VERSION ""

NS_ :

BS_:

BU_: ACU WPTC MCU OBC DCDC BMS VCU GW

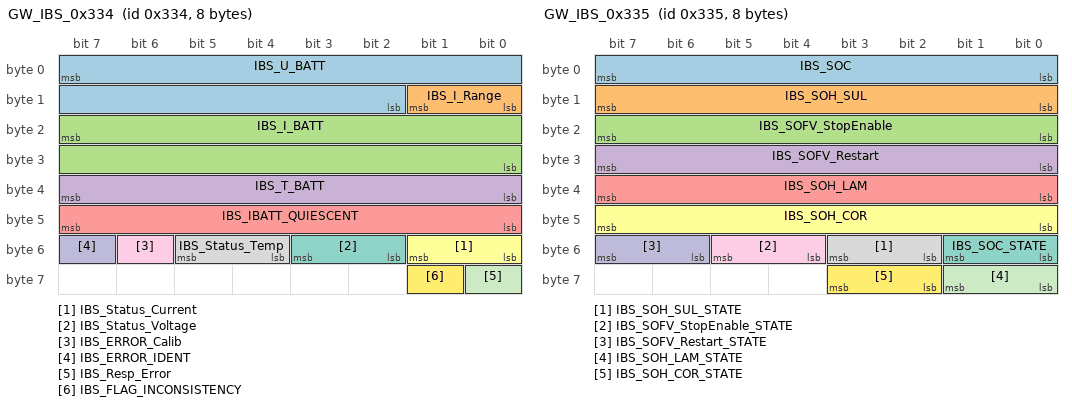
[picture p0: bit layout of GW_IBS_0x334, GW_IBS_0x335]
BO_ 820 GW_IBS_0x334: 8 GW
 SG_ IBS_U_BATT : 7|14@0+ (0.0009765625,3) [3|18] "V" VCU
 SG_ IBS_I_Range : 9|2@0+ (1,0) [0|3] "" Vector__XXX
 SG_ IBS_I_BATT : 23|16@0+ (1,-32768) [-32768|32766] "A" Vector__XXX
 SG_ IBS_T_BATT : 39|8@0+ (1,-40) [-40|105] "°C" Vector__XXX
 SG_ IBS_IBATT_QUIESCENT : 47|8@0+ (0.00390625,0) [0|0.984375] "A" Vector__XXX
 SG_ IBS_Status_Current : 49|2@0+ (1,0) [0|3] "" Vector__XXX
 SG_ IBS_Status_Voltage : 51|2@0+ (1,0) [0|3] "" VCU
 SG_ IBS_Status_Temp : 53|2@0+ (1,0) [0|3] "" Vector__XXX
 SG_ IBS_ERROR_Calib : 54|1@0+ (1,0) [0|1] "" Vector__XXX
 SG_ IBS_ERROR_IDENT : 55|1@0+ (1,0) [0|1] "" Vector__XXX
 SG_ IBS_Resp_Error : 56|1@0+ (1,0) [0|1] "" Vector__XXX
 SG_ IBS_FLAG_INCONSISTENCY : 57|1@0+ (1,0) [0|1] "" Vector__XXX

BO_ 821 GW_IBS_0x335: 8 GW
 SG_ IBS_SOC : 7|8@0+ (1,0) [0|100] "%" VCU
 SG_ IBS_SOH_SUL : 15|8@0+ (1,0) [0|100] "%" VCU
 SG_ IBS_SOFV_StopEnable : 23|8@0+ (0.0625,0) [0|15.875] "V" Vector__XXX
 SG_ IBS_SOFV_Restart : 31|8@0+ (0.0625,0) [0|15.875] "V" Vector__XXX
 SG_ IBS_SOH_LAM : 39|8@0+ (0.5,0) [0|127] "Ah" VCU
 SG_ IBS_SOH_COR : 47|8@0+ (0.0625,0) [0|15.875] "V" VCU
 SG_ IBS_SOC_STATE : 49|2@0+ (1,0) [0|3] "" VCU
 SG_ IBS_SOH_SUL_STATE : 51|2@0+ (1,0) [0|3] "" VCU
 SG_ IBS_SOFV_StopEnable_STATE : 53|2@0+ (1,0) [0|3] "" Vector__XXX
 SG_ IBS_SOFV_Restart_STATE : 55|2@0+ (1,0) [0|3] "" Vector__XXX
 SG_ IBS_SOH_LAM_STATE : 57|2@0+ (1,0) [0|3] "" VCU
 SG_ IBS_SOH_COR_STATE : 59|2@0+ (1,0) [0|3] "" VCU

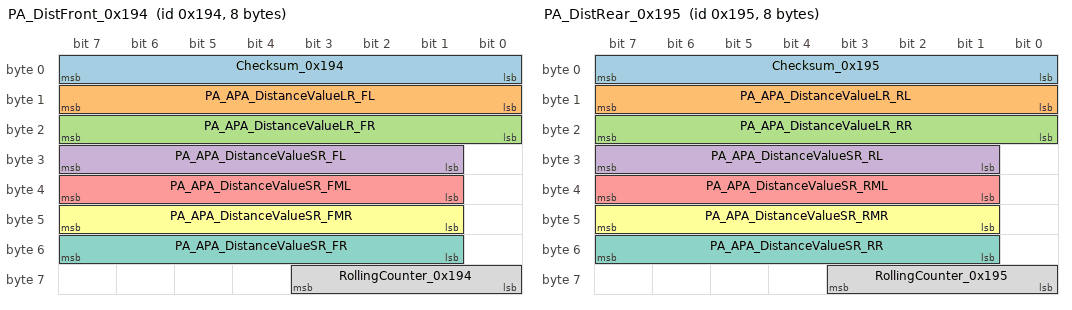
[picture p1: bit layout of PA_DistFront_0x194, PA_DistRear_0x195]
BO_ 404 PA_DistFront_0x194: 8 GW
 SG_ Checksum_0x194 : 7|8@0+ (1,0) [0|255] "" VCU
 SG_ PA_APA_DistanceValueLR_FL : 15|8@0+ (2,0) [0|500] "cm" VCU
 SG_ PA_APA_DistanceValueLR_FR : 23|8@0+ (2,0) [0|500] "cm" VCU
 SG_ PA_APA_DistanceValueSR_FL : 31|7@0+ (2,0) [0|250] "cm" VCU
 SG_ PA_APA_DistanceValueSR_FML : 39|7@0+ (2,0) [0|250] "cm" VCU
 SG_ PA_APA_DistanceValueSR_FMR : 47|7@0+ (2,0) [0|250] "cm" VCU
 SG_ PA_APA_DistanceValueSR_FR : 55|7@0+ (2,0) [0|250] "cm" VCU
 SG_ RollingCounter_0x194 : 59|4@0+ (1,0) [0|15] "" VCU

BO_ 405 PA_DistRear_0x195: 8 GW
 SG_ Checksum_0x195 : 7|8@0+ (1,0) [0|255] "" VCU
 SG_ PA_APA_DistanceValueLR_RL : 15|8@0+ (2,0) [0|500] "cm" VCU
 SG_ PA_APA_DistanceValueLR_RR : 23|8@0+ (2,0) [0|500] "cm" VCU
 SG_ PA_APA_DistanceValueSR_RL : 31|7@0+ (2,0) [0|250] "cm" VCU
 SG_ PA_APA_DistanceValueSR_RML : 39|7@0+ (2,0) [0|250] "cm" VCU
 SG_ PA_APA_DistanceValueSR_RMR : 47|7@0+ (2,0) [0|250] "cm" VCU
 SG_ PA_APA_DistanceValueSR_RR : 55|7@0+ (2,0) [0|250] "cm" VCU
 SG_ RollingCounter_0x195 : 59|4@0+ (1,0) [0|15] "" VCU

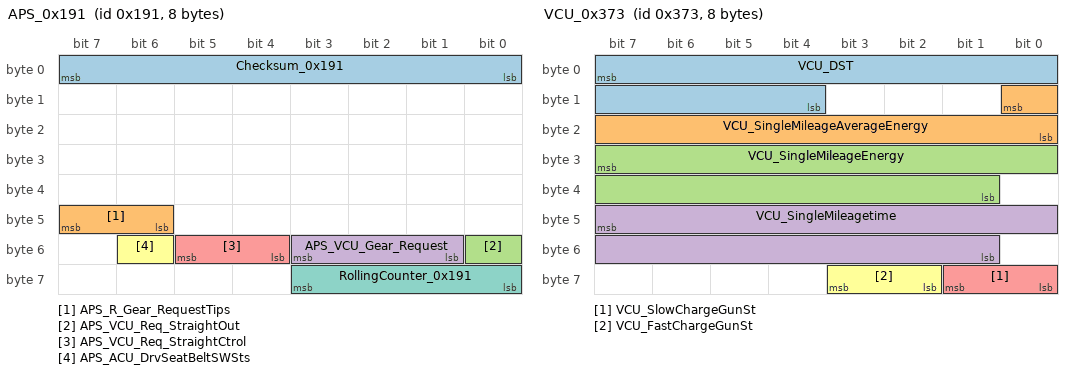
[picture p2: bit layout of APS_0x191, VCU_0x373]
BO_ 401 APS_0x191: 8 GW
 SG_ Checksum_0x191 : 7|8@0+ (1,0) [0|255] "" Vector__XXX
 SG_ APS_R_Gear_RequestTips : 47|2@0+ (1,0) [0|3] "" VCU
 SG_ APS_VCU_Req_StraightOut : 48|1@0+ (1,0) [0|1] "" VCU
 SG_ APS_VCU_Gear_Request : 51|3@0+ (1,0) [0|7] "" Vector__XXX
 SG_ APS_VCU_Req_StraightCtrol : 53|2@0+ (1,0) [0|3] "" VCU
 SG_ APS_ACU_DrvSeatBeltSWSts : 54|1@0+ (1,0) [0|1] "" Vector__XXX
 SG_ RollingCounter_0x191 : 59|4@0+ (1,0) [0|15] "" Vector__XXX

BO_ 599 AC_0x257: 8 GW
 SG_ AC_RemoteAC : 2|3@0+ (1,0) [0|7] "" VCU

BO_ 1323 VCU_0x52B: 8 VCU
 SG_ VCU_State0 : 7|8@0+ (1,0) [0|255] "" GW
 SG_ VCU_State1 : 15|8@0+ (1,0) [0|255] "" GW
 SG_ VCU_State2 : 23|8@0+ (1,0) [0|255] "" GW
 SG_ VCU_State3 : 31|8@0+ (1,0) [0|255] "" GW
 SG_ VCU_State4 : 39|8@0+ (1,0) [0|255] "" GW
 SG_ VCU_State5 : 47|8@0+ (1,0) [0|255] "" GW
 SG_ VCU_State6 : 55|8@0+ (1,0) [0|255] "" GW
 SG_ VCU_State7 : 63|8@0+ (1,0) [0|255] "" GW

BO_ 1325 VCU_0x52D: 8 VCU
 SG_ VCU_ErrorCode0 : 7|8@0+ (1,0) [0|255] "" GW
 SG_ VCU_ErrorCode1 : 15|8@0+ (1,0) [0|255] "" GW
 SG_ VCU_ErrorCode2 : 23|8@0+ (1,0) [0|255] "" GW
 SG_ VCU_ErrorCode3 : 31|8@0+ (1,0) [0|255] "" GW
 SG_ VCU_ErrorCode4 : 39|8@0+ (1,0) [0|255] "" GW
 SG_ VCU_ErrorCode5 : 47|8@0+ (1,0) [0|255] "" GW
 SG_ VCU_ErrorCode6 : 55|8@0+ (1,0) [0|255] "" GW
 SG_ VCU_ErrorCode7 : 63|8@0+ (1,0) [0|255] "" GW

BO_ 1326 VCU_0x52E: 8 VCU
 SG_ VCU_ErrorCode8 : 7|8@0+ (1,0) [0|255] "" GW
 SG_ VCU_ErrorCode9 : 15|8@0+ (1,0) [0|255] "" GW
 SG_ VCU_ErrorCode10 : 23|8@0+ (1,0) [0|255] "" GW
 SG_ VCU_ErrorCode11 : 31|8@0+ (1,0) [0|255] "" GW
 SG_ VCU_ErrorCode12 : 39|8@0+ (1,0) [0|255] "" GW
 SG_ VCU_ErrorCode13 : 47|8@0+ (1,0) [0|255] "" GW
 SG_ VCU_ErrorCode14 : 55|8@0+ (1,0) [0|255] "" GW
 SG_ VCU_ErrorCode15 : 63|8@0+ (1,0) [0|255] "" GW

BO_ 1327 VCU_0x52F: 8 VCU
 SG_ VCU_ErrorCode16 : 7|8@0+ (1,0) [0|255] "" GW
 SG_ VCU_ErrorCode17 : 15|8@0+ (1,0) [0|255] "" GW
 SG_ VCU_ErrorCode18 : 23|8@0+ (1,0) [0|255] "" GW
 SG_ VCU_ErrorCode19 : 31|8@0+ (1,0) [0|255] "" GW
 SG_ VCU_ErrorCode20 : 39|8@0+ (1,0) [0|255] "" GW
 SG_ VCU_ErrorCode21 : 47|8@0+ (1,0) [0|255] "" GW
 SG_ VCU_ErrorCode22 : 55|8@0+ (1,0) [0|255] "" GW
 SG_ VCU_ErrorCode23 : 63|8@0+ (1,0) [0|255] "" GW

BO_ 1379 VCU_0x563: 8 VCU
 SG_ VCU_CCOut : 23|1@0+ (1,0) [0|1] "" GW
 SG_ VCU_MotorPumpFB_PWM : 30|7@0+ (1,0) [0|100] "%" GW
 SG_ VCU_FastCharge_A : 31|1@0+ (1,0) [0|1] "" GW
 SG_ VCU_CC2 : 39|8@0+ (0.1,0) [0|25.4] "V" GW
 SG_ VCU_BatPumpFB_PWM : 47|7@0+ (1,0) [0|100] "%" GW

BO_ 596 AC_0x254: 8 GW
 SG_ AC_WindModeSts : 26|3@0+ (1,0) [0|7] "" VCU
 SG_ AC_OutTemperature : 47|8@0+ (0.5,-40) [-40|80] "℃" VCU

BO_ 597 AC_0x255: 8 GW
 SG_ AC_VCU_FanPWMReq : 46|7@0+ (1,0) [0|100] "%" VCU
 SG_ AC_VCU_APTCPwrReq : 54|7@0+ (0.1,0) [0|12.7] "" VCU
 SG_ AC_VCU_EACPwrReq : 62|7@0+ (0.1,0) [0|12.7] "" VCU

BO_ 800 EAC_0x320: 8 GW
 SG_ EAC_power : 6|7@0+ (0.1,0) [0|12.7] "KW" BMS,VCU
 SG_ EAC_Status : 15|2@0+ (1,0) [0|3] "" BMS,VCU

BO_ 806 APTC_0x326: 8 GW
 SG_ APTC_WorkSts : 1|2@0+ (1,0) [0|3] "" VCU
 SG_ APTC_WorkPower : 14|7@0+ (0.1,0) [0|12.7] "KW" VCU
 SG_ APTC_ErrorLevel : 49|2@0+ (1,0) [0|3] "" VCU

BO_ 582 MPC_0x246: 8 GW
 SG_ MPC_LKS_LeftVisualization : 35|3@0+ (1,0) [0|7] "" VCU
 SG_ MPC_LKS_RightVisualization : 38|3@0+ (1,0) [0|7] "" VCU

BO_ 144 BCM_0x90: 8 GW
 SG_ BCM_ReAuthRequest : 0|1@0+ (1,0) [0|1] "" MCU

BO_ 851 TBOX_0x353: 8 GW
 SG_ Checksum_0x353 : 7|8@0+ (1,0) [0|255] "" VCU
 SG_ TBOX_VCU_12vChargeReq : 16|1@0+ (1,0) [0|1] "" VCU
 SG_ TBOX_VCU_TimeCharge : 18|2@0+ (1,0) [0|3] "" VCU
 SG_ TBOX_ChargeDepthSet : 21|2@0+ (1,0) [0|3] "" VCU
 SG_ TBOX_VCU_RemoteChrgLock : 46|1@0+ (1,0) [0|1] "" VCU
 SG_ RollingCounter_0x353 : 59|4@0+ (1,0) [0|15] "" VCU

BO_ 881 VCU_0x371: 8 VCU
 SG_ VCU_instantaneous_Energy : 7|12@0+ (0.1,-204.7) [-204.7|204.6] "" GW
 SG_ VCU_instantaneous_EnergyUnit : 8|1@0+ (1,0) [0|1] "" GW
 SG_ VCU_TrailerMode : 9|1@0+ (1,0) [0|1] "" GW
 SG_ VCU_trip : 31|12@0+ (1,0) [0|4095] "km" GW
 SG_ VCU_ChargeIncreaseMileage : 50|11@0+ (1,0) [0|2046] "km" GW

BO_ 882 VCU_0x372: 8 VCU
 SG_ VCU_SubtotalAverageEnergy : 7|9@0+ (0.1,0) [0|51] "kwh/100km" GW
 SG_ VCU_SubtotalEnergy : 23|15@0+ (0.1,0) [0|3276.6] "kwh" GW
 SG_ VCU_Subtotaltime : 39|15@0+ (1,0) [0|32766] "min" GW
 SG_ VCU_ChargeIncreaseMileageSpeed : 51|12@0+ (1,0) [0|2046] "km/h" GW

BO_ 883 VCU_0x373: 8 VCU
 SG_ VCU_DST : 7|12@0+ (1,0) [0|4095] "km" GW
 SG_ VCU_SingleMileageAverageEnergy : 8|9@0+ (0.1,0) [0|51] "kwh/100km" GW
 SG_ VCU_SingleMileageEnergy : 31|15@0+ (0.1,0) [0|3276.5] "kwh" GW
 SG_ VCU_SingleMileagetime : 47|15@0+ (1,0) [0|32765] "min" GW
 SG_ VCU_SlowChargeGunSt : 57|2@0+ (1,0) [0|3] "" GW
 SG_ VCU_FastChargeGunSt : 59|2@0+ (1,0) [0|3] "" GW

BO_ 32 MCU_AuthReq_0x20: 8 MCU
 SG_ MCU_AuthReq_BCM_Code : 7|64@0+ (1,0) [0|255] "" GW

BO_ 33 BCM_AuthResp_0x21: 8 GW
 SG_ BCM_AuthResp_MCU_Code : 7|64@0+ (1,0) [0|255] "" MCU

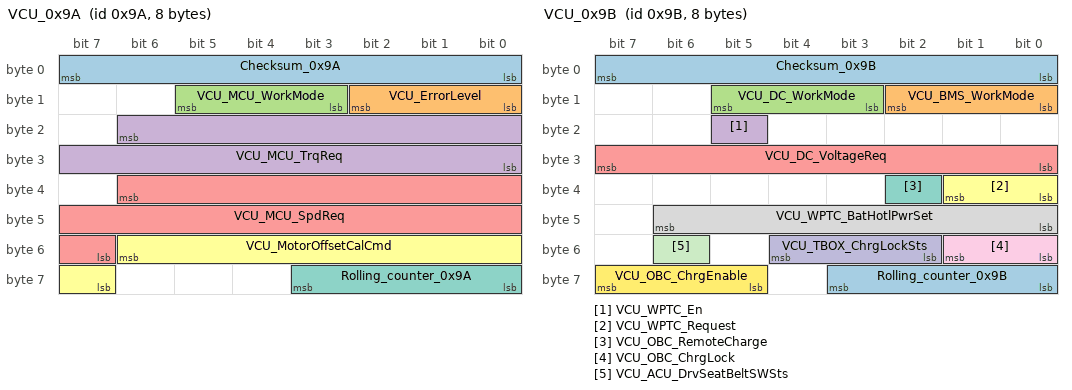
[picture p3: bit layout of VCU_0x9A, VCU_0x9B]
BO_ 154 VCU_0x9A: 8 VCU
 SG_ Checksum_0x9A : 7|8@0+ (1,0) [0|255] "" MCU,GW
 SG_ VCU_ErrorLevel : 10|3@0+ (1,0) [0|7] "" MCU,GW
 SG_ VCU_MCU_WorkMode : 13|3@0+ (1,0) [0|7] "" MCU,GW
 SG_ VCU_MCU_TrqReq : 22|15@0+ (0.1,-1000) [-1000|1000] "NM" MCU,GW
 SG_ VCU_MCU_SpdReq : 38|16@0+ (1,-32767) [-32767|32768] "RPM" MCU,GW
 SG_ VCU_MotorOffsetCalCmd : 54|8@0+ (1,0) [0|255] "" MCU,GW
 SG_ Rolling_counter_0x9A : 59|4@0+ (1,0) [0|15] "" MCU,GW

BO_ 155 VCU_0x9B: 8 VCU
 SG_ Checksum_0x9B : 7|8@0+ (1,0) [0|255] "" OBC,BMS,GW
 SG_ VCU_BMS_WorkMode : 10|3@0+ (1,0) [0|7] "" BMS,GW
 SG_ VCU_DC_WorkMode : 13|3@0+ (1,0) [0|7] "" DCDC,GW
 SG_ VCU_WPTC_En : 21|1@0+ (1,0) [0|1] "" WPTC,GW
 SG_ VCU_DC_VoltageReq : 31|8@0+ (0.1,0) [12|16] "V" DCDC,GW
 SG_ VCU_WPTC_Request : 33|2@0+ (1,0) [0|3] "" WPTC,GW
 SG_ VCU_OBC_RemoteCharge : 34|1@0+ (1,0) [0|1] "" OBC,GW
 SG_ VCU_WPTC_BatHotlPwrSet : 46|7@0+ (0.1,0) [0|12] "" WPTC,GW
 SG_ VCU_OBC_ChrgLock : 49|2@0+ (1,0) [0|3] "" OBC
 SG_ VCU_TBOX_ChrgLockSts : 52|3@0+ (1,0) [0|7] "" GW
 SG_ VCU_ACU_DrvSeatBeltSWSts : 54|1@0+ (1,0) [0|1] "" ACU
 SG_ VCU_OBC_ChrgEnable : 63|3@0+ (1,0) [0|7] "" OBC,GW
 SG_ Rolling_counter_0x9B : 59|4@0+ (1,0) [0|15] "" OBC,BMS,GW

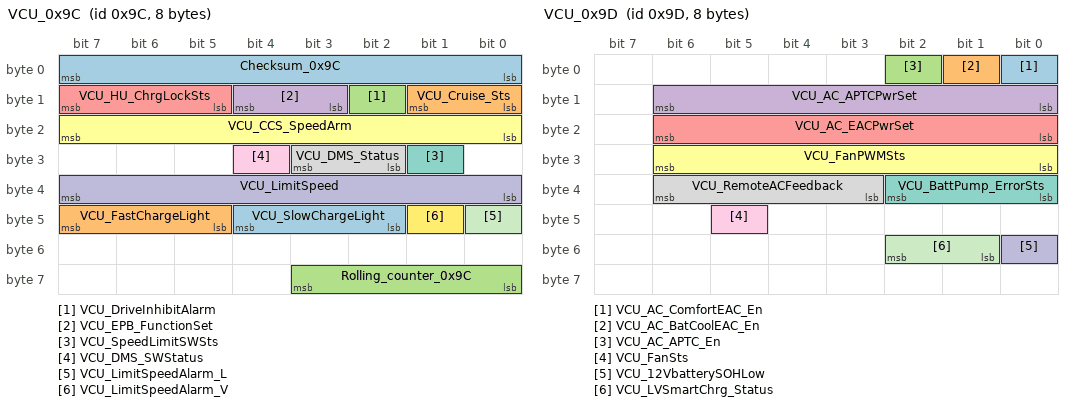
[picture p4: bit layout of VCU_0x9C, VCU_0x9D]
BO_ 156 VCU_0x9C: 8 VCU
 SG_ Checksum_0x9C : 7|8@0+ (1,0) [0|255] "" GW
 SG_ VCU_Cruise_Sts : 9|2@0+ (1,0) [0|3] "" GW
 SG_ VCU_DriveInhibitAlarm : 10|1@0+ (1,0) [0|1] "" GW
 SG_ VCU_EPB_FunctionSet : 12|2@0+ (1,0) [0|3] "" GW
 SG_ VCU_HU_ChrgLockSts : 15|3@0+ (1,0) [0|7] "" GW
 SG_ VCU_CCS_SpeedArm : 23|8@0+ (1,0) [0|200] "km/h" GW
 SG_ VCU_SpeedLimitSWSts : 25|1@0+ (1,0) [0|1] "" GW
 SG_ VCU_DMS_Status : 27|2@0+ (1,0) [0|3] "" GW
 SG_ VCU_DMS_SWStatus : 28|1@0+ (1,0) [0|1] "" GW
 SG_ VCU_LimitSpeed : 39|8@0+ (1,0) [0|200] "" GW
 SG_ VCU_LimitSpeedAlarm_L : 40|1@0+ (1,0) [0|1] "" GW
 SG_ VCU_LimitSpeedAlarm_V : 41|1@0+ (1,0) [0|1] "" GW
 SG_ VCU_SlowChargeLight : 44|3@0+ (1,0) [0|7] "" GW
 SG_ VCU_FastChargeLight : 47|3@0+ (1,0) [0|7] "" GW
 SG_ Rolling_counter_0x9C : 59|4@0+ (1,0) [0|15] "" GW

BO_ 157 VCU_0x9D: 8 VCU
 SG_ VCU_AC_ComfortEAC_En : 0|1@0+ (1,0) [0|1] "" GW
 SG_ VCU_AC_BatCoolEAC_En : 1|1@0+ (1,0) [0|1] "" GW
 SG_ VCU_AC_APTC_En : 2|1@0+ (1,0) [0|1] "" GW
 SG_ VCU_AC_APTCPwrSet : 14|7@0+ (0.1,0) [0|12.7] "KW" GW
 SG_ VCU_AC_EACPwrSet : 22|7@0+ (0.1,0) [0|12.7] "KW" GW
 SG_ VCU_FanPWMSts : 30|7@0+ (1,0) [0|100] "%" GW
 SG_ VCU_BattPump_ErrorSts : 34|3@0+ (1,0) [0|7] "" BMS,GW
 SG_ VCU_RemoteACFeedback : 38|4@0+ (1,0) [0|15] "" GW
 SG_ VCU_FanSts : 45|1@0+ (1,0) [0|1] "" GW
 SG_ VCU_12VbatterySOHLow : 48|1@0+ (1,0) [0|1] "" GW
 SG_ VCU_LVSmartChrg_Status : 50|2@0+ (1,0) [0|3] "" GW

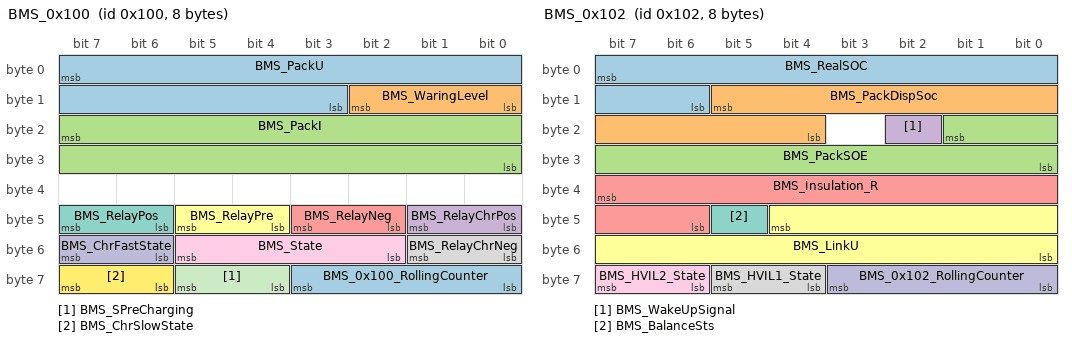
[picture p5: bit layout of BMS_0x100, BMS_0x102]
BO_ 256 BMS_0x100: 8 BMS
 SG_ BMS_PackU : 7|13@0+ (0.1,0) [0|800] "V" MCU,VCU,GW
 SG_ BMS_WaringLevel : 10|3@0+ (1,0) [0|7] "" VCU,GW
 SG_ BMS_PackI : 23|16@0+ (0.1,-1000) [-1000|1000] "A" VCU,GW
 SG_ BMS_RelayChrPos : 41|2@0+ (1,0) [0|3] "" VCU,GW
 SG_ BMS_RelayNeg : 43|2@0+ (1,0) [0|3] "" MCU,VCU,GW
 SG_ BMS_RelayPre : 45|2@0+ (1,0) [0|3] "" VCU,GW
 SG_ BMS_RelayPos : 47|2@0+ (1,0) [0|3] "" MCU,VCU,GW
 SG_ BMS_RelayChrNeg : 49|2@0+ (1,0) [0|3] "" VCU,GW
 SG_ BMS_State : 53|4@0+ (1,0) [0|15] "" VCU,GW
 SG_ BMS_ChrFastState : 55|2@0+ (1,0) [0|3] "" VCU,GW
 SG_ BMS_SPreCharging : 61|2@0+ (1,0) [0|3] "" GW
 SG_ BMS_ChrSlowState : 63|2@0+ (1,0) [0|3] "" VCU,GW
 SG_ BMS_0x100_RollingCounter : 59|4@0+ (1,0) [0|15] "" VCU,GW

BO_ 258 BMS_0x102: 8 BMS
 SG_ BMS_RealSOC : 7|10@0+ (0.1,0) [0|100] "%" VCU,GW
 SG_ BMS_PackDispSoc : 13|10@0+ (0.1,0) [0|100] "%" VCU,GW
 SG_ BMS_PackSOE : 17|10@0+ (0.1,0) [0|102.3] "kwh" VCU,GW
 SG_ BMS_WakeUpSignal : 18|1@0+ (1,0) [0|1] "" Vector__XXX
 SG_ BMS_Insulation_R : 39|10@0+ (1,0) [0|1000] "KΩ" GW
 SG_ BMS_LinkU : 44|13@0+ (0.1,0) [0|800] "V" VCU,GW
 SG_ BMS_BalanceSts : 45|1@0+ (1,0) [0|1] "" GW
 SG_ BMS_HVIL1_State : 61|2@0+ (1,0) [0|3] "" VCU,GW
 SG_ BMS_HVIL2_State : 63|2@0+ (1,0) [0|3] "" VCU,GW
 SG_ BMS_0x102_RollingCounter : 59|4@0+ (1,0) [0|15] "" VCU,GW

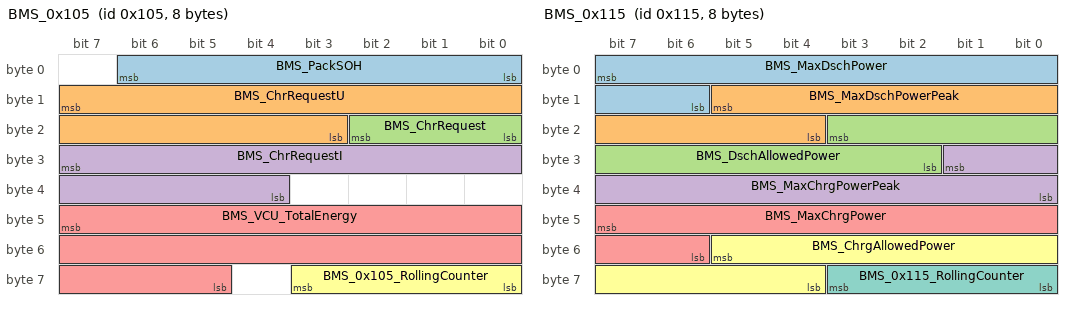
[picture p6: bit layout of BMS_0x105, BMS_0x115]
BO_ 261 BMS_0x105: 8 BMS
 SG_ BMS_PackSOH : 6|7@0+ (1,0) [0|100] "%" Vector__XXX
 SG_ BMS_ChrRequestU : 15|13@0+ (0.1,0) [0|800] "V" OBC,GW
 SG_ BMS_ChrRequest : 18|3@0+ (1,0) [0|7] "" OBC,GW
 SG_ BMS_ChrRequestI : 31|12@0+ (0.1,0) [0|400] "A" OBC,GW
 SG_ BMS_VCU_TotalEnergy : 47|19@0+ (1,0) [0|524286] "kwh" VCU,GW
 SG_ BMS_0x105_RollingCounter : 59|4@0+ (1,0) [0|15] "" OBC,GW

BO_ 274 BMS_0x112: 8 BMS
 SG_ BMS_MaxCellNo : 7|8@0+ (1,0) [0|255] "" GW
 SG_ BMS_MaxCellU : 15|13@0+ (1,0) [0|5000] "mV" GW
 SG_ BMS_MinCellNo : 31|8@0+ (1,0) [0|255] "" GW
 SG_ BMS_MinCellU : 39|13@0+ (1,0) [0|5000] "mV" GW
 SG_ BMS_CellVolDev : 55|12@0+ (1,0) [0|4000] "mV" GW
 SG_ BMS_0x112_RollingCounter : 59|4@0+ (1,0) [0|15] "" GW

BO_ 277 BMS_0x115: 8 BMS
 SG_ BMS_MaxDschPower : 7|10@0+ (0.25,0) [0|250] "KW" GW
 SG_ BMS_MaxDschPowerPeak : 13|10@0+ (0.25,0) [0|250] "KW" GW
 SG_ BMS_DschAllowedPower : 19|10@0+ (0.25,0) [0|250] "KW" VCU,GW
 SG_ BMS_MaxChrgPowerPeak : 25|10@0+ (0.25,0) [0|250] "KW" GW
 SG_ BMS_MaxChrgPower : 47|10@0+ (0.25,0) [0|250] "KW" GW
 SG_ BMS_ChrgAllowedPower : 53|10@0+ (0.25,0) [0|250] "KW" VCU,GW
 SG_ BMS_0x115_RollingCounter : 59|4@0+ (1,0) [0|15] "" GW

BO_ 278 BMS_0x116: 8 BMS
 SG_ BMS_CellOverVolWaring : 1|2@0+ (1,0) [0|3] "" GW
 SG_ BMS_CellUnderVolWaring : 3|2@0+ (1,0) [0|3] "" GW
 SG_ BMS_TempOverWaring : 5|2@0+ (1,0) [0|3] "" GW
 SG_ BMS_TempUnderWaring : 7|2@0+ (1,0) [0|3] "" GW
 SG_ BMS_CellVolDevWaring : 9|2@0+ (1,0) [0|3] "" GW
 SG_ BMS_TempDveWaring : 11|2@0+ (1,0) [0|3] "" GW
 SG_ BMS_BattOverVolWaring : 13|2@0+ (1,0) [0|3] "" GW
 SG_ BMS_BattUnderVolWaring : 15|2@0+ (1,0) [0|3] "" GW
 SG_ BMS_DCChargePlugTempOverHigh : 16|1@0+ (1,0) [0|1] "" GW
 SG_ BMS_DisCharOverCurr : 18|2@0+ (1,0) [0|3] "" GW
 SG_ BMS_RegenOverCurr : 20|2@0+ (1,0) [0|3] "" GW
 SG_ BMS_InnerCANTimeout : 21|1@0+ (1,0) [0|1] "" GW
 SG_ BMS_ISOWaring : 23|2@0+ (1,0) [0|3] "" VCU,GW
 SG_ BMS_BCUHWFault : 24|1@0+ (1,0) [0|1] "" GW
 SG_ BMS_NegRelayFault : 26|2@0+ (1,0) [0|3] "" GW
 SG_ BMS_PosRelayFault : 28|2@0+ (1,0) [0|3] "" GW
 SG_ BMS_PreRelayFault : 30|2@0+ (1,0) [0|3] "" GW
 SG_ BMS_LowVoltageMSD : 31|1@0+ (1,0) [0|1] "" GW
 SG_ BMS_CharPosRelayFault : 33|2@0+ (1,0) [0|3] "" GW
 SG_ BMS_CharNegRelayFault : 35|2@0+ (1,0) [0|3] "" GW
 SG_ BMS_BMUFault : 36|1@0+ (1,0) [0|1] "" GW
 SG_ BMS_VcuCANTimeout : 37|1@0+ (1,0) [0|1] "" GW
 SG_ BMS_BattHVDisaccord : 38|1@0+ (1,0) [0|1] "" GW
 SG_ BMS_SOClow : 41|2@0+ (1,0) [0|3] "" GW
 SG_ BMS_Mismatch : 42|1@0+ (1,0) [0|1] "" GW
 SG_ BMS_SOCOverHigh : 43|1@0+ (1,0) [0|1] "" GW
 SG_ BMS_BattOverCharge : 44|1@0+ (1,0) [0|1] "" GW
 SG_ BMS_SOCSkip : 45|1@0+ (1,0) [0|1] "" GW
 SG_ BMS_CGOverCurr : 46|1@0+ (1,0) [0|1] "" GW
 SG_ BMS_LowVoltageFault : 47|1@0+ (1,0) [0|1] "" GW
 SG_ BMS_LiquidLeak : 48|1@0+ (1,0) [0|1] "" GW
 SG_ BMS_CrashFault : 49|1@0+ (1,0) [0|1] "" GW
 SG_ BMS_ThermRunAway : 50|1@0+ (1,0) [0|1] "" GW
 SG_ BMS_Maintenance : 52|2@0+ (1,0) [0|3] "" GW
 SG_ BMS_BusbarTempOverWaring : 53|1@0+ (1,0) [0|1] "" GW
 SG_ BMS_FuseFault : 54|1@0+ (1,0) [0|1] "" GW
 SG_ BMS_CurrSensorFault : 61|2@0+ (1,0) [0|3] "" GW
 SG_ BMS_0x116_RollingCounter : 59|4@0+ (1,0) [0|15] "" GW

BO_ 276 BMS_0x114: 8 BMS
 SG_ BMS_thermalControlReq : 10|3@0+ (1,0) [0|7] "" VCU
 SG_ BMS_ThermalCtrlTargetTemp : 23|8@0+ (1,-40) [-40|85] "℃" VCU
 SG_ BMS_InputWaterTemp : 31|8@0+ (0.5,-40) [-40|85] "℃" VCU
 SG_ BMS_OutputWaterTemp : 39|8@0+ (0.5,-40) [-40|85] "℃" VCU
 SG_ BMS_BattThermalReqLvl : 47|8@0+ (1,0) [0|15] "" VCU
 SG_ BMS_0x114_RollingCounter : 59|4@0+ (1,0) [0|15] "" VCU

BO_ 279 VCU_0x117: 8 VCU
 SG_ VCU_thermalControlReq : 10|3@0+ (1,0) [0|7] "" GW
 SG_ VCU_InputWaterTemp : 31|8@0+ (0.5,-40) [-40|85] "℃" GW
 SG_ VCU_OutputWaterTemp : 39|8@0+ (0.5,-40) [-40|85] "℃" GW
 SG_ VCU_BattThermalReqLvl : 47|8@0+ (1,0) [0|15] "" GW
 SG_ VCU_RecoTiming : 54|7@0+ (1,0) [0|120] "" GW

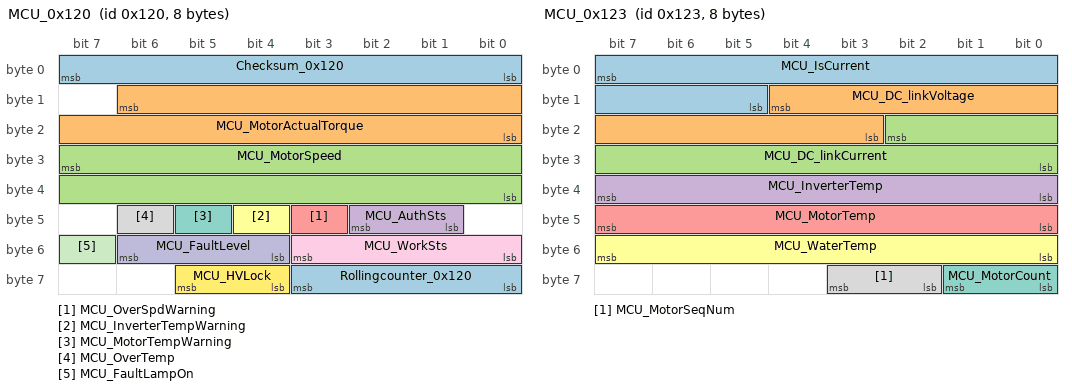
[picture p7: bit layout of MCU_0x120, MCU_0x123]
BO_ 288 MCU_0x120: 8 MCU
 SG_ Checksum_0x120 : 7|8@0+ (1,0) [0|255] "" GW
 SG_ MCU_MotorActualTorque : 14|15@0+ (0.1,-1000) [-1000|1000] "NM" GW
 SG_ MCU_MotorSpeed : 31|16@0+ (1,-32767) [-32767|32768] "RPM" GW
 SG_ MCU_AuthSts : 42|2@0+ (1,0) [0|3] "" GW
 SG_ MCU_OverSpdWarning : 43|1@0+ (1,0) [0|1] "" GW
 SG_ MCU_InverterTempWarning : 44|1@0+ (1,0) [0|1] "" GW
 SG_ MCU_MotorTempWarning : 45|1@0+ (1,0) [0|1] "" GW
 SG_ MCU_OverTemp : 46|1@0+ (1,0) [0|1] "" GW
 SG_ MCU_WorkSts : 51|4@0+ (1,0) [0|15] "" GW
 SG_ MCU_FaultLevel : 54|3@0+ (1,0) [0|7] "" GW
 SG_ MCU_FaultLampOn : 55|1@0+ (1,0) [0|1] "" GW
 SG_ MCU_HVLock : 61|2@0+ (1,0) [0|3] "" GW
 SG_ Rollingcounter_0x120 : 59|4@0+ (1,0) [0|15] "" GW

BO_ 289 ESP_0x121: 8 GW
 SG_ Checksum_0x121 : 7|8@0+ (1,0) [0|255] "" VCU
 SG_ ESP_VehicleSpeed : 11|12@0+ (0.05625,0) [0|230.28749] "kph" ACU,MCU,BMS,VCU
 SG_ ESP_VehicleSpeed_Valid : 12|1@0+ (1,0) [0|1] "" ACU,MCU,BMS,VCU
 SG_ ESP_OFF : 13|1@0+ (1,0) [0|1] "" VCU
 SG_ ESP_ABS_Error : 14|1@0+ (1,0) [0|1] "" VCU
 SG_ ESP_ABS_Intervention : 15|1@0+ (1,0) [0|1] "" VCU
 SG_ ESP_VDC_TCS_Error : 24|1@0+ (1,0) [0|1] "" VCU
 SG_ ESP_EBD_Error : 25|1@0+ (1,0) [0|1] "" VCU
 SG_ ESP_VDC_Intervention : 26|1@0+ (1,0) [0|1] "" VCU
 SG_ ESP_TCS_Intervention : 27|1@0+ (1,0) [0|1] "" VCU
 SG_ ESP_EBD_Intervention : 28|1@0+ (1,0) [0|1] "" VCU
 SG_ ESP_HDC_Status : 31|2@0+ (1,0) [0|3] "" Vector__XXX
 SG_ ESP_HDC_Available : 32|1@0+ (1,0) [0|1] "" Vector__XXX
 SG_ ESP_EPBFailstatus : 34|1@0+ (1,0) [0|1] "" VCU
 SG_ ESP_EPBStatus : 37|3@0+ (1,0) [0|7] "" VCU
 SG_ ESP_VehicleStop : 38|1@0+ (1,0) [0|1] "" VCU
 SG_ ESP_VehicleStop_Valid : 39|1@0+ (1,0) [0|1] "" VCU
 SG_ ESP_MasterCyPressureCmp : 47|8@0+ (1,0) [0|255] "bar" VCU
 SG_ ESP_MasterCyPressure_Valid : 48|1@0+ (1,0) [0|1] "" VCU
 SG_ ESP_WheelCyBrakeForce_Exist : 49|1@0+ (1,0) [0|1] "" Vector__XXX
 SG_ ESP_ESPLamp : 50|1@0+ (1,0) [0|1] "" Vector__XXX
 SG_ ESP_AVHstandbyStatus : 51|1@0+ (1,0) [0|1] "" Vector__XXX
 SG_ ESP_AVHActive : 52|1@0+ (1,0) [0|1] "" VCU
 SG_ ESP_AVH_availalbe : 53|1@0+ (1,0) [0|1] "" Vector__XXX
 SG_ ESP_HHC_Available : 54|1@0+ (1,0) [0|1] "" Vector__XXX
 SG_ ESP_HHCActive : 55|1@0+ (1,0) [0|1] "" VCU
 SG_ RollingCounter_0x121 : 59|4@0+ (1,0) [0|15] "" VCU

BO_ 290 MCU_0x122: 8 MCU
 SG_ Checksum_0x122 : 7|8@0+ (1,0) [0|255] "" GW
 SG_ MCU_MaxAvailableTorque : 15|11@0+ (1,-1023) [-1023|1024] "NM" GW
 SG_ MCU_MinAvailableTorque : 18|11@0+ (1,-1023) [-1023|1024] "NM" GW
 SG_ MCU_DeratingTempCoolant : 35|1@0+ (1,0) [0|1] "" GW
 SG_ MCU_damping_En : 39|1@0+ (1,0) [0|1] "" GW
 SG_ MCU_DeratingTrqMin : 40|1@0+ (1,0) [0|1] "" GW
 SG_ MCU_DeratingTrqMax : 41|1@0+ (1,0) [0|1] "" GW
 SG_ MCU_DeratingOvrUdc : 42|1@0+ (1,0) [0|1] "" GW
 SG_ MCU_DeratingUndrUdc : 43|1@0+ (1,0) [0|1] "" GW
 SG_ MCU_DeratingOvrIdc : 44|1@0+ (1,0) [0|1] "" GW
 SG_ MCU_DeratingUndrIdc : 45|1@0+ (1,0) [0|1] "" GW
 SG_ MCU_DeratingTempEm : 46|1@0+ (1,0) [0|1] "" GW
 SG_ MCU_DeratingTempInv : 47|1@0+ (1,0) [0|1] "" GW
 SG_ Rollingcounter_0x122 : 59|4@0+ (1,0) [0|15] "" GW
 SG_ MCU_MotorTorqueDeratingFlg : 61|1@0+ (1,0) [0|1] "" GW
 SG_ MCU_HVReady : 62|1@0+ (1,0) [0|1] "" GW
 SG_ MCU_DeratingOverSpd : 63|1@0+ (1,0) [0|1] "" GW

BO_ 291 MCU_0x123: 8 MCU
 SG_ MCU_IsCurrent : 7|11@0+ (0.5,0) [0|1023.5] "" GW
 SG_ MCU_DC_linkVoltage : 12|10@0+ (1,0) [0|1023] "V" BMS,GW
 SG_ MCU_DC_linkCurrent : 18|11@0+ (1,-1023) [-1023|1024] "A" BMS,GW
 SG_ MCU_InverterTemp : 39|8@0+ (1,-40) [-40|215] "℃" GW
 SG_ MCU_MotorTemp : 47|8@0+ (1,-40) [-40|215] "℃" GW
 SG_ MCU_WaterTemp : 55|8@0+ (1,-40) [-40|215] "℃" GW
 SG_ MCU_MotorCount : 57|2@0+ (1,0) [1|3] "个" GW
 SG_ MCU_MotorSeqNum : 59|2@0+ (1,0) [1|3] "" GW

BO_ 292 MCU_0x124: 8 MCU
 SG_ MCU_DBCTempU : 7|8@0+ (1,-40) [-40|215] "degC" GW
 SG_ MCU_DBCTempV : 15|8@0+ (1,-40) [-40|215] "degC" GW
 SG_ MCU_DBCTempW : 23|8@0+ (1,-40) [-40|215] "degC" GW
 SG_ MCU_RotorTemp : 31|8@0+ (1,-40) [-40|215] "℃" GW
 SG_ MCU_MotoroffsetSts : 36|2@0+ (1,0) [0|3] "" GW
 SG_ MCU_stGateDrv : 39|2@0+ (1,0) [0|3] "" GW
 SG_ MCU_Motoroffset : 43|12@0+ (0.0878906,0) [0|359.9120178] "度" GW

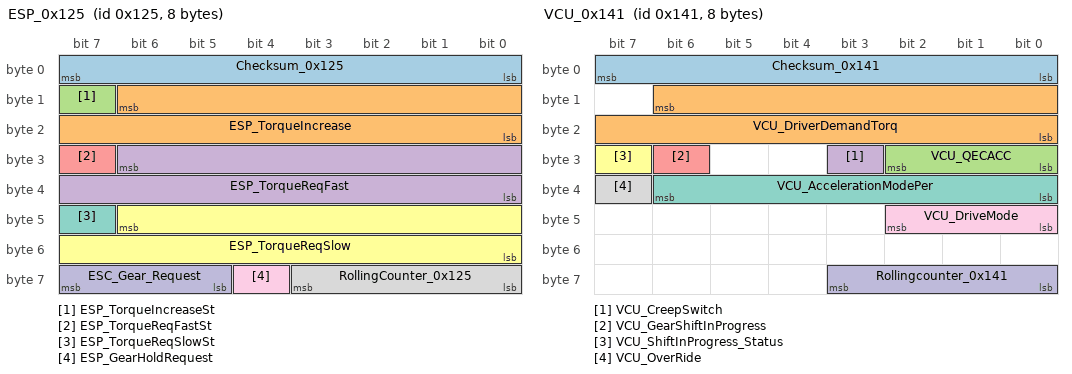
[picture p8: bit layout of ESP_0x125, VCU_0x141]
BO_ 293 ESP_0x125: 8 GW
 SG_ Checksum_0x125 : 7|8@0+ (1,0) [0|255] "" VCU
 SG_ ESP_TorqueIncrease : 14|15@0+ (0.1,-1000) [-1000|1000] "NM" VCU
 SG_ ESP_TorqueIncreaseSt : 15|1@0+ (1,0) [0|1] "" VCU
 SG_ ESP_TorqueReqFast : 30|15@0+ (0.1,-1000) [-1000|1000] "NM" VCU
 SG_ ESP_TorqueReqFastSt : 31|1@0+ (1,0) [0|1] "" VCU
 SG_ ESP_TorqueReqSlow : 46|15@0+ (0.1,-1000) [-1000|1000] "NM" Vector__XXX
 SG_ ESP_TorqueReqSlowSt : 47|1@0+ (1,0) [0|1] "" Vector__XXX
 SG_ RollingCounter_0x125 : 59|4@0+ (1,0) [0|15] "" VCU
 SG_ ESP_GearHoldRequest : 60|1@0+ (1,0) [0|1] "" Vector__XXX
 SG_ ESC_Gear_Request : 63|3@0+ (1,0) [0|7] "" VCU

BO_ 320 VCU_0x140: 8 VCU
 SG_ Checksum_0x140 : 7|8@0+ (1,0) [0|255] "" GW
 SG_ VCU_CurrentMotorTorq : 14|15@0+ (0.1,-1000) [-1000|1000] "NM" GW
 SG_ VCU_MaxMotorTorque : 30|15@0+ (0.1,-1000) [-1000|1000] "NM" GW
 SG_ VCU_MinMotorTorque : 46|15@0+ (0.1,-1000) [-1000|1000] "NM" GW
 SG_ Rollingcounter_0x140 : 59|4@0+ (1,0) [0|15] "" GW

BO_ 321 VCU_0x141: 8 VCU
 SG_ Checksum_0x141 : 7|8@0+ (1,0) [0|255] "" GW
 SG_ VCU_DriverDemandTorq : 14|15@0+ (0.1,-1000) [-1000|1000] "NM" GW
 SG_ VCU_QECACC : 26|3@0+ (1,0) [0|7] "" GW
 SG_ VCU_CreepSwitch : 27|1@0+ (1,0) [0|1] "" GW
 SG_ VCU_GearShiftInProgress : 30|1@0+ (1,0) [0|1] "" GW
 SG_ VCU_ShiftInProgress_Status : 31|1@0+ (1,0) [0|1] "" GW
 SG_ VCU_AccelerationModePer : 38|7@0+ (1,0) [0|100] "" GW
 SG_ VCU_OverRide : 39|1@0+ (1,0) [0|1] "" GW
 SG_ VCU_DriveMode : 42|3@0+ (1,0) [0|7] "" GW
 SG_ Rollingcounter_0x141 : 59|4@0+ (1,0) [0|15] "" GW

BO_ 336 VCU_0x150: 8 VCU
 SG_ Checksum_0x150 : 7|8@0+ (1,0) [0|255] "" GW
 SG_ VCU_GearLeverPos : 10|3@0+ (1,0) [0|7] "" GW
 SG_ VCU_TortoiseLamp : 11|1@0+ (1,0) [0|1] "" GW
 SG_ VCU_Charge_Connect : 13|2@0+ (1,0) [0|3] "" GW
 SG_ VCU_12VbatteryError : 14|1@0+ (1,0) [0|1] "" GW
 SG_ VCU_ReadySts : 15|1@0+ (1,0) [0|1] "" GW
 SG_ VCU_MotorPumpError : 16|1@0+ (1,0) [0|1] "" GW
 SG_ VCU_VacuumSysFaultLamp : 17|1@0+ (1,0) [0|1] "" GW
 SG_ VCU_GearP_EnterWarning : 18|1@0+ (1,0) [0|1] "" GW
 SG_ VCU_VehicleSysFaultLamp : 19|1@0+ (1,0) [0|1] "" GW
 SG_ VCU_BattPumpError : 20|1@0+ (1,0) [0|1] "" GW
 SG_ VCU_DriveableAlarm : 21|1@0+ (1,0) [0|1] "" GW
 SG_ VCU_GearFlashReq : 23|2@0+ (1,0) [0|3] "" GW
 SG_ VCU_EnergyRecoveryPer : 31|7@0+ (1,0) [0|100] "%" GW
 SG_ VCU_Mileage : 39|10@0+ (1,0) [0|1022] "KM" GW
 SG_ VCU_PowerConsumption : 40|9@0+ (0.1,0) [0|51] "Kwh/100km" GW
 SG_ VCU_MotorLoopCoolantLow : 41|1@0+ (1,0) [0|1] "" GW
 SG_ VCU_BatLoopCoolantLow : 42|1@0+ (1,0) [0|1] "" GW
 SG_ VCU_ChargeDepthSts : 44|2@0+ (1,0) [0|3] "" GW
 SG_ VCU_CloolantHighAlarm : 45|1@0+ (1,0) [0|1] "" GW
 SG_ VCU_TBOX_SlowChargeSt : 63|4@0+ (1,0) [0|15] "" GW
 SG_ Rollingcounter_0x150 : 59|4@0+ (1,0) [0|15] "" GW

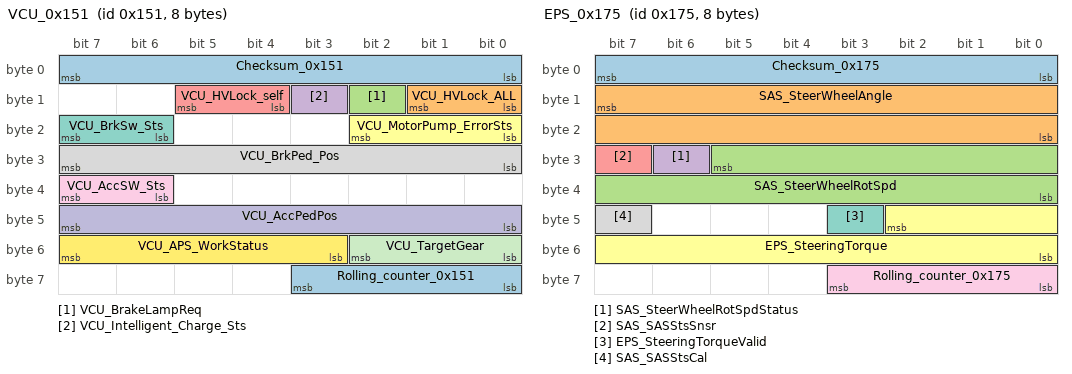
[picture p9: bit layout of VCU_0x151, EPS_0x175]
BO_ 337 VCU_0x151: 8 VCU
 SG_ Checksum_0x151 : 7|8@0+ (1,0) [0|255] "" GW
 SG_ VCU_HVLock_ALL : 9|2@0+ (1,0) [0|3] "" GW
 SG_ VCU_BrakeLampReq : 10|1@0+ (1,0) [0|1] "" GW
 SG_ VCU_Intelligent_Charge_Sts : 11|1@0+ (1,0) [0|1] "" GW
 SG_ VCU_HVLock_self : 13|2@0+ (1,0) [0|3] "" GW
 SG_ VCU_MotorPump_ErrorSts : 18|3@0+ (1,0) [0|7] "" BMS,GW
 SG_ VCU_BrkSw_Sts : 23|2@0+ (1,0) [0|3] "" GW
 SG_ VCU_BrkPed_Pos : 31|8@0+ (1,0) [0|100] "%" GW
 SG_ VCU_AccSW_Sts : 39|2@0+ (1,0) [0|3] "" GW
 SG_ VCU_AccPedPos : 47|8@0+ (0.5,0) [0|100] "%" GW
 SG_ VCU_TargetGear : 50|3@0+ (1,0) [0|7] "" GW
 SG_ VCU_APS_WorkStatus : 55|5@0+ (1,0) [0|31] "" GW
 SG_ Rolling_counter_0x151 : 59|4@0+ (1,0) [0|15] "" GW

BO_ 373 EPS_0x175: 8 GW
 SG_ Checksum_0x175 : 7|8@0+ (1,0) [0|255] "" VCU
 SG_ SAS_SteerWheelAngle : 15|16@0+ (0.0238,-780) [-780|780] "deg" VCU
 SG_ SAS_SteerWheelRotSpd : 29|14@0+ (0.125,-1024) [-1024|1023] "deg/s" VCU
 SG_ SAS_SteerWheelRotSpdStatus : 30|1@0+ (1,0) [0|1] "" VCU
 SG_ SAS_SASStsSnsr : 31|1@0+ (1,0) [0|1] "" VCU
 SG_ EPS_SteeringTorque : 42|11@0+ (0.01,-10.24) [-10.24|10.23] "Nm" VCU
 SG_ EPS_SteeringTorqueValid : 43|1@0+ (1,0) [0|1] "" VCU
 SG_ SAS_SASStsCal : 47|1@0+ (1,0) [0|1] "" VCU
 SG_ Rolling_counter_0x175 : 59|4@0+ (1,0) [0|15] "" VCU

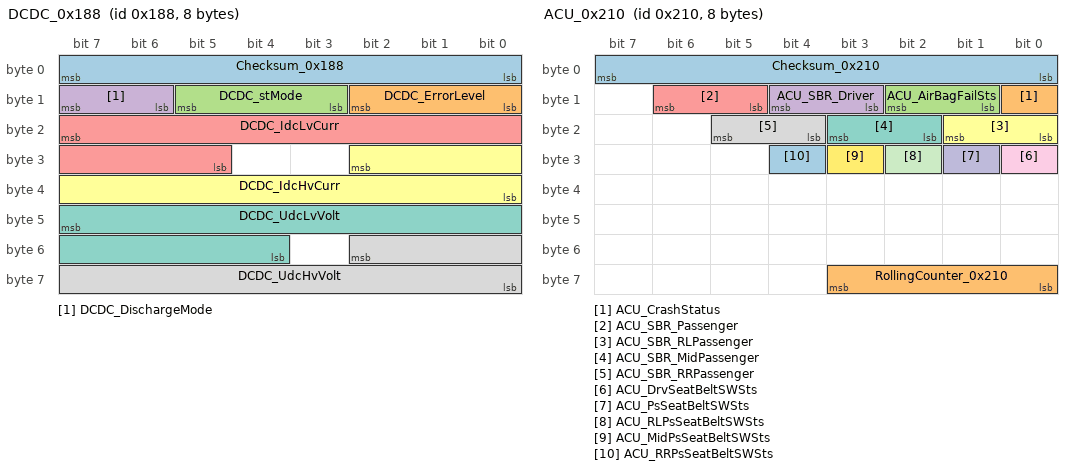
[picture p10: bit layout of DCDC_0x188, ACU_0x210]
BO_ 392 DCDC_0x188: 8 DCDC
 SG_ Checksum_0x188 : 7|8@0+ (1,0) [0|255] "" GW
 SG_ DCDC_ErrorLevel : 10|3@0+ (1,0) [0|7] "" VCU,GW
 SG_ DCDC_stMode : 13|3@0+ (1,0) [0|7] "" VCU,GW
 SG_ DCDC_DischargeMode : 15|2@0+ (1,0) [0|3] "" VCU,GW
 SG_ DCDC_IdcLvCurr : 23|11@0+ (0.2,0) [0|400] "A" VCU,GW
 SG_ DCDC_IdcHvCurr : 26|11@0+ (0.1,0) [0|100] "A" BMS,VCU,GW
 SG_ DCDC_UdcLvVolt : 47|12@0+ (0.1,0) [0|40] "V" VCU,GW
 SG_ DCDC_UdcHvVolt : 50|11@0+ (1,0) [0|600] "V" BMS,VCU,GW

BO_ 528 ACU_0x210: 8 ACU
 SG_ Checksum_0x210 : 7|8@0+ (1,0) [0|255] "" BMS,GW
 SG_ ACU_CrashStatus : 8|1@0+ (1,0) [0|1] "" MCU,BMS,VCU,GW
 SG_ ACU_AirBagFailSts : 10|2@0+ (1,0) [0|3] "" GW
 SG_ ACU_SBR_Driver : 12|2@0+ (1,0) [0|3] "" GW
 SG_ ACU_SBR_Passenger : 14|2@0+ (1,0) [0|3] "" GW
 SG_ ACU_SBR_RLPassenger : 17|2@0+ (1,0) [0|3] "" GW
 SG_ ACU_SBR_MidPassenger : 19|2@0+ (1,0) [0|3] "" GW
 SG_ ACU_SBR_RRPassenger : 21|2@0+ (1,0) [0|3] "" GW
 SG_ ACU_DrvSeatBeltSWSts : 24|1@0+ (1,0) [0|1] "" VCU,GW
 SG_ ACU_PsSeatBeltSWSts : 25|1@0+ (1,0) [0|1] "" GW
 SG_ ACU_RLPsSeatBeltSWSts : 26|1@0+ (1,0) [0|1] "" GW
 SG_ ACU_MidPsSeatBeltSWSts : 27|1@0+ (1,0) [0|1] "" GW
 SG_ ACU_RRPsSeatBeltSWSts : 28|1@0+ (1,0) [0|1] "" GW
 SG_ RollingCounter_0x210 : 59|4@0+ (1,0) [0|15] "" BMS,GW

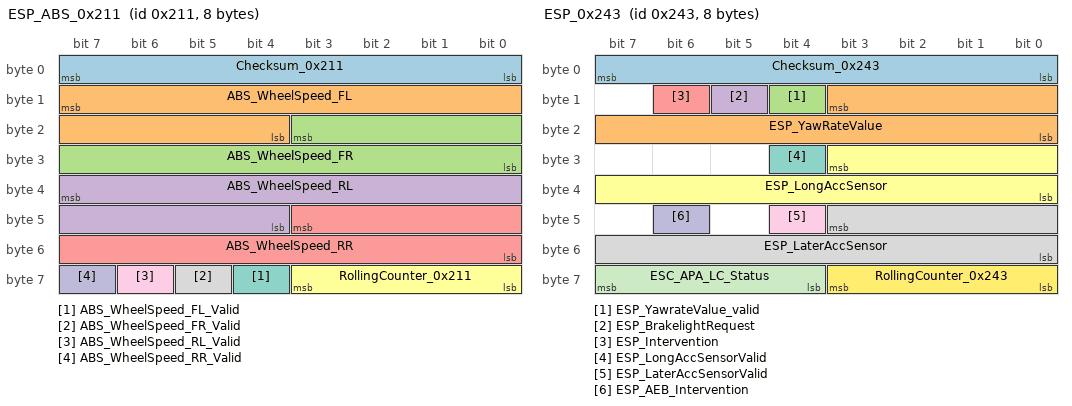
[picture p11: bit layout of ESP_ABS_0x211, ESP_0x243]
BO_ 529 ESP_ABS_0x211: 8 GW
 SG_ Checksum_0x211 : 7|8@0+ (1,0) [0|255] "" VCU
 SG_ ABS_WheelSpeed_FL : 15|12@0+ (0.05625,0) [0|230.28749] "kph" VCU
 SG_ ABS_WheelSpeed_FR : 19|12@0+ (0.05625,0) [0|230.28749] "kph" VCU
 SG_ ABS_WheelSpeed_RL : 39|12@0+ (0.05625,0) [0|230.28749] "kph" VCU
 SG_ ABS_WheelSpeed_RR : 43|12@0+ (0.05625,0) [0|230.28749] "kph" VCU
 SG_ RollingCounter_0x211 : 59|4@0+ (1,0) [0|15] "" VCU
 SG_ ABS_WheelSpeed_FL_Valid : 60|1@0+ (1,0) [0|1] "" VCU
 SG_ ABS_WheelSpeed_FR_Valid : 61|1@0+ (1,0) [0|1] "" VCU
 SG_ ABS_WheelSpeed_RL_Valid : 62|1@0+ (1,0) [0|1] "" VCU
 SG_ ABS_WheelSpeed_RR_Valid : 63|1@0+ (1,0) [0|1] "" VCU

BO_ 532 ESP_0x214: 8 GW
 SG_ Checksum_0x214 : 7|8@0+ (1,0) [0|255] "" VCU
 SG_ ESP_WheelDirection_FL : 9|2@0+ (1,0) [0|3] "" VCU
 SG_ ESP_WheelDirection_FL_Valid : 10|1@0+ (1,0) [0|1] "kph" VCU
 SG_ ESP_WheelDirection_FR : 12|2@0+ (1,0) [0|3] "" VCU
 SG_ ESP_WheelDirection_FR_Valid : 13|1@0+ (1,0) [0|1] "" VCU
 SG_ ESP_WheelDirection_RL : 15|2@0+ (1,0) [0|3] "" VCU
 SG_ ESP_WheelDirection_RL_Valid : 16|1@0+ (1,0) [0|1] "" VCU
 SG_ ESP_WheelDirection_RR : 18|2@0+ (1,0) [0|3] "" VCU
 SG_ ESP_WheelDirection_RR_Valid : 19|1@0+ (1,0) [0|1] "" VCU
 SG_ ESP_CDD_Intervention : 20|1@0+ (1,0) [0|1] "" VCU
 SG_ ESP_CDD_Available : 21|1@0+ (1,0) [0|1] "" VCU
 SG_ ESP_CDD_Error : 22|1@0+ (1,0) [0|1] "" Vector__XXX
 SG_ ESP_CDDTempOff : 23|1@0+ (1,0) [0|1] "" Vector__XXX
 SG_ ESP_WheelBrakeForce : 31|16@0+ (1,0) [0|30000] "N" Vector__XXX
 SG_ ESP_VLC_EngTrqReq : 46|15@0+ (0.1,-1000) [-1000|1000] "NM" VCU
 SG_ ESP_VLC_EngTrqReqActive : 47|1@0+ (1,0) [0|1] "" VCU
 SG_ RollingCounter_0x214 : 59|4@0+ (1,0) [0|15] "" VCU
 SG_ ESP_VLC_Intervention : 60|1@0+ (1,0) [0|1] "" VCU
 SG_ ESP_VLC_Error : 61|1@0+ (1,0) [0|1] "" VCU
 SG_ ESP_VLC_Available : 62|1@0+ (1,0) [0|1] "" Vector__XXX
 SG_ ESP_APA_CDD_active : 63|1@0+ (1,0) [0|1] "" VCU

BO_ 579 ESP_0x243: 8 GW
 SG_ Checksum_0x243 : 7|8@0+ (1,0) [0|255] "" VCU
 SG_ ESP_YawRateValue : 11|12@0+ (0.05,-75) [-75|75] "°/s" Vector__XXX
 SG_ ESP_YawrateValue_valid : 12|1@0+ (1,0) [0|1] "" Vector__XXX
 SG_ ESP_BrakelightRequest : 13|1@0+ (1,0) [0|1] "" Vector__XXX
 SG_ ESP_Intervention : 14|1@0+ (1,0) [0|1] "" Vector__XXX
 SG_ ESP_LongAccSensor : 27|12@0+ (0.01,-20) [-20|20] "m/s^2" VCU
 SG_ ESP_LongAccSensorValid : 28|1@0+ (1,0) [0|1] "" VCU
 SG_ ESP_LaterAccSensor : 43|12@0+ (0.01,-20) [-20|20] "m/s^2" VCU
 SG_ ESP_LaterAccSensorValid : 44|1@0+ (1,0) [0|1] "" VCU
 SG_ ESP_AEB_Intervention : 46|1@0+ (1,0) [0|1] "" VCU
 SG_ ESC_APA_LC_Status : 63|4@0+ (1,0) [0|15] "" VCU
 SG_ RollingCounter_0x243 : 59|4@0+ (1,0) [0|15] "" VCU

BO_ 642 SCM_0x282: 8 GW
 SG_ Checksum_0x282 : 7|8@0+ (1,0) [0|255] "" VCU
 SG_ SCM_CC_Switch : 12|2@0+ (1,0) [0|3] "" VCU
 SG_ SCM_Res_Set_Switch : 14|2@0+ (1,0) [0|3] "" VCU
 SG_ SCM_PRND_req : 34|3@0+ (1,0) [0|7] "" VCU
 SG_ Counter_0x282 : 59|4@0+ (1,0) [0|15] "" VCU

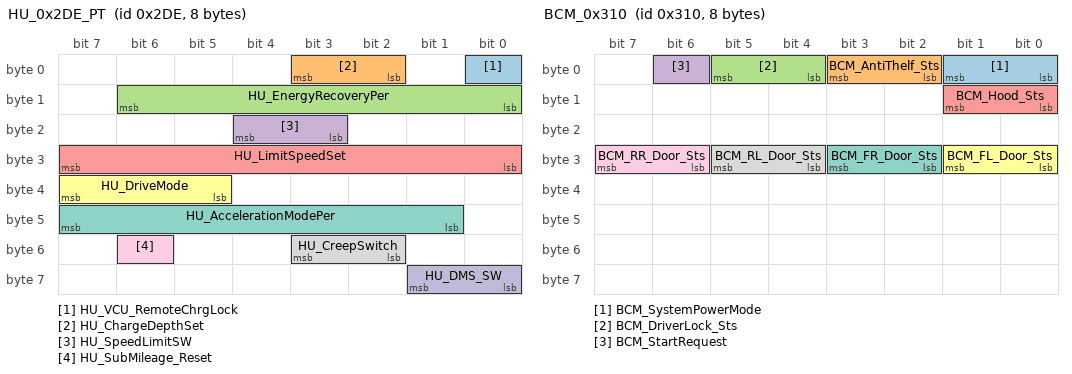
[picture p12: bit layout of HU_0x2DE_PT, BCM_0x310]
BO_ 734 HU_0x2DE_PT: 8 GW
 SG_ HU_VCU_RemoteChrgLock : 0|1@0+ (1,0) [0|1] "" VCU
 SG_ HU_ChargeDepthSet : 3|2@0+ (1,0) [0|3] "" VCU
 SG_ HU_EnergyRecoveryPer : 14|7@0+ (1,0) [0|100] "" VCU
 SG_ HU_SpeedLimitSW : 20|2@0+ (1,0) [0|3] "" VCU
 SG_ HU_LimitSpeedSet : 31|8@0+ (1,0) [0|200] "" VCU
 SG_ HU_DriveMode : 39|3@0+ (1,0) [0|7] "" VCU
 SG_ HU_AccelerationModePer : 47|7@0+ (1,0) [0|100] "" VCU
 SG_ HU_CreepSwitch : 51|2@0+ (1,0) [0|3] "" VCU
 SG_ HU_SubMileage_Reset : 54|1@0+ (1,0) [0|1] "" VCU
 SG_ HU_DMS_SW : 57|2@0+ (1,0) [0|3] "" VCU

BO_ 774 BMS_0x306: 8 BMS
 SG_ BMS_RemainChargingTime : 7|10@0+ (1,0) [0|1000] "min" GW
 SG_ BMS_Charing_Time : 13|10@0+ (1,0) [0|1000] "min" GW
 SG_ BMS_Charging_Ah : 16|9@0+ (0.5,0) [0|250] "Ah" GW
 SG_ BMS_TotalCharging_Ah : 35|20@0+ (1,0) [0|500000] "Ah" GW
 SG_ BMS_Charging_Energy : 63|8@0+ (0.5,0) [0|125] "kwh" GW

BO_ 784 BCM_0x310: 8 GW
 SG_ BCM_SystemPowerMode : 1|2@0+ (1,0) [0|3] "" MCU,DCDC,BMS,VCU
 SG_ BCM_AntiThelf_Sts : 3|2@0+ (1,0) [0|3] "" VCU
 SG_ BCM_DriverLock_Sts : 5|2@0+ (1,0) [0|3] "" OBC,VCU
 SG_ BCM_StartRequest : 6|1@0+ (1,0) [0|1] "" VCU
 SG_ BCM_Hood_Sts : 9|2@0+ (1,0) [0|3] "" VCU
 SG_ BCM_FL_Door_Sts : 25|2@0+ (1,0) [0|3] "" VCU
 SG_ BCM_FR_Door_Sts : 27|2@0+ (1,0) [0|3] "" VCU
 SG_ BCM_RL_Door_Sts : 29|2@0+ (1,0) [0|3] "" VCU
 SG_ BCM_RR_Door_Sts : 31|2@0+ (1,0) [0|3] "" VCU

BO_ 804 MCU_0x324: 8 MCU
 SG_ MCU_FailCode1 : 7|16@0+ (1,0) [0|65535] "" GW
 SG_ MCU_FailCode2 : 23|16@0+ (1,0) [0|65535] "" GW
 SG_ MCU_FailCode3 : 39|16@0+ (1,0) [0|65535] "" GW
 SG_ MCU_FailCode4 : 55|16@0+ (1,0) [0|65535] "" GW

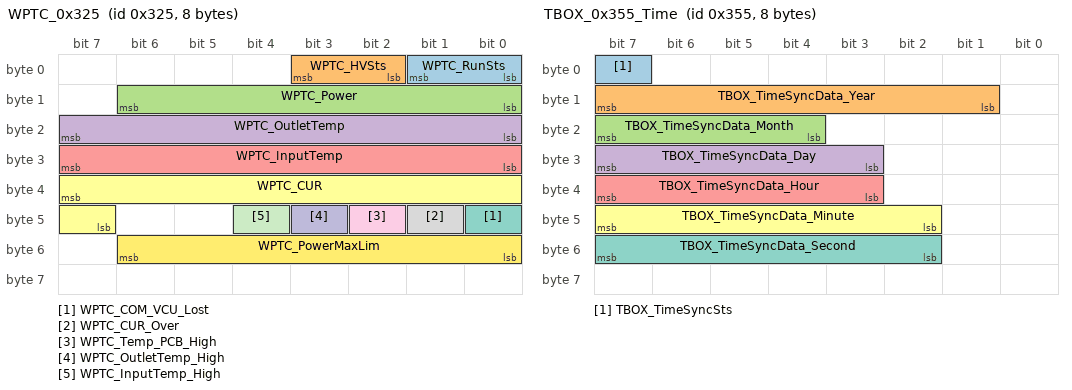
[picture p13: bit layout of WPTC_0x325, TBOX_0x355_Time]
BO_ 805 WPTC_0x325: 8 WPTC
 SG_ WPTC_RunSts : 1|2@0+ (1,0) [0|3] "" BMS,VCU,GW
 SG_ WPTC_HVSts : 3|2@0+ (1,0) [0|3] "" GW
 SG_ WPTC_Power : 14|7@0+ (0.1,0) [0|12.7] "KW" BMS,VCU,GW
 SG_ WPTC_OutletTemp : 23|8@0+ (1,-40) [-40|215] "℃" GW
 SG_ WPTC_InputTemp : 31|8@0+ (1,-40) [-40|215] "℃" GW
 SG_ WPTC_CUR : 39|9@0+ (0.1,0) [0|40] "" GW
 SG_ WPTC_COM_VCU_Lost : 40|1@0+ (1,0) [0|1] "" GW
 SG_ WPTC_CUR_Over : 41|1@0+ (1,0) [0|1] "" GW
 SG_ WPTC_Temp_PCB_High : 42|1@0+ (1,0) [0|1] "" GW
 SG_ WPTC_OutletTemp_High : 43|1@0+ (1,0) [0|1] "" GW
 SG_ WPTC_InputTemp_High : 44|1@0+ (1,0) [0|1] "" GW
 SG_ WPTC_PowerMaxLim : 54|7@0+ (0.1,0) [0|12.7] "KW" VCU,GW

BO_ 853 TBOX_0x355_Time: 8 GW
 SG_ TBOX_TimeSyncSts : 7|1@0+ (1,0) [0|1] "" MCU,BMS,VCU
 SG_ TBOX_TimeSyncData_Year : 15|7@0+ (1,2000) [2000|2099] "" MCU,BMS,VCU
 SG_ TBOX_TimeSyncData_Month : 23|4@0+ (1,0) [1|12] "" MCU,BMS,VCU
 SG_ TBOX_TimeSyncData_Day : 31|5@0+ (1,0) [1|31] "" MCU,BMS,VCU
 SG_ TBOX_TimeSyncData_Hour : 39|5@0+ (1,0) [0|23] "" MCU,BMS,VCU
 SG_ TBOX_TimeSyncData_Minute : 47|6@0+ (1,0) [0|59] "" MCU,BMS,VCU
 SG_ TBOX_TimeSyncData_Second : 55|6@0+ (1,0) [0|59] "" MCU,BMS,VCU

BO_ 905 DCDC_0x389: 8 DCDC
 SG_ Checksum_0x389 : 7|8@0+ (1,0) [0|255] "" GW
 SG_ DCDC_DeratingSts : 12|1@0+ (1,0) [0|1] "" GW
 SG_ DCDC_rUtilRateDFM : 24|9@0+ (0.25,0) [0|127.75] "%" GW
 SG_ DCDC_TempAct : 47|8@0+ (1,-40) [-40|215] "°C" VCU,GW
 SG_ Counter_0x389 : 59|4@0+ (1,0) [0|15] "" GW

BO_ 928 ICM_0x3A0: 8 GW
 SG_ ICM_ODOTotal : 7|24@0+ (1,0) [0|999999] "KM" MCU,VCU
 SG_ ICM_DisPlayVehicleSpeed : 27|12@0+ (0.05625,0) [0|230.28749] "kph" Vector__XXX
 SG_ ICM_Error_Sts : 51|2@0+ (1,0) [0|3] "" MCU
 SG_ ICM_SubMileage_Reset : 59|1@0+ (1,0) [0|1] "" VCU

BO_ 1027 VCU_NM_0x403: 8 VCU
 SG_ VCU_NM_DA : 7|8@0+ (1,0) [0|255] "" GW
 SG_ VCU_NM_ALIVE : 8|1@0+ (1,0) [0|1] "" GW
 SG_ VCU_NM_RING : 9|1@0+ (1,0) [0|1] "" GW
 SG_ VCU_NM_LIMPHOME : 10|1@0+ (1,0) [0|1] "" GW
 SG_ VCU_NM_SLEEP_Ind : 12|1@0+ (1,0) [0|1] "" GW
 SG_ VCU_NM_SLEEP_ACK : 13|1@0+ (1,0) [0|1] "" GW

BO_ 1032 GW_PT_NM_0x408: 8 GW
 SG_ GW_PT_NM_DA : 7|8@0+ (1,0) [0|255] "" VCU
 SG_ GW_PT_NM_ALIVE : 8|1@0+ (1,0) [0|1] "" VCU
 SG_ GW_PT_NM_RING : 9|1@0+ (1,0) [0|1] "" VCU
 SG_ GW_PT_NM_LIMPHOME : 10|1@0+ (1,0) [0|1] "" VCU
 SG_ GW_PT_NM_SLEEP_Ind : 12|1@0+ (1,0) [0|1] "" VCU
 SG_ GW_PT_NM_SLEEP_ACK : 13|1@0+ (1,0) [0|1] "" VCU

BO_ 1299 BMS_0x513: 8 BMS
 SG_ BMS_MaxTempNo : 7|8@0+ (1,0) [0|255] "" GW
 SG_ BMS_MaxTemp : 15|8@0+ (0.5,-40) [-40|85] "℃" VCU,GW
 SG_ BMS_MinTempNo : 23|8@0+ (1,0) [0|255] "" GW
 SG_ BMS_MinTemp : 31|8@0+ (0.5,-40) [-40|85] "℃" VCU,GW
 SG_ BMS_BattTempDev : 39|8@0+ (0.5,-40) [-40|85] "℃" GW
 SG_ BMS_CCTemp1 : 47|8@0+ (1,-40) [-40|120] "℃" GW
 SG_ BMS_CCTemp2 : 55|8@0+ (1,-40) [-40|120] "℃" GW
 SG_ BMS_0x513_RollingCounter : 59|4@0+ (1,0) [0|15] "" GW

BO_ 1300 BMS_0x514: 8 BMS
 SG_ BMS_ModuleBusbarMaxTempNo : 15|8@0+ (1,0) [0|255] "" GW
 SG_ BMS_ModuleBusbarMaxTemp : 23|8@0+ (0.5,-40) [-40|85] "℃" GW
 SG_ BMS_ModuleBusbarMinTempNo : 31|8@0+ (1,0) [0|255] "" GW
 SG_ BMS_ModuleBusbarMinTemp : 39|8@0+ (0.5,-40) [-40|85] "℃" GW
 SG_ BMS_0x514_RollingCounter : 59|4@0+ (1,0) [0|15] "" GW

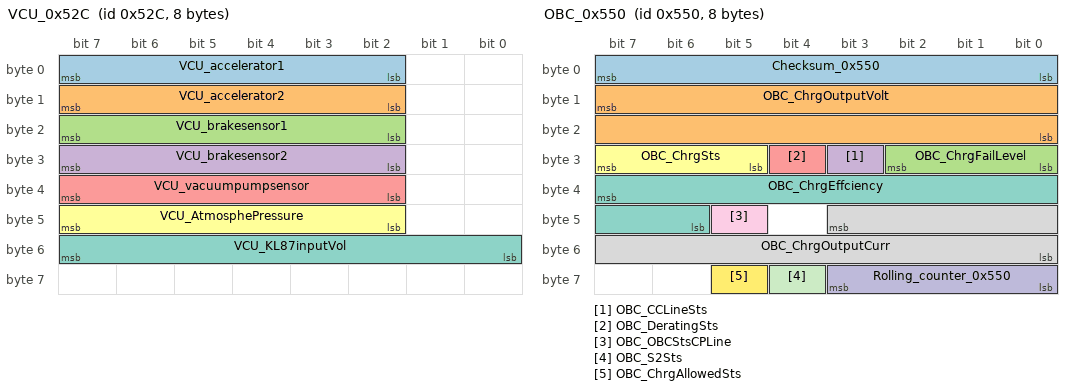
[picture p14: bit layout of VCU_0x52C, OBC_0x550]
BO_ 1324 VCU_0x52C: 8 VCU
 SG_ VCU_accelerator1 : 7|6@0+ (0.1,0) [0|6.3] "V" Vector__XXX
 SG_ VCU_accelerator2 : 15|6@0+ (0.1,0) [0|6.3] "V" Vector__XXX
 SG_ VCU_brakesensor1 : 23|6@0+ (0.1,0) [0|6.3] "V" Vector__XXX
 SG_ VCU_brakesensor2 : 31|6@0+ (0.1,0) [0|6.3] "V" Vector__XXX
 SG_ VCU_vacuumpumpsensor : 39|6@0+ (0.1,0) [0|6.3] "V" Vector__XXX
 SG_ VCU_AtmosphePressure : 47|6@0+ (0.1,0) [0|6.3] "V" Vector__XXX
 SG_ VCU_KL87inputVol : 55|8@0+ (0.1,0) [0|25.4] "V" Vector__XXX

BO_ 1328 BMS_0x530: 8 BMS
 SG_ BMS_BattCellNum1Vol : 7|16@0+ (1,0) [0|5000] "mV" GW
 SG_ BMS_BattCellNum2Vol : 23|16@0+ (1,0) [0|5000] "mV" GW
 SG_ BMS_BattCellNum3Vol : 39|16@0+ (1,0) [0|5000] "mV" GW
 SG_ BMS_BattCellNum4Vol : 55|16@0+ (1,0) [0|5000] "mV" GW

BO_ 1329 BMS_0x531: 8 BMS
 SG_ BMS_BattCellNum5Vol : 7|16@0+ (1,0) [0|5000] "mV" GW
 SG_ BMS_BattCellNum6Vol : 23|16@0+ (1,0) [0|5000] "mV" GW
 SG_ BMS_BattCellNum7Vol : 39|16@0+ (1,0) [0|5000] "mV" GW
 SG_ BMS_BattCellNum8Vol : 55|16@0+ (1,0) [0|5000] "mV" GW

BO_ 1330 BMS_0x532: 8 BMS
 SG_ BMS_BattCellNum9Vol : 7|16@0+ (1,0) [0|5000] "mV" GW
 SG_ BMS_BattCellNum10Vol : 23|16@0+ (1,0) [0|5000] "mV" GW
 SG_ BMS_BattCellNum11Vol : 39|16@0+ (1,0) [0|5000] "mV" GW
 SG_ BMS_BattCellNum12Vol : 55|16@0+ (1,0) [0|5000] "mV" GW

BO_ 1331 BMS_0x533: 8 BMS
 SG_ BMS_BattCellNum13Vol : 7|16@0+ (1,0) [0|5000] "mV" GW
 SG_ BMS_BattCellNum14Vol : 23|16@0+ (1,0) [0|5000] "mV" GW
 SG_ BMS_BattCellNum15Vol : 39|16@0+ (1,0) [0|5000] "mV" GW
 SG_ BMS_BattCellNum16Vol : 55|16@0+ (1,0) [0|5000] "mV" GW

BO_ 1332 BMS_0x534: 8 BMS
 SG_ BMS_BattCellNum17Vol : 7|16@0+ (1,0) [0|5000] "mV" GW
 SG_ BMS_BattCellNum18Vol : 23|16@0+ (1,0) [0|5000] "mV" GW
 SG_ BMS_BattCellNum19Vol : 39|16@0+ (1,0) [0|5000] "mV" GW
 SG_ BMS_BattCellNum20Vol : 55|16@0+ (1,0) [0|5000] "mV" GW

BO_ 1333 BMS_0x535: 8 BMS
 SG_ BMS_BattCellNum21Vol : 7|16@0+ (1,0) [0|5000] "mV" GW
 SG_ BMS_BattCellNum22Vol : 23|16@0+ (1,0) [0|5000] "mV" GW
 SG_ BMS_BattCellNum23Vol : 39|16@0+ (1,0) [0|5000] "mV" GW
 SG_ BMS_BattCellNum24Vol : 55|16@0+ (1,0) [0|5000] "mV" GW

BO_ 1334 BMS_0x536: 8 BMS
 SG_ BMS_BattCellNum25Vol : 7|16@0+ (1,0) [0|5000] "mV" GW
 SG_ BMS_BattCellNum26Vol : 23|16@0+ (1,0) [0|5000] "mV" GW
 SG_ BMS_BattCellNum27Vol : 39|16@0+ (1,0) [0|5000] "mV" GW
 SG_ BMS_BattCellNum28Vol : 55|16@0+ (1,0) [0|5000] "mV" GW

BO_ 1335 BMS_0x537: 8 BMS
 SG_ BMS_BattCellNum29Vol : 7|16@0+ (1,0) [0|5000] "mV" GW
 SG_ BMS_BattCellNum30Vol : 23|16@0+ (1,0) [0|5000] "mV" GW
 SG_ BMS_BattCellNum31Vol : 39|16@0+ (1,0) [0|5000] "mV" GW
 SG_ BMS_BattCellNum32Vol : 55|16@0+ (1,0) [0|5000] "mV" GW

BO_ 1336 BMS_0x538: 8 BMS
 SG_ BMS_BattCellNum33Vol : 7|16@0+ (1,0) [0|5000] "mV" GW
 SG_ BMS_BattCellNum34Vol : 23|16@0+ (1,0) [0|5000] "mV" GW
 SG_ BMS_BattCellNum35Vol : 39|16@0+ (1,0) [0|5000] "mV" GW
 SG_ BMS_BattCellNum36Vol : 55|16@0+ (1,0) [0|5000] "mV" GW

BO_ 1337 BMS_0x539: 8 BMS
 SG_ BMS_BattCellNum37Vol : 7|16@0+ (1,0) [0|5000] "mV" GW
 SG_ BMS_BattCellNum38Vol : 23|16@0+ (1,0) [0|5000] "mV" GW
 SG_ BMS_BattCellNum39Vol : 39|16@0+ (1,0) [0|5000] "mV" GW
 SG_ BMS_BattCellNum40Vol : 55|16@0+ (1,0) [0|5000] "mV" GW

BO_ 1338 BMS_0x53A: 8 BMS
 SG_ BMS_BattCellNum41Vol : 7|16@0+ (1,0) [0|5000] "mV" GW
 SG_ BMS_BattCellNum42Vol : 23|16@0+ (1,0) [0|5000] "mV" GW
 SG_ BMS_BattCellNum43Vol : 39|16@0+ (1,0) [0|5000] "mV" GW
 SG_ BMS_BattCellNum44Vol : 55|16@0+ (1,0) [0|5000] "mV" GW

BO_ 1339 BMS_0x53B: 8 BMS
 SG_ BMS_BattCellNum45Vol : 7|16@0+ (1,0) [0|5000] "mV" GW
 SG_ BMS_BattCellNum46Vol : 23|16@0+ (1,0) [0|5000] "mV" GW
 SG_ BMS_BattCellNum47Vol : 39|16@0+ (1,0) [0|5000] "mV" GW
 SG_ BMS_BattCellNum48Vol : 55|16@0+ (1,0) [0|5000] "mV" GW

BO_ 1340 BMS_0x53C: 8 BMS
 SG_ BMS_BattCellNum49Vol : 7|16@0+ (1,0) [0|5000] "mV" GW
 SG_ BMS_BattCellNum50Vol : 23|16@0+ (1,0) [0|5000] "mV" GW
 SG_ BMS_BattCellNum51Vol : 39|16@0+ (1,0) [0|5000] "mV" GW
 SG_ BMS_BattCellNum52Vol : 55|16@0+ (1,0) [0|5000] "mV" GW

BO_ 1341 BMS_0x53D: 8 BMS
 SG_ BMS_BattCellNum53Vol : 7|16@0+ (1,0) [0|5000] "mV" GW
 SG_ BMS_BattCellNum54Vol : 23|16@0+ (1,0) [0|5000] "mV" GW
 SG_ BMS_BattCellNum55Vol : 39|16@0+ (1,0) [0|5000] "mV" GW
 SG_ BMS_BattCellNum56Vol : 55|16@0+ (1,0) [0|5000] "mV" GW

BO_ 1342 BMS_0x53E: 8 BMS
 SG_ BMS_BattCellNum57Vol : 7|16@0+ (1,0) [0|5000] "mV" GW
 SG_ BMS_BattCellNum58Vol : 23|16@0+ (1,0) [0|5000] "mV" GW
 SG_ BMS_BattCellNum59Vol : 39|16@0+ (1,0) [0|5000] "mV" GW
 SG_ BMS_BattCellNum60Vol : 55|16@0+ (1,0) [0|5000] "mV" GW

BO_ 1343 BMS_0x53F: 8 BMS
 SG_ BMS_BattCellNum61Vol : 7|16@0+ (1,0) [0|5000] "mV" GW
 SG_ BMS_BattCellNum62Vol : 23|16@0+ (1,0) [0|5000] "mV" GW
 SG_ BMS_BattCellNum63Vol : 39|16@0+ (1,0) [0|5000] "mV" GW
 SG_ BMS_BattCellNum64Vol : 55|16@0+ (1,0) [0|5000] "mV" GW

BO_ 1344 BMS_0x540: 8 BMS
 SG_ BMS_BattCellNum65Vol : 7|16@0+ (1,0) [0|5000] "mV" GW
 SG_ BMS_BattCellNum66Vol : 23|16@0+ (1,0) [0|5000] "mV" GW
 SG_ BMS_BattCellNum67Vol : 39|16@0+ (1,0) [0|5000] "mV" GW
 SG_ BMS_BattCellNum68Vol : 55|16@0+ (1,0) [0|5000] "mV" GW

BO_ 1345 BMS_0x541: 8 BMS
 SG_ BMS_BattCellNum69Vol : 7|16@0+ (1,0) [0|5000] "mV" GW
 SG_ BMS_BattCellNum70Vol : 23|16@0+ (1,0) [0|5000] "mV" GW
 SG_ BMS_BattCellNum71Vol : 39|16@0+ (1,0) [0|5000] "mV" GW
 SG_ BMS_BattCellNum72Vol : 55|16@0+ (1,0) [0|5000] "mV" GW

BO_ 1346 BMS_0x542: 8 BMS
 SG_ BMS_BattCellNum73Vol : 7|16@0+ (1,0) [0|5000] "mV" GW
 SG_ BMS_BattCellNum74Vol : 23|16@0+ (1,0) [0|5000] "mV" GW
 SG_ BMS_BattCellNum75Vol : 39|16@0+ (1,0) [0|5000] "mV" GW
 SG_ BMS_BattCellNum76Vol : 55|16@0+ (1,0) [0|5000] "mV" GW

BO_ 1347 BMS_0x543: 8 BMS
 SG_ BMS_BattCellNum77Vol : 7|16@0+ (1,0) [0|5000] "mV" GW
 SG_ BMS_BattCellNum78Vol : 23|16@0+ (1,0) [0|5000] "mV" GW
 SG_ BMS_BattCellNum79Vol : 39|16@0+ (1,0) [0|5000] "mV" GW
 SG_ BMS_BattCellNum80Vol : 55|16@0+ (1,0) [0|5000] "mV" GW

BO_ 1348 BMS_0x544: 8 BMS
 SG_ BMS_BattCellNum81Vol : 7|16@0+ (1,0) [0|5000] "mV" GW
 SG_ BMS_BattCellNum82Vol : 23|16@0+ (1,0) [0|5000] "mV" GW
 SG_ BMS_BattCellNum83Vol : 39|16@0+ (1,0) [0|5000] "mV" GW
 SG_ BMS_BattCellNum84Vol : 55|16@0+ (1,0) [0|5000] "mV" GW

BO_ 1349 BMS_0x545: 8 BMS
 SG_ BMS_BattCellNum85Vol : 7|16@0+ (1,0) [0|5000] "mV" GW
 SG_ BMS_BattCellNum86Vol : 23|16@0+ (1,0) [0|5000] "mV" GW
 SG_ BMS_BattCellNum87Vol : 39|16@0+ (1,0) [0|5000] "mV" GW
 SG_ BMS_BattCellNum88Vol : 55|16@0+ (1,0) [0|5000] "mV" GW

BO_ 1350 BMS_0x546: 8 BMS
 SG_ BMS_BattCellNum89Vol : 7|16@0+ (1,0) [0|5000] "mV" GW
 SG_ BMS_BattCellNum90Vol : 23|16@0+ (1,0) [0|5000] "mV" GW
 SG_ BMS_BattCellNum91Vol : 39|16@0+ (1,0) [0|5000] "mV" GW
 SG_ BMS_BattCellNum92Vol : 55|16@0+ (1,0) [0|5000] "mV" GW

BO_ 1351 BMS_0x547: 8 BMS
 SG_ BMS_BattCellNum93Vol : 7|16@0+ (1,0) [0|5000] "mV" GW
 SG_ BMS_BattCellNum94Vol : 23|16@0+ (1,0) [0|5000] "mV" GW
 SG_ BMS_BattCellNum95Vol : 39|16@0+ (1,0) [0|5000] "mV" GW
 SG_ BMS_BattCellNum96Vol : 55|16@0+ (1,0) [0|5000] "mV" GW

BO_ 1352 BMS_0x548: 8 BMS
 SG_ BMS_BattCellNum97Vol : 7|16@0+ (1,0) [0|5000] "mV" GW
 SG_ BMS_BattCellNum98Vol : 23|16@0+ (1,0) [0|5000] "mV" GW
 SG_ BMS_BattCellNum99Vol : 39|16@0+ (1,0) [0|5000] "mV" GW
 SG_ BMS_BattCellNum100Vol : 55|16@0+ (1,0) [0|5000] "mV" GW

BO_ 1353 BMS_0x549: 8 BMS
 SG_ BMS_BattCellNum101Vol : 7|16@0+ (1,0) [0|5000] "mV" GW
 SG_ BMS_BattCellNum102Vol : 23|16@0+ (1,0) [0|5000] "mV" GW
 SG_ BMS_BattCellNum103Vol : 39|16@0+ (1,0) [0|5000] "mV" GW
 SG_ BMS_BattCellNum104Vol : 55|16@0+ (1,0) [0|5000] "mV" GW

BO_ 1354 BMS_0x54A: 8 BMS
 SG_ BMS_BattCellNum105Vol : 7|16@0+ (1,0) [0|5000] "mV" GW
 SG_ BMS_BattCellNum106Vol : 23|16@0+ (1,0) [0|5000] "mV" GW
 SG_ BMS_BattCellNum107Vol : 39|16@0+ (1,0) [0|5000] "mV" GW
 SG_ BMS_BattCellNum108Vol : 55|16@0+ (1,0) [0|5000] "mV" GW

BO_ 1360 OBC_0x550: 8 OBC
 SG_ Checksum_0x550 : 7|8@0+ (1,0) [0|255] "" VCU,GW
 SG_ OBC_ChrgOutputVolt : 15|16@0+ (0.1,0) [0|600] "V" BMS,GW
 SG_ OBC_ChrgFailLevel : 26|3@0+ (1,0) [0|7] "" VCU,GW
 SG_ OBC_CCLineSts : 27|1@0+ (1,0) [0|1] "" BMS,VCU,GW
 SG_ OBC_DeratingSts : 28|1@0+ (1,0) [0|1] "" GW
 SG_ OBC_ChrgSts : 31|3@0+ (1,0) [0|7] "" BMS,VCU,GW
 SG_ OBC_ChrgEffciency : 39|10@0+ (0.001,0) [0|1] "" GW
 SG_ OBC_ChrgOutputCurr : 43|12@0+ (0.1,0) [0|40] "" BMS,GW
 SG_ OBC_OBCStsCPLine : 45|1@0+ (1,0) [0|1] "" GW
 SG_ Rolling_counter_0x550 : 59|4@0+ (1,0) [0|15] "" GW
 SG_ OBC_S2Sts : 60|1@0+ (1,0) [0|1] "" BMS,GW
 SG_ OBC_ChrgAllowedSts : 61|1@0+ (1,0) [0|1] "" VCU,GW

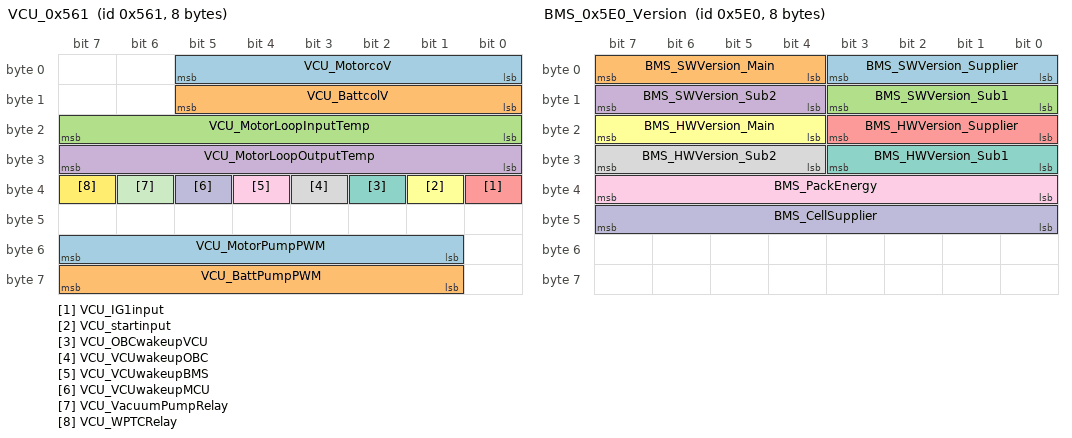
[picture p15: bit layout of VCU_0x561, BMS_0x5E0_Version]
BO_ 1377 VCU_0x561: 8 VCU
 SG_ VCU_MotorcoV : 5|6@0+ (0.1,0) [0|6.3] "V" GW
 SG_ VCU_BattcolV : 13|6@0+ (0.1,0) [0|6.3] "V" GW
 SG_ VCU_MotorLoopInputTemp : 23|8@0+ (1,-40) [-40|215] "℃" GW
 SG_ VCU_MotorLoopOutputTemp : 31|8@0+ (1,-40) [-40|215] "℃" GW
 SG_ VCU_IG1input : 32|1@0+ (1,0) [0|1] "" GW
 SG_ VCU_startinput : 33|1@0+ (1,0) [0|1] "" GW
 SG_ VCU_OBCwakeupVCU : 34|1@0+ (1,0) [0|1] "" GW
 SG_ VCU_VCUwakeupOBC : 35|1@0+ (1,0) [0|1] "" GW
 SG_ VCU_VCUwakeupBMS : 36|1@0+ (1,0) [0|1] "" GW
 SG_ VCU_VCUwakeupMCU : 37|1@0+ (1,0) [0|1] "" GW
 SG_ VCU_VacuumPumpRelay : 38|1@0+ (1,0) [0|1] "" GW
 SG_ VCU_WPTCRelay : 39|1@0+ (1,0) [0|1] "" GW
 SG_ VCU_MotorPumpPWM : 55|7@0+ (1,0) [0|100] "%" GW
 SG_ VCU_BattPumpPWM : 63|7@0+ (1,0) [0|100] "%" GW

BO_ 1378 MCU_0x562: 8 MCU
 SG_ MCU_MotorSts_GBT : 7|8@0+ (1,0) [0|255] "" GW
 SG_ MCU_MotoroffsetCalReq : 34|1@0+ (1,0) [0|1] "" VCU

BO_ 1424 BMS_0x590: 8 BMS
 SG_ BMS_BattSerialNumber : 7|16@0+ (1,0) [0|9999] "" GW
 SG_ BMS_BattManuYear : 23|8@0+ (1,0) [0|255] "" GW
 SG_ BMS_BattManuMonth : 31|8@0+ (1,0) [0|255] "" GW
 SG_ BMS_BattManuDay : 39|8@0+ (1,0) [0|255] "" GW

BO_ 1425 BMS_0x591: 8 BMS
 SG_ BMS_BattSupplierCode : 15|24@0+ (1,0) [0|16777215] "" GW
 SG_ BMS_ProductTypeCode : 39|8@0+ (1,0) [0|255] "" GW
 SG_ BMS_BattTypeCode : 47|8@0+ (1,0) [0|255] "" GW
 SG_ BMS_BattSpecCode : 55|16@0+ (1,0) [0|65535] "" GW

BO_ 1426 BMS_0x592: 8 BMS
 SG_ BMS_BattRetrospectCode : 7|56@0+ (1,0) [1|72057594037927900] "" GW

BO_ 1427 BMS_0x593: 8 BMS
 SG_ BMS_BattProductionDate : 7|24@0+ (1,0) [1|16777215] "" GW
 SG_ BMS_BattS_Num : 31|24@0+ (1,0) [0|16777215] "" GW
 SG_ BMS_BattRecycleCode : 55|16@0+ (1,0) [0|65535] "" GW

BO_ 1428 BMS_0x594: 8 BMS
 SG_ BMS_BattCodeLenth : 7|8@0+ (1,0) [1|26] "" GW
 SG_ BMS_Temp_ProbeNum : 45|6@0+ (1,0) [0|63] "" GW
 SG_ BMS_PackageTotalNum : 47|2@0+ (1,0) [0|3] "" GW
 SG_ BMS_CellTotalNum : 55|8@0+ (1,0) [0|255] "" GW

BO_ 1504 BMS_0x5E0_Version: 8 BMS
 SG_ BMS_SWVersion_Supplier : 3|4@0+ (1,0) [0|15] "" GW
 SG_ BMS_SWVersion_Main : 7|4@0+ (1,0) [0|15] "" GW
 SG_ BMS_SWVersion_Sub1 : 11|4@0+ (1,0) [0|15] "" GW
 SG_ BMS_SWVersion_Sub2 : 15|4@0+ (1,0) [0|15] "" GW
 SG_ BMS_HWVersion_Supplier : 19|4@0+ (1,0) [0|15] "" GW
 SG_ BMS_HWVersion_Main : 23|4@0+ (1,0) [0|15] "" GW
 SG_ BMS_HWVersion_Sub1 : 27|4@0+ (1,0) [0|15] "" GW
 SG_ BMS_HWVersion_Sub2 : 31|4@0+ (1,0) [0|15] "" GW
 SG_ BMS_PackEnergy : 39|8@0+ (1,0) [0|255] "kWh" GW
 SG_ BMS_CellSupplier : 47|8@0+ (1,0) [0|255] "" GW

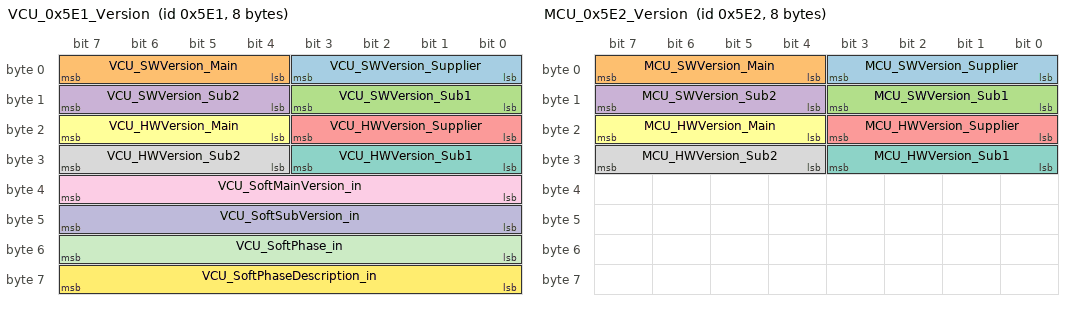
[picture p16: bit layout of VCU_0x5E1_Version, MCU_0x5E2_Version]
BO_ 1505 VCU_0x5E1_Version: 8 VCU
 SG_ VCU_SWVersion_Supplier : 3|4@0+ (1,0) [0|15] "" GW
 SG_ VCU_SWVersion_Main : 7|4@0+ (1,0) [0|15] "" GW
 SG_ VCU_SWVersion_Sub1 : 11|4@0+ (1,0) [0|15] "" GW
 SG_ VCU_SWVersion_Sub2 : 15|4@0+ (1,0) [0|15] "" GW
 SG_ VCU_HWVersion_Supplier : 19|4@0+ (1,0) [0|15] "" GW
 SG_ VCU_HWVersion_Main : 23|4@0+ (1,0) [0|15] "" GW
 SG_ VCU_HWVersion_Sub1 : 27|4@0+ (1,0) [0|15] "" GW
 SG_ VCU_HWVersion_Sub2 : 31|4@0+ (1,0) [0|15] "" GW
 SG_ VCU_SoftMainVersion_in : 39|8@0+ (1,0) [0|255] "" GW
 SG_ VCU_SoftSubVersion_in : 47|8@0+ (1,0) [0|255] "" GW
 SG_ VCU_SoftPhase_in : 55|8@0+ (1,0) [0|255] "" GW
 SG_ VCU_SoftPhaseDescription_in : 63|8@0+ (1,0) [0|255] "" GW

BO_ 1506 MCU_0x5E2_Version: 8 MCU
 SG_ MCU_SWVersion_Supplier : 3|4@0+ (1,0) [0|15] "" GW
 SG_ MCU_SWVersion_Main : 7|4@0+ (1,0) [0|15] "" GW
 SG_ MCU_SWVersion_Sub1 : 11|4@0+ (1,0) [0|15] "" GW
 SG_ MCU_SWVersion_Sub2 : 15|4@0+ (1,0) [0|15] "" GW
 SG_ MCU_HWVersion_Supplier : 19|4@0+ (1,0) [0|15] "" GW
 SG_ MCU_HWVersion_Main : 23|4@0+ (1,0) [0|15] "" GW
 SG_ MCU_HWVersion_Sub1 : 27|4@0+ (1,0) [0|15] "" GW
 SG_ MCU_HWVersion_Sub2 : 31|4@0+ (1,0) [0|15] "" GW

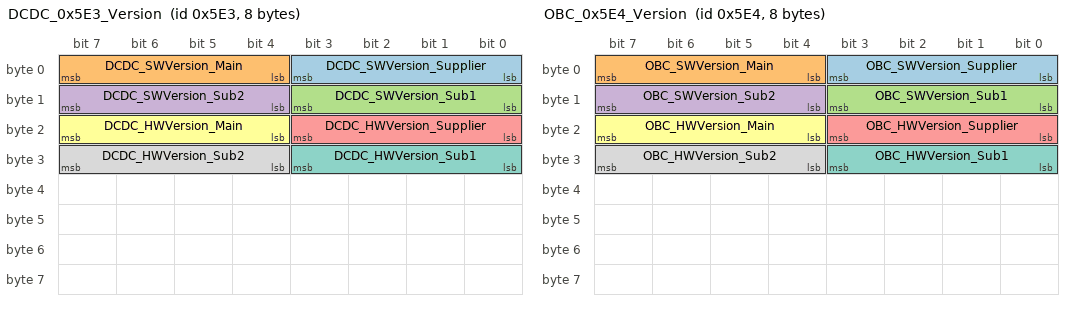
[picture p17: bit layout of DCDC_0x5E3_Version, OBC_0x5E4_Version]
BO_ 1507 DCDC_0x5E3_Version: 8 DCDC
 SG_ DCDC_SWVersion_Supplier : 3|4@0+ (1,0) [0|15] "" GW
 SG_ DCDC_SWVersion_Main : 7|4@0+ (1,0) [0|15] "" GW
 SG_ DCDC_SWVersion_Sub1 : 11|4@0+ (1,0) [0|15] "" GW
 SG_ DCDC_SWVersion_Sub2 : 15|4@0+ (1,0) [0|15] "" GW
 SG_ DCDC_HWVersion_Supplier : 19|4@0+ (1,0) [0|15] "" GW
 SG_ DCDC_HWVersion_Main : 23|4@0+ (1,0) [0|15] "" GW
 SG_ DCDC_HWVersion_Sub1 : 27|4@0+ (1,0) [0|15] "" GW
 SG_ DCDC_HWVersion_Sub2 : 31|4@0+ (1,0) [0|15] "" GW

BO_ 1508 OBC_0x5E4_Version: 8 OBC
 SG_ OBC_SWVersion_Supplier : 3|4@0+ (1,0) [0|15] "" GW
 SG_ OBC_SWVersion_Main : 7|4@0+ (1,0) [0|15] "" GW
 SG_ OBC_SWVersion_Sub1 : 11|4@0+ (1,0) [0|15] "" GW
 SG_ OBC_SWVersion_Sub2 : 15|4@0+ (1,0) [0|15] "" GW
 SG_ OBC_HWVersion_Supplier : 19|4@0+ (1,0) [0|15] "" GW
 SG_ OBC_HWVersion_Main : 23|4@0+ (1,0) [0|15] "" GW
 SG_ OBC_HWVersion_Sub1 : 27|4@0+ (1,0) [0|15] "" GW
 SG_ OBC_HWVersion_Sub2 : 31|4@0+ (1,0) [0|15] "" GW

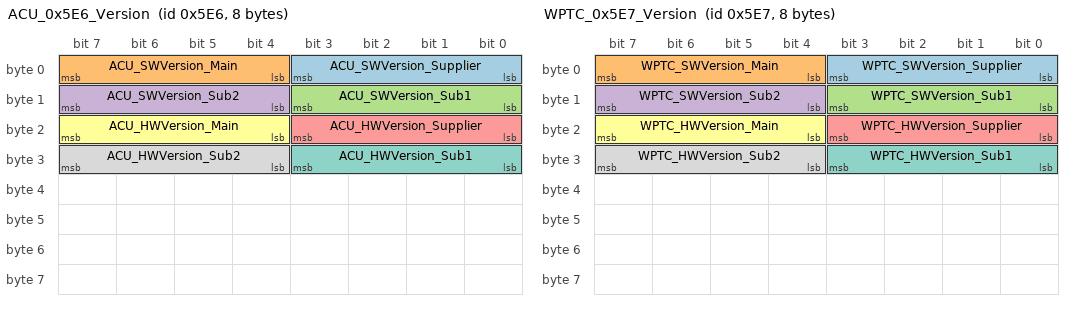
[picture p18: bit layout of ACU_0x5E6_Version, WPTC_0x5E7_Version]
BO_ 1510 ACU_0x5E6_Version: 8 ACU
 SG_ ACU_SWVersion_Supplier : 3|4@0+ (1,0) [0|15] "" GW
 SG_ ACU_SWVersion_Main : 7|4@0+ (1,0) [0|15] "" GW
 SG_ ACU_SWVersion_Sub1 : 11|4@0+ (1,0) [0|15] "" GW
 SG_ ACU_SWVersion_Sub2 : 15|4@0+ (1,0) [0|15] "" GW
 SG_ ACU_HWVersion_Supplier : 19|4@0+ (1,0) [0|15] "" GW
 SG_ ACU_HWVersion_Main : 23|4@0+ (1,0) [0|15] "" GW
 SG_ ACU_HWVersion_Sub1 : 27|4@0+ (1,0) [0|15] "" GW
 SG_ ACU_HWVersion_Sub2 : 31|4@0+ (1,0) [0|15] "" GW

BO_ 1511 WPTC_0x5E7_Version: 8 WPTC
 SG_ WPTC_SWVersion_Supplier : 3|4@0+ (1,0) [0|15] "" GW
 SG_ WPTC_SWVersion_Main : 7|4@0+ (1,0) [0|15] "" GW
 SG_ WPTC_SWVersion_Sub1 : 11|4@0+ (1,0) [0|15] "" GW
 SG_ WPTC_SWVersion_Sub2 : 15|4@0+ (1,0) [0|15] "" GW
 SG_ WPTC_HWVersion_Supplier : 19|4@0+ (1,0) [0|15] "" GW
 SG_ WPTC_HWVersion_Main : 23|4@0+ (1,0) [0|15] "" GW
 SG_ WPTC_HWVersion_Sub1 : 27|4@0+ (1,0) [0|15] "" GW
 SG_ WPTC_HWVersion_Sub2 : 31|4@0+ (1,0) [0|15] "" GW

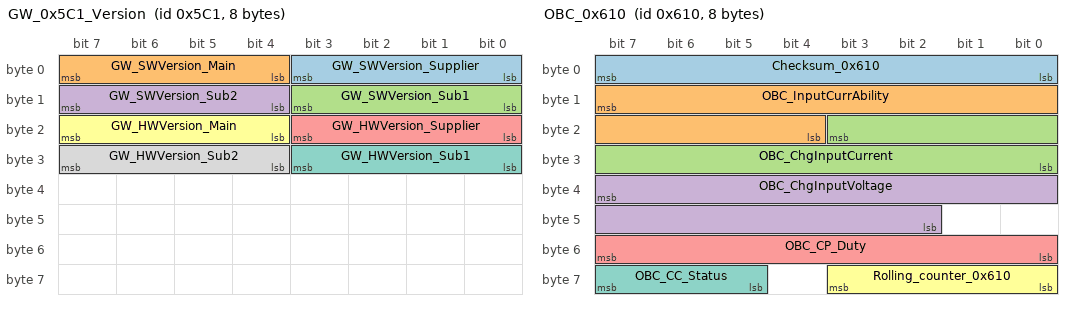
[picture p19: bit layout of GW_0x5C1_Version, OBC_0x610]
BO_ 1473 GW_0x5C1_Version: 8 GW
 SG_ GW_SWVersion_Supplier : 3|4@0+ (1,0) [0|15] "" Vector__XXX
 SG_ GW_SWVersion_Main : 7|4@0+ (1,0) [0|15] "" Vector__XXX
 SG_ GW_SWVersion_Sub1 : 11|4@0+ (1,0) [0|15] "" Vector__XXX
 SG_ GW_SWVersion_Sub2 : 15|4@0+ (1,0) [0|15] "" Vector__XXX
 SG_ GW_HWVersion_Supplier : 19|4@0+ (1,0) [0|15] "" Vector__XXX
 SG_ GW_HWVersion_Main : 23|4@0+ (1,0) [0|15] "" Vector__XXX
 SG_ GW_HWVersion_Sub1 : 27|4@0+ (1,0) [0|15] "" Vector__XXX
 SG_ GW_HWVersion_Sub2 : 31|4@0+ (1,0) [0|15] "" Vector__XXX

BO_ 1520 BMS_0x5F0: 8 BMS
 SG_ BMS_BattTempSensorNum1 : 7|8@0+ (1,-40) [-40|120] "℃" GW
 SG_ BMS_BattTempSensorNum2 : 15|8@0+ (1,-40) [-40|120] "℃" GW
 SG_ BMS_BattTempSensorNum3 : 23|8@0+ (1,-40) [-40|120] "℃" GW
 SG_ BMS_BattTempSensorNum4 : 31|8@0+ (1,-40) [-40|120] "℃" GW
 SG_ BMS_BattTempSensorNum5 : 39|8@0+ (1,-40) [-40|120] "℃" GW
 SG_ BMS_BattTempSensorNum6 : 47|8@0+ (1,-40) [-40|120] "℃" GW
 SG_ BMS_BattTempSensorNum7 : 55|8@0+ (1,-40) [-40|120] "℃" GW
 SG_ BMS_BattTempSensorNum8 : 63|8@0+ (1,-40) [-40|120] "℃" GW

BO_ 1521 BMS_0x5F1: 8 BMS
 SG_ BMS_BattTempSensorNum9 : 7|8@0+ (1,-40) [-40|120] "℃" GW
 SG_ BMS_BattTempSensorNum10 : 15|8@0+ (1,-40) [-40|120] "℃" GW
 SG_ BMS_BattTempSensorNum11 : 23|8@0+ (1,-40) [-40|120] "℃" GW
 SG_ BMS_BattTempSensorNum12 : 31|8@0+ (1,-40) [-40|120] "℃" GW
 SG_ BMS_BattTempSensorNum13 : 39|8@0+ (1,-40) [-40|120] "℃" GW
 SG_ BMS_BattTempSensorNum14 : 47|8@0+ (1,-40) [-40|120] "℃" GW
 SG_ BMS_BattTempSensorNum15 : 55|8@0+ (1,-40) [-40|120] "℃" GW
 SG_ BMS_BattTempSensorNum16 : 63|8@0+ (1,-40) [-40|120] "℃" GW

BO_ 1522 BMS_0x5F2: 8 BMS
 SG_ BMS_BattTempSensorNum17 : 7|8@0+ (1,-40) [-40|120] "℃" GW
 SG_ BMS_BattTempSensorNum18 : 15|8@0+ (1,-40) [-40|120] "℃" GW
 SG_ BMS_BattTempSensorNum19 : 23|8@0+ (1,-40) [-40|120] "℃" GW
 SG_ BMS_BattTempSensorNum20 : 31|8@0+ (1,-40) [-40|120] "℃" GW
 SG_ BMS_BattTempSensorNum21 : 39|8@0+ (1,-40) [-40|120] "℃" GW
 SG_ BMS_BattTempSensorNum22 : 47|8@0+ (1,-40) [-40|120] "℃" GW
 SG_ BMS_BattTempSensorNum23 : 55|8@0+ (1,-40) [-40|120] "℃" GW
 SG_ BMS_BattTempSensorNum24 : 63|8@0+ (1,-40) [-40|120] "℃" GW

BO_ 1523 BMS_0x5F3: 8 BMS
 SG_ BMS_BattTempSensorNum25 : 7|8@0+ (1,-40) [-40|120] "℃" GW
 SG_ BMS_BattTempSensorNum26 : 15|8@0+ (1,-40) [-40|120] "℃" GW
 SG_ BMS_BattTempSensorNum27 : 23|8@0+ (1,-40) [-40|120] "℃" GW
 SG_ BMS_BattTempSensorNum28 : 31|8@0+ (1,-40) [-40|120] "℃" GW
 SG_ BMS_BattTempSensorNum29 : 39|8@0+ (1,-40) [-40|120] "℃" GW
 SG_ BMS_BattTempSensorNum30 : 47|8@0+ (1,-40) [-40|120] "℃" GW
 SG_ BMS_BattTempSensorNum31 : 55|8@0+ (1,-40) [-40|120] "℃" GW
 SG_ BMS_BattTempSensorNum32 : 63|8@0+ (1,-40) [-40|120] "℃" GW

BO_ 1524 BMS_0x5F4: 8 BMS
 SG_ BMS_BattTempSensorNum33 : 7|8@0+ (1,-40) [-40|120] "℃" GW
 SG_ BMS_BattTempSensorNum34 : 15|8@0+ (1,-40) [-40|120] "℃" GW
 SG_ BMS_BattTempSensorNum35 : 23|8@0+ (1,-40) [-40|120] "℃" GW
 SG_ BMS_BattTempSensorNum36 : 31|8@0+ (1,-40) [-40|120] "℃" GW
 SG_ BMS_BattTempSensorNum37 : 39|8@0+ (1,-40) [-40|120] "℃" GW
 SG_ BMS_BattTempSensorNum38 : 47|8@0+ (1,-40) [-40|120] "℃" GW
 SG_ BMS_BattTempSensorNum39 : 55|8@0+ (1,-40) [-40|120] "℃" GW
 SG_ BMS_BattTempSensorNum40 : 63|8@0+ (1,-40) [-40|120] "℃" GW

BO_ 1552 OBC_0x610: 8 OBC
 SG_ Checksum_0x610 : 7|8@0+ (1,0) [0|255] "" GW
 SG_ OBC_InputCurrAbility : 15|12@0+ (0.1,0) [0|100] "A" GW
 SG_ OBC_ChgInputCurrent : 19|12@0+ (0.1,0) [0|100] "A" GW
 SG_ OBC_ChgInputVoltage : 39|14@0+ (0.1,0) [0|500] "V" GW
 SG_ OBC_CP_Duty : 55|8@0+ (0.5,0) [0|100] "%" BMS,GW
 SG_ Rolling_counter_0x610 : 59|4@0+ (1,0) [0|15] "" GW
 SG_ OBC_CC_Status : 63|3@0+ (1,0) [0|7] "" BMS,VCU,GW

BO_ 1553 OBC_0x611: 8 OBC
 SG_ OBC_SocketTempHig : 5|1@0+ (1,0) [0|1] "" GW
 SG_ OBC_InputVolLow : 6|1@0+ (1,0) [0|1] "" GW
 SG_ OBC_HardTempHig : 7|1@0+ (1,0) [0|1] "" GW
 SG_ OBC_OutputShorCir : 8|1@0+ (1,0) [0|1] "" GW
 SG_ OBC_OutputVolHig : 9|1@0+ (1,0) [0|1] "" GW
 SG_ OBC_OutputVolLow : 10|1@0+ (1,0) [0|1] "" GW
 SG_ OBC_PFCOutputVolHig : 11|1@0+ (1,0) [0|1] "" GW
 SG_ OBC_PFCOutputVolLow : 12|1@0+ (1,0) [0|1] "" GW
 SG_ OBC_CommTimeOut : 13|1@0+ (1,0) [0|1] "" GW
 SG_ OBC_InputCurHig : 14|1@0+ (1,0) [0|1] "" GW
 SG_ OBC_InputVolHig : 15|1@0+ (1,0) [0|1] "" GW
 SG_ OBC_BMSVolLow : 17|1@0+ (1,0) [0|1] "" GW
 SG_ OBC_BMSVolHig : 18|1@0+ (1,0) [0|1] "" GW
 SG_ OBC_ContraryConnect : 19|1@0+ (1,0) [0|1] "" GW
 SG_ OBC_InsideComTimeOut : 20|1@0+ (1,0) [0|1] "" GW
 SG_ OBC_ElockFail : 21|1@0+ (1,0) [0|1] "" GW
 SG_ OBC_HardFail : 22|1@0+ (1,0) [0|1] "" GW
 SG_ OBC_OutputCurHig : 23|1@0+ (1,0) [0|1] "" GW
 SG_ OBC_SoketTemp_N : 47|8@0+ (1,-40) [-40|215] "DegC" GW
 SG_ OBC_CoolantPlateTemp : 55|8@0+ (1,-55) [-55|200] "DegC" VCU,GW
 SG_ OBC_SoketTemp_L : 63|8@0+ (1,-40) [-40|215] "DegC" GW

BO_ 1555 OBC_0x613: 8 OBC
 SG_ Checksum_0x613 : 7|8@0+ (1,0) [0|1] "" Vector__XXX
 SG_ OBC_MaxChrgOutpVolt : 15|16@0+ (0.1,0) [0|600] "V" BMS
 SG_ OBC_MaxChrgOutpCur : 31|12@0+ (0.1,0) [0|40] "A" BMS
 SG_ OBC_MaxChrgOutpPwr : 33|10@0+ (0.1,0) [0|100] "kw" BMS
 SG_ Rolling_counter_0x613 : 59|4@0+ (1,0) [0|1] "" Vector__XXX

BO_ 1556 OBC_0x614: 8 OBC
 SG_ OBC_ChrgInsOutputVolt : 15|16@0+ (0.1,0) [0|600] "V" GW
 SG_ OBC_TempAct : 31|8@0+ (1,-40) [-40|215] "DegC" VCU,GW
 SG_ OBC_ElockSts : 39|2@0+ (1,0) [0|3] "" GW
 SG_ OBC_ChrgLockSts : 37|4@0+ (1,0) [0|7] "" VCU,GW
 SG_ OBC_RecoTimingSts : 33|1@0+ (1,0) [0|1] "" Vector__XXX

BO_ 1632 DCDC_0x660: 8 DCDC
 SG_ DCDC_OverTemp : 1|1@0+ (1,0) [0|1] "" GW
 SG_ DCDC_DischargeFail : 2|1@0+ (1,0) [0|1] "" GW
 SG_ DCDC_TBOX_WorkSts : 4|2@0+ (1,0) [0|3] "" GW
 SG_ DCDC_TBOX_TempFault : 5|1@0+ (1,0) [0|1] "" GW
 SG_ DCDC_InsideVolHig : 16|1@0+ (1,0) [0|1] "" GW
 SG_ DCDC_InsideVolLow : 17|1@0+ (1,0) [0|1] "" GW
 SG_ DCDC_OutputCurHig : 18|1@0+ (1,0) [0|1] "" GW
 SG_ DCDC_OutputVolHig : 19|1@0+ (1,0) [0|1] "" GW
 SG_ DCDC_OutputVolLow : 20|1@0+ (1,0) [0|1] "" GW
 SG_ DCDC_InputCurHig : 21|1@0+ (1,0) [0|1] "" GW
 SG_ DCDC_InputVolHig : 22|1@0+ (1,0) [0|1] "" GW
 SG_ DCDC_InputVolLow : 23|1@0+ (1,0) [0|1] "" GW
 SG_ DCDC_OutputOpen : 26|1@0+ (1,0) [0|1] "" GW
 SG_ DCDC_HardFail : 27|1@0+ (1,0) [0|1] "" GW
 SG_ DCDC_InsideShotCirc : 28|1@0+ (1,0) [0|1] "" GW
 SG_ DCDC_OutputShotCirc : 29|1@0+ (1,0) [0|1] "" GW
 SG_ DCDC_CommunTimeOut : 30|1@0+ (1,0) [0|1] "" GW
 SG_ DCDC_InsideCurHig : 31|1@0+ (1,0) [0|1] "" GW

BO_ 1793 VCU_0x701: 8 VCU
 SG_ VCU_WakeUpOBC : 7|64@0+ (1,0) [0|0] "" OBC

BO_ 1794 OBC_UDSDiag_ReqPhsy: 8 GW
 SG_ OBC_UDSDiag_ReqPhsy_0x702 : 7|64@0+ (1,0) [0|255] "" OBC

BO_ 1795 DCDC_UDSDiag_ReqPhsy: 8 GW
 SG_ DCDC_UDSDiag_ReqPhsy_0x703 : 7|64@0+ (1,0) [0|255] "" DCDC

BO_ 1802 OBC_UDSDiag_Resp: 8 OBC
 SG_ OBC_UDSDiag_Resp_0x70A : 7|64@0+ (1,0) [0|255] "" GW

BO_ 1803 DCDC_UDSDiag_Resp: 8 DCDC
 SG_ DCDC_UDSDiag_Resp_0x70B : 7|64@0+ (1,0) [0|255] "" GW

BO_ 1810 BMS_UDSDiag_ReqPhsy: 8 GW
 SG_ BMS_UDSDiag_ReqPhsy_0x712 : 7|64@0+ (1,0) [0|255] "" BMS

BO_ 1811 WPTC_UDSDiag_ReqPhsy: 8 GW
 SG_ WPTC_UDSDiag_ReqPhsy_0x713 : 7|64@0+ (1,0) [0|255] "" WPTC

BO_ 1812 MCU_UDSDiag_ReqPhsy: 8 GW
 SG_ MCU_UDSDiag_ReqPhsy_0x714 : 7|64@0+ (1,0) [0|255] "" MCU

BO_ 1818 BMS_UDSDiag_Resp: 8 BMS
 SG_ BMS_UDSDiag_Resp_0x71A : 7|64@0+ (1,0) [0|255] "" GW

BO_ 1819 WPTC_UDSDiag_Resp: 8 WPTC
 SG_ WPTC_UDSDiag_Resp_0x71B : 7|64@0+ (1,0) [0|255] "" GW

BO_ 1820 MCU_UDSDiag_Resp: 8 MCU
 SG_ MCU_UDSDiag_Resp_0x71C : 7|64@0+ (1,0) [0|255] "" GW

BO_ 1844 ACU_UDSDiag_ReqPhsy: 8 GW
 SG_ ACU_UDSDiag_ReqPhsy_0x734 : 7|64@0+ (1,0) [0|255] "" ACU

BO_ 1852 ACU_UDSDiag_Resp: 8 ACU
 SG_ ACU_UDSDiag_Resp_0x73C : 7|64@0+ (1,0) [0|255] "" GW

BO_ 1856 VCU_UDSDiag_ReqPhsy: 8 GW
 SG_ VCU_UDSDiag_ReqPhsy_0x740 : 7|64@0+ (1,0) [0|255] "" VCU

BO_ 1864 VCU_UDSDiag_Resp: 8 VCU
 SG_ VCU_UDSDiag_Resp_0x748 : 7|64@0+ (1,0) [0|255] "" GW

BO_ 2015 UDSDiag_ReqFunc: 8 GW
 SG_ UDSDiag_ReqFunc_0x7DF : 7|64@0+ (1,0) [0|255] "" ACU,WPTC,MCU,OBC,DCDC,BMS,VCU

CM_ "Version:V1.0,Date:2018/4/25,Author:李明,Review:,Approval:,Description:()基于EPS收发信号,创建初版;
Version:V1.1,Date:2018/4/26,Author:李明,Review:,Approval:,Description:()与博世华域开会讨论后更新如下 
1、EPS增加接收ESP_0x243报文发送的信号ESP_YawRateValue、ESP_YawrateValue_valid、ESP_LongAccSensor、ESP_LongAccSensorValid、ESP_LaterAccSensor、ESP_LaterAccSensorValid
2、删除信号SAS_Raw_SteerWheelAngle、SAS_Raw_SASStsSnsr、EPS_LDWControlStatus
3、新增报文EPS_0x177
4、删除EPS_0x260报文里的相关信号,只保留EPS_SafeLampRed、EPS_WarningLampYellow和EPS_DTCFlag;
Version:V1.2,Date:2018/4/27,Author:李明,Review:,Approval:,Description:()1、重新Layout EPS_0x17和EPS_0x17报文信号
2、跟新ESP_YawRateValue比例因子为0.05;
Version:V1.3,Date:2018/4/27,Author:李明,Review:,Approval:,Description:()增加VCU收发报文;
Version:V1.4,Date:2018/4/28,Author:李明,Review:,Approval:,Description:()增加OBC/DCDC/BMS收发信号列表;
Version:V1.5,Date:2018/4/29,Author:李明,Review:,Approval:,Description:()1、VCU_0x9A报文里删除VCU_MCUDirectionReq、VCU_DecelerationReq,
2、VCU_0x9B报文里删除VCU_ ComfortPTC_En、VCU_ BatHotPTC_En、VCU_Cruise_Sts、VCU_CCS_SpeedArm、
3、VCU_0x9B报文里增加VCU_ComfortPwrMax、VCU_BatCoolReq、VCU_BatCoolPwrMax、VCU_BatHotlPwrMax
4、增加VCU_0x9C报文;
Version:V1.6,Date:2018/5/2,Author:李明,Review:,Approval:,Description:()1、增加MCU收发信号
2、更改IFC节点名字为FDA,更改APA名字为APS
3、MCU增加发送0x20和0x125报文
4、定义Tbox发送0x21报文,定义CNFC发送0x22报文;
Version:V1.7,Date:2018/5/3,Author:李明,Review:,Approval:,Description:()1、删除MCU 0x124报文,MCU_AuthSts打包到0x120里
2、MCU 0x324报文周期改为100ms
3、更新DCDC/OBC/VCU/BMS信号;
Version:V1.8,Date:2018/5/7,Author:李明,Review:,Approval:,Description:()1、增加VCU/BMS/DCDC/CNFC/GW_PT NM报文
2、OBC增加0x614报文;
Version:V1.9,Date:2018/5/8,Author:李明,Review:,Approval:,Description:()1、BMS_0x105增加发送BMS_ChrRequest,OBC收
2、分配VCU接收OBC_ChrgAllowedSts;
Version:V2.0,Date:2018/5/9,Author:李明,Review:,Approval:,Description:()1、BMS增加接受OBC_0x610帧报文里的OBC_CC_Status和OBC_CP_Duty信号;
Version:V2.1,Date:2018/5/10,Author:李明,Review:,Approval:,Description:()1、增加 ESP_YawrateValue_valid 、ESP_LongAccSensorValid
、 ESP_LaterAccSensorValid信号值描述 
2、为避免ID冲突,增加EPS预留开发 ID EPS_Reserved_0x6D0到EPS_Reserved_0x6D6,后续视开发成熟度取消
3、增加整车UDS诊断功能寻址ID,增加EPS/DCDC/OBC/MCU/VCU/BMS/GW的Z诊断物理寻址ID和响应ID;
Version:V2.2,Date:2018/5/11,Author:李明,Review:,Approval:,Description:()1、增加RPTC_325和FPTC_326报文,更新AC_0x254和EAC_0x320信号定义
2、更新DCDC_ErrorLevel和DCDC_stMode信号定义,增加OBC_TempAct信号;
Version:V2.3,Date:2018/5/14,Author:李明,Review:,Approval:,Description:()1、BMS增加接收OBC_CCLineSts、OBC_ChrgSts、OBC_S2Sts
2、VCU增加接收OBC_TempAct
3、增加MPWC节点的发送报文;
Version:V2.4,Date:2018/5/16,Author:李明,Review:,Approval:,Description:()1、BMS增加发送0x114和0x117报文
2、删除BMS_HVIL3_State信号,更新BMS_State信号值描述
3、同时为VCU和BMS分配mule车和量产车车速信号,mule车车速使用GW_Mule_0x360报文内信号；量产车车速使用ESP_ABS_0x121报文内信号
4、BCM_0x247报文增加BCM_SSB1和BCM_SSB2信号
5、基于网关路由实现考虑删除GW_Mule_0x360报文里的BCM_powermode信号
6、0x150增加VCU_Charge_Connect_Mule和VCU_Pvalid_mule
7、0x102增加BMS_chargestatus_mule
8、更新VCU_Charge_Connect信号定义
9、分配BMS接收VCU_WaterPump1_ErrorSts、VCU_WaterPump2_ErrorSts和VCU_WaterPump3_ErrorSts
10、分配BMS接收MCU_DC_linkVoltage、MCU_DC_linkCurrent、DCDC_IdcHvCurr、DCDC_UdcHvVolt 
11、更改0x113报文ID为0x513,报文周期为500ms；更改0x114报文ID为0x514,报文周期为500ms;
Version:V2.5,Date:2018/5/17,Author:李明,Review:,Approval:,Description:()1、BMS分配接收VCU_PCAN_CheckCC2、EAC_Status、EAC_power、RPTC_WorkSts、RPTC_WorkPower;
Version:V2.6,Date:2018/5/22,Author:李明,Review:,Approval:,Description:()1、分配VCU接收BMS_PackI
2、更新VCU_BMS_WorkMode信号定义
3、更新EAC_0x320报文信号定义,更新AC_0x254报文信号定义;
Version:V2.7,Date:2018/5/23,Author:李明,Review:,Approval:,Description:()1、增加TBOX_0x221和NSM_0x222报文
2、取消MCU发送MCU_AuthReq_0x20报文,新增MCU发送CU_AuthResp_0x21报文,BCM发送
3、取消NSM_AuthResp_0x22和TBOX_AuthResp_0x21报文
4、BCM新增发送BCM_AuthReq_0x20报文,MCU接收;
Version:V2.8,Date:2018/5/29,Author:李明,Review:,Approval:,Description:()1、增加TBOX_0x351/TBOX_0x355/TBOX_NM_0x402报文
2、更新DCDC 0x188/0x660/0x389报文内信号定义
3、更新OBC 0x550/0x610/0x613/0x614报文内信号定义
4、EPS_0x175报文新增EPS_SteeringTorque信号;
Version:V2.9,Date:2018/5/30,Author:李明,Review:,Approval:,Description:()1、删除VCU_0x9B报文里VCU_ComfortPwrMax和VCU_BatHotlPwrMax
2、VCU_0x9B报文里增加VCU_WPTC_statstop和VCU_WPTC_BatHotlPwrSet、VCU_BatCoolingValve
3、更改CNFC名字为NSM,更改DNFC名字为NEM,更改FPTC名字为APTC,更改RPTC名字为WPTC
4、更新AC_0x254报文信号定义
5、分配VCU_BatCoolingValve为BMS接收
6、更新WPTC_0x325报文内信号定义;
Version:V3.0,Date:2018/6/5,Author:李明,Review:,Approval:,Description:()1、增加HU_0x3A4、HU_0x3A4和APL_0x5A6报文
2、增加SCM_0x282报文
3、增加TPMS_0x501、TPMS_0x502、ICM_0x3A0、ICM_0x415报文
4、更新防盗认证相关报文ID为BCM_AuthResp_0x21/BCM_AuthReq_0x18/MCU_AuthReq_0x20/TBOX_AuthResp_0x19
5、更新MCU_AuthSts的信号长度;
Version:V3.1,Date:2018/6/11,Author:李明,Review:,Approval:,Description:()1、增加NEM_0x354和NEM_NM_0x405报文
2、MPWC_0x500定义为NSM发送,删除MPWC节点
3、增加BCM_NM_0x401报文
4、增加HU_AVASworkcontrol和HU_AVAS_SoundSelect信号
5、增加HU_0x2DF和DSM_0x2A4报文
6、TBOX_0x351增加TBOX_DSM_HeatSW、TBOX_DSM_Hargtemp、TBOX_PSM_HeatSW、TBOX_PSM_Hargtemp
7、更新NEM_0x354和NSM_0x222报文信号定义
8、增加PLG_0x343报文;
Version:V3.2,Date:2018/6/17,Author:李明,Review:,Approval:,Description:()1、增加BCM_PLGDriverSW和BCM_PLGOutsideSW信号,分配为PLG接收
2、更新TBOX_PLG_TrunkControl定义分配为PLG接收
3、增加BCM_0x310报文
4、增加BCM_AntiThelf_Sts信号
5、增加BCM/PLG/DSM的诊断ID
6、增加以下节点的网络管理报文AC/RSE/Gwinfo/Gwbody/Gwtbox/DVR/WPTC/BCM/DSM/PLG
7、完善所有节点的诊断ID信息
8、调整表格格式;
Version:V3.3,Date:2018/6/20,Author:李明,Review:,Approval:,Description:()1、删除EPS_0x176报文里的EPS_LKATorsionBarTorque和EPS_LKATosionBarTorqueValid、EPS_LKAHandsoff_Status
2、删除EPS_0x177报文里的EPS_APATorsionBarTorque信号EPS_APATosionBarTorqueValid、EPS_APA_Steeringfeedback、EPS_LKAHandsoff_Mode
3、增加所有节点的版本信息报文（0x5E0到0x5EF/0x5D0到0x5DD）;
Version:V3.4,Date:2018/6/26,Author:李明,Review:,Approval:,Description:()1、增加SDA节点收发信号
2、增加MRR发送报文MRR_0x131和MRR_0x132
3、MCU收发相关 报文Checksum也异或上rolling counter的byte
4、定义VCU_0x9A_PT_Pr在VCU的私有CAN上发送、定义MCU_0x120_PT_Pr在VCU的私有CAN上发送、定义MCU_0x122_PT_Pr在VCU的私有CAN上发送
5、更新0x120报文MCU_WorkSts的startbit为44
6、更新0x120报文MCU_AuthSts的信号长度为3
7、更新0x122报文MCU_FaultLevel的startbit为33
8、MCU_0x123报文增加MCU_IsCurrent,并更新0x123报文layout
9、新增MCU_0x124报文
10、0x122,MCU_DeratingTempCoolant,startbit更新为
11、0x122,新增MCU_DeratingOverSpd、MCU_HVReady;
Version:V3.5,Date:2018/6/28,Author:李明,Review:,Approval:,Description:()1、新增ESP_EPB_0x244报文
2、更新MPC_245的信号定义
3、更新防盗相关报文0x18/0x19、0x20/0x21报文携带信号长度为64;
Version:V3.6,Date:2018/7/2,Author:李明,Review:,Approval:,Description:()1、更新ESP_AbsFlgFlt信号名字为ESC_ABSFailed
2、增加MRR_0x232和DVR_0x3F1报文
3、更新ACU_0x210报文内信号定义
4、更新HU_0x2DF报文内信号定义
5、更新DSM_0x2A4报文内信号定义
6、删除VCU_BatHotlPwrMax信号
7、VCU增加接收MCU_DC_linkVoltage和MCU_DC_linkCurrent、BMS_BattThermalReqLvl、OBC_CCLineSts
8、VCU增加发送VCU_0x200和VCU_0x9D报文
9、更新AC_0x356报文信号定义
10、WPTC_0x325报文增加发送WPTC_PowerMaxLim
11、更新VCU_CCS_Sts信号定义
12、VCU_0x9B报文删除VCU_AC_Enable信号,并且增加VCU_AC_ComfortEAC_En、VCU_AC_BatCoolEAC_En和VCU_AC_APTC_En
13、更改VCU_BatHotPTC_En信号名为VCU_WPTC_En
14、VCU_0x151报文增加VCU_FanPWM
15、AC接收VCU_WaterPump2_ErrorSts
16、新增AC_0x255报文发送AC_VCU_FanPWMReq、AC_VCU_APTCPwrReq和AC_VCU_EACPwrReq;
Version:V3.7,Date:2018/7/3,Author:李明,Review:,Approval:,Description:()1、删除VCU_PCAN_Geartplace1到VCU_PCAN_GeartplaceP信号 
2、BCM_0x380_LIN1增加发送RLS_Temperature和RLS_Humid信号
3、调整AC_0x254和AC_0x255相关信号定义
4、增加GW_info_0x260报文
5、增加BCM_0x299_LIN2_3报文和DSM_0x390报文;
Version:V3.8,Date:2018/7/8,Author:李明,Review:,Approval:,Description:()1、调整VCU_AC_ComfortEAC_En、VCU_AC_BatCoolEAC_En、VCU_AC_APTC_En至0x9D报文里
2、0x120, MCU_WorkSt信号,“0x0”的描述更改为“DrvInit” 0x122,MCU_FaultLevel更改为3bit,并更新信号值描述,startbit更新为34,MCU_DeratingTempCoolant_Pr的startbit更新为35
 3、VCU,MCU各增加一帧MCU_0x562和VCU_0x561,用于角度自学习
、 MCU增加接收ICM_0x3A0
4、PT 子网独立分开制定信号列表
5、删除VCU_BatCoolReq和VCU_BatCoolingValve、VCU_Charge_Connect_Mule、VCU_Pvalid_mule/BMS_chargestatus_mule
6、增加GW_0x256_PT报文,用于路由AC/EAC/APTC相关信号,并预留空位为后续使用
7、删除VCU_MCU_Sleep_En
8、更新MCU_FaultLevel信号定义;
Version:V3.9,Date:2018/7/11,Author:李明,Review:,Approval:,Description:()1、更新VCU_MotorOffsetCalCmd信号定义
2、增加VCU_OBC_RemoteCharge、VCU_OBC_CCCheck和VCU_OBC_ChargeLOCK信号
3、BMS0x116帧,信号名称变更： BMS_CharOverCurr => BMS_RegenOverCurr
4、BMS0x116帧增加信号： BMS_FCGOverCurr、BMS_SCGOverCur、 BMS_LiquidLeak、BMS_CrashFault、BMS_ThermRunAway
上述信号由TOX接收
5、VCU_0x200改为VCU_0x701
6、ESP_ABS_0x211ESP_ABS_0x121有VCU发出（适用于9月PT装车）;
Version:V4.0,Date:2018/7/15,Author:李明,Review:,Approval:,Description:()1、更新MCU_0x122和MCU_0x120信号定义,将0x122报文里ICM接收的MCU_OverSpdWarning、MCU_InverterTempWarning、MCU_MotorTempWarning、MCU_FaultLevel调整至0x122内发送
2、调整BMS_ChrSlowState和BMS_ChrFastState至0x100,调整BMS_HVIL1_State和BMS_HVIL2_State至0x102
3、调整VCU_BattPump_ErrorSts、VCU_KeyCycAverage_Energy、VCU_instantaneous_Energy、VCU_instantaneous_unit至0x9D报文里;
Version:V4.1,Date:2018/7/16,Author:李明,Review:,Approval:,Description:()1、删除VCU_instantaneous_unit
2、更新OBC和ECDC的物理寻址诊断请求ID和响应ID
3、增加DCDC_OutputOpen
4、OBC接收BCM_AntiThelf_Sts
5、VCU模拟发送ESP_0x243报文;
Version:V4.2,Date:2018/7/19,Author:李明,Review:,Approval:,Description:()1、更新DCDC_IdcHvCurr的比例因子为0.1
2、OBC取消接收VCU_CharLockSts信号
3、删除VCU_CharLockSts信号
4、更新HU_EnergyRecoveryMode信号定义;
Version:V4.3,Date:2018/7/23,Author:李明,Review:,Approval:,Description:()1、更新VCU_0x151的信号layout
2、更新VCU_AccPedPos的信号长度
3、增加VCU_OverRide信号;
Version:V4.4,Date:2018/7/24,Author:李明,Review:,Approval:,Description:()1、更新VCU_0x9B和VCU_0x9C的报文周期为20ms,
2、更新VCU_0x150报文周期为20ms,更新VCU_0x151报文周期为20ms
3、更新DCDC_0x188的周期为20ms;
Version:V4.5,Date:2018/8/8,Author:李明,Review:,Approval:,Description:()1、更新SCM_0x282的信号定义
2、0x9C报文增加VCU_HUDMS_Status和VCU_HUDMS_StatusValid 信号
3、更新VCU_OverRide的startbit
4、VCU_0x9C增加VCU_MCU_TrqReq_ToESP
5、更新VCU_WPTC_statstop为
6、增加VCU_WPTC_RAMP_SET
7、ESP_ABS_0x211改为GW发送,VCU接收
8、ESP_0x121改为GW发送
7、VCU增加发送VCU_0x130
8、ESP_0x243有GW发送
9、VCU增加接收ESP_0x214报文内信号
10、新增VCU_0x131报文
11、更新SCM_0x282的SCM_CC_Switch信号定义
12、VCU_0x150增加发送VCU_GearShiftInProgress和VCU_ShiftInProgress_Status;
Version:V4.6,Date:2018/9/6,Author:李明,Review:,Approval:,Description:()1、删除VCU_CurrentMotorTorqValid和VCU_DriverDemandTorqValid
2、增加HU_AccelerationMode、HU_ AccelerationModePer、HU_Onepedal、HU_CreepSwitch
3、VCU增加接收AC_OutTemperature 
4、VCU接收EPS_0x175报文内信号
5、VCU增加发送0x152报文
6、0x152报文增加VCU_TargetGear;
Version:V4.7,Date:2018/9/7,Author:李明,Review:,Approval:,Description:()1、分配VCU接收ACU_DrvSeatBeltSWSts,取消接收ACU_SBR_Driver
2、VCU增加接收BCM_ReadyLimit_Sts;
Version:V4.8,Date:2018/9/8,Author:李明,Review:,Approval:,Description:()1、删除VCU_0x152报文,将152报文内信号打包到其他报文里
2、更新0x150信号VCU_EnergyRecoveryPer的起始位,并增加Checksum_0x150和Rollingcounter_0x150
3、更新0x141报文信号定义;
Version:V4.9,Date:2018/9/9,Author:李明,Review:,Approval:,Description:()1、更新HU_LimitSpeedSet的startbit为31;
Version:V5.0,Date:2018/9/10,Author:李明,Review:,Approval:,Description:()1、VCU_0x142增加发送VCU_QECACC
2、EPS_0x175有GW发送;
Version:V5.1,Date:2018/9/15,Author:李明,Review:,Approval:,Description:()1、 0x100 继电器状态修改
   0x0: Open （断开）
   0x1: Close（闭合）
   0x2: Fault （故障)
   0x3: Debounce（预留）
2、0x102 
   删除 BMS_CellAddVol
3、 BMS_PackSOE 长度修改至10bit, 精度修改至0.1
4.、BMS_PackDispSoc 由0x100帧移至0x102帧
    BMS_PackDispSoc 长度修改至10bit,精度修改至0.1
5、0x116 增加 BMS_Maintenance
6、增加DCDC_TBOX_WorkSts和DCDC_TBOX_TempFault
7、调整VCU_0x141报文的信号layout
8、VCU_0x150报文增加发送VCU_12VbatteryError;
Version:V5.2,Date:19-9月-2018,Author:李明,Review:,Approval:,Description:()1、增加BMS_BattCodeString
2、增加VCU_0x371和VCU_0x372报文
3、删除0x9D里的VCU_instantaneous_Energy
4、更新DCDC_0x188的报文周期为100ms
5、VCU_0x9D增加VCU_RemoteACFeedback
6、调整VCU_KeyCycAverage_Energy至0x372
7、VCU_0x9A增加VCU_SlowChargeSt
8、BMS_0x105发送BMS_VCU_TotalEnergy
9、VCU接收AC_0x257报文内信号
10、VCU增加接收HU_SubMileage_Reset和HU_TrailerMode
11、VCU接收AC_WindModeSts
12、删除BMS_NM_0x412及BMS接收的NM报文;
Version:V5.3,Date:25-9月-2018,Author:李明,Review:,Approval:,Description:()1、更新DCDC_TBOX_WorkSts信号定义
2、VCU接收ESP_0x243报文里的ESC_APA_LC_Status
3、更新BMS_0x116的报文周期为100ms
4、更新BMS_VCU_TotalEnerg的比例因子
5、VCU增加ESP_TorqueIncrease和ESP_TorqueIncreaseSt;
Version:V5.4,Date:26-9月-2018,Author:李明,Review:,Approval:,Description:()1、VCU增加HU_DMS_SW
2、更新VCU_HUDMS_Status信号定义
3、新增DCDC_DischargeMode信号
4、更新DCDC_stMode信号定义
5、VCU增加接收TBOX_0x353报文内信号;
Version:V5.5,Date:27-9月-2018,Author:李明,Review:,Approval:,Description:()1、更新VCU_DMS_Status信号定义
2、增加VCU_DMS_SWStatus
3、删除VCU_FANPWM
4、VCU接收ESP_EBD_Intervention，ESP_TCS_Intervention，ESP_VDC_Intervention;
Version:V5.6,Date:25-10月-2018,Author:李明,Review:,Approval:,Description:()1、更新MCU_AuthSts的信号长度和信号值描述
2、MCU接收BCM_ReAuthRequest;
Version:V5.7,Date:26-10月-2018,Author:李明,Review:,Approval:,Description:()1、VCU接收MPC_LKS_LeftVisualization和MPC_LKS_RightVisualization
2、VCU增加发送VCU_0x373;
Version:V5.8,Date:27-10月-2018,Author:李明,Review:,Approval:,Description:()1、更新VCU_MotorOffsetCalCmd信号定义
2、VCU_0x150报文新增VCU_DriveableAlarm信号;
Version:V5.9,Date:11-12月-2018,Author:李明,Review:,Approval:,Description:()1、OBC取消接收BCM_AntiThelf_Sts，增加接收BCM_DriverLock_Sts
2、MCU 0x123增加发送MCU_MotorCount、MCU_MotorSeqNum信号，供TBOX接收使用
3、MCU 0x120增加发送MCU_FaultLampOn、MCU_OverTemp信号，供仪表接收使用
4、MCU_0x120和MCU_0x122报文周期改为100ms
5、VCU接收0x121报文ESP_VDC_TCS_Error
6、BMS发送报文，0x117 ID改为0x114
9、VCU增加发送VCU_0x117报文
10、VCU接收BMS_MaxTemp、BMS_MinTemp、BMS_MaxTempVld、BMS_MinTempVld
11、更新VCU_0x9A报文周期为100ms
12、GW转发AC_0x254、AC_0x255、EAC_0x320、APTC_0x326到PT CAN，分配VCU接收相关信号
13、更新VCU_InputWaterTemp和VCU_OutputWaterTemp信号值定义
14、VCU删除接收0x120/0x122/0x123报文内信号
15、更新BMS_0x513的报文内相关信号定义
16、0x5E1新增VCU_SoftMainVersion_in、VCU_SoftSubVersion_in、VCU_SoftPhase_in、VCU_SoftPhaseDescription_in
17、VCU新增发送VCU_0x563/VCU_0x52D/VCU_0x52E/VCU_0x52F/VCU_0x52B
18、VCU_0x373发送VCU_SlowChargeGunSt和VCU_FastChargeGunSt
19、OBC_0x5E4_Version增加发送OBC_HWVersion_Sub3和OBC_SWVersion_Sub3
20、OBC取消接收BMS_0x306信号
21、删除DCDC_NM_0x411报文，DCDC取消接收相关NM报文;
Version:V6.0,Date:26-12月-2018,Author:李明,Review:,Approval:,Description:()1、更新TBOX_VCU_RemoteChargetime、TBOX_VCU_12vChargeReq、TBOX_VCU_TimeCharge、TBOX_VCU_RemoteChargeper的信号起始位
2、更新MCU_0x120的报文周期为20ms;
Version:V6.1,Date:27-12月-2018,Author:李明,Review:,Approval:,Description:()1、更新VCU_RemoteACFeedback和VCU_MotorOffsetCalCm、VCU_TBOX_SlowChargeSt信号值定义
2、VCU增加接收TBOX_0x355_Time报文内信号
3、更新VCU_0x52B、VCU_0x52D、VCU_0x52E、VCU_0x52F的信号定义
4、VCU接收AC_FdefrostSts;
Version:V6.2,Date:28-12月-2018,Author:李明,Review:,Approval:,Description:()1、VCU取消接收AC_FdefrostSts
2、VCU_0x9C报文VCU_LimitSpeedAlarm变更为VCU_LimitSpeedAlarm_L，新增VCU_LimitSpeedAlarm_V
3、更新HU_EnergyRecoveryPer、HU_LimitSpeedSet、HU_AccelerationModePer信号值范围
4、更新HU_0x2DE_PT报文内所有信号发送类型都为OnChange
5、删除VCU接收HU_TrailerMode
6、VCU接收HU_LogoslampSW信号
7、VCU_0x9C报文新增发送VCU_LogoslampSW;
Version:V6.3,Date:07-1月-2018,Author:李明,Review:,Approval:,Description:()1、增加ESP_TorqueIncreaseSt的信号值描述
2、更新ESP_WheelDirection_FR_Valid的初始值为0x0
3、更新VCU_ErrorLevel信号定义
4、VCU_0x9B增加发送VCU_infoCAN_sleepenableflg、VCU_BodyCAN_sleepenableflg、VCU_TboxCAN_sleepenableflg;
Version:V6.4,Date:10-1月-2018,Author:李明,Review:,Approval:,Description:()1、VCU_0x9B删除发送VCU_infoCAN_sleepenableflg、VCU_BodyCAN_sleepenableflg、VCU_TboxCAN_sleepenableflg
2、VCU删除接收HU_LogoslampSW;
Version:V6.5,Date:11-1月-2018,Author:李明,Review:,Approval:,Description:()1、VCU增加接收AC_RemoteAC
2、VCU_0x9C报文删除发送VCU_LogoslampSW;
Version:V6.6,Date:16-1月-2019,Author:李明,Review:,Approval:,Description:()1、VCU接收ICM_SubMileage_Reset
2、VCU_0x151增加发送VCU_APS_WorkStatus
3、VCU接收APS_VCU_Req_StraightOut、APS_VCU_Gear_Request、APS_VCU_Req_StraightCtrol
4、ACU接收APS_ACU_DrvSeatBeltSWSts;
Version:V6.7,Date:29-1月-2019,Author:李明,Review:,Approval:,Description:()1、VCU接收PA_DistFront_0x194和PA_DistFront_0x195报文内信号;
Version:V6.8,Date:30-1月-2019,Author:李明,Review:,Approval:,Description:()1、更新BCM_0x90报文发送类型为event;
Version:V6.9,Date:25-2月-2019,Author:李明,Review:,Approval:,Description:()1、BMS接收TBOX_0x355_Time报文内信号
2、更新BCM_0x90的BCM_ReAuthRequest信号描述;
Version:V7.0,Date:13-3月-2019,Author:李明,Review:,Approval:,Description:()1、0x9B新增发送VCU_ACU_DrvSeatBeltSWSts，ACU接收
2、取消ACU接收APS_ACU_DrvSeatBeltSWSts;
Version:V7.1,Date:20-3月-2019,Author:李明,Review:,Approval:,Description:()1、VCU接收BMS_ISOWaring
2、更新VCU_APS_WorkStatus的信号定义;
Version:V7.2,Date:20-3月-2019,Author:李明,Review:,Approval:,Description:()1、VCU接收Checksum_0x282和Counter_0x282;
Version:V7.3,Date:21-3月-2019,Author:李明,Review:,Approval:,Description:()1、增加RMCU节点，并且定义RMCU发送RMCU_0x334、RMCU_0x130、RMCU_0x132、RMCU_0x133、RMCU_0x134、RMCU_0x5C2_Version、RMCU_UDSDiag_ReqPhsy、RMCU_UDSDiag_Resp、VCU_0x32B
2、更新MCU的名字为为FMCU，并更新所有报文和信号定义
3、RMCU_0x130报文定义发送RMCU_HVLock
4、RMCU_0x132报文定义发送RMCU_MotoroffsetCalReq;
Version:V7.4,Date:22-3月-2019,Author:田雨,Review:李明,Approval:,Description:()1.删除BMS_SCGOverCurr
2.修改BMS_FCGOverCurr快充电过流为BMS_CGOverCurr充电过流故障。
3.修改BMS_RegenOverCurr充电过流为回馈电流过大
4.增加BMS_LowVoltageFault低压电源故障故障
5.增加BMS_Bus-barTempOverWaring汇流排过温
6.在0x100增加BMS_WakeUpSignal BMS唤醒信号KL15
7.在0x105增加BMS_PackSOH 电池生命健康度
8.0x591
  BMS_BattSupplierCode
  BMS_BattSpecCode 物理最大值及总线最大值变更
9.0x5E0
  BMS_TotalChargingTimes 删除
  BMS_PackEnergy 增加
  BMS_CellSupplier 增加
10.0x594
BMS_BattCodeString 删除
11、更新BMS_0x5E0_Version内BMS_SWVersion_Supplier和BMS_SWVersion_Main信号值描述;
Version:V7.5,Date:25-3月-2019,Author:李明,Review:,Approval:,Description:()1.更新VCU_APS_WorkStatus的信号定义;
Version:V201.190415,Date:15-4月-2019,Author:李明,Review:,Approval:,Description:()1、版本号从V7.5升级到V201.190415
2、DCDC取消接收BMS_0x100其中所有信号
3、DCDC取消接收ACU_0x210其中所有信号
4、OBC 0x614增加信号OBC_ChrgLockSts，VCU接收
5、OBC 0x614增加信号OBC_RecoTimingSts
6、OBC 0x5E4删掉OBC_HWVersion_Sub3和OBC_SWVersion_Sub3信号
7、BMS接收EAC_0x320报文内的EAC_power和EAC_Status，取消接收GW_0x256_PT报文内GW_EAC_power和GW_EAC_Status
8、删除GW_0x256_PT报文
9、VCU_0x9B新增发送VCU_OBC_ChrgLock，OBC接收
10、VCU_0x9B新增发送VCU_ChrgLockSts
11、VCU_0x117新增VCU_RecoTiming
12、VCU_0x9C增加发送VCU_DriveInhibitAlarm
13、VCU增加发送TBOX_VCU_RemoteChrgLock
14、VCU接收HU_VCU_RemoteChrgLock
15、VCU_0x563删除VCU_CheckCC2信号
16、VCU取消接收APS_VCU_Gear_Request
17、VCU_0x561增加发送VCU_MotorcoV和VCU_BattcolV
18、VCU接收ESP_EBD_Error、ESP_VLC_Error
19、FMCU增加接收Rolling_counter_0x9A;
Version:V202.190515,Date:15-5月-2019,Author:李明,Review:,Approval:,Description:()1.0x562帧增加FMCU_MotorSts_GBT信号，TBOX接收，用于GBT32960上传
2、VCU_0x9C增加发送VCU_EPB_FunctionSet
3、VCU_0x151报文内信号VCU_HVLock信号名更细为VCU_HVLock_ALL
4、VCU_0x151报文新增VCU_HVLock_self,Tbox接收
5、VCU_0x9C增加发送VCU_HU_ChrgLockSts;
Version:V203.190515,Date:16-5月-2019,Author:李明,Review:,Approval:,Description:()1、删除RMCU相关信号，FMCU改为MCU;
Version:V204.1907,Date:04-7月-2019,Author:李明,Review:,Approval:,Description:()1、VCU接收Checksum_0x353和RollingCounter_0x353、Checksum_0x550、Rolling_counter_0x550
2、BMS接收Checksum_0x9B和Rolling_counter_0x9B
3、VCU接收APS_R_Gear_RequestTips
4、VCU_0x141删除VCU_AccelerationMode和VCU_Onepedal
5、VCU_0x141增加发送VCU_DriveMode
6、VCU_0x150删除VCU_EnergyRecoveryMode
7、VCU删除接收HU_AccelerationMode、HU_EnergyRecoveryMode、HU_Onepedal
8、VCU接收HU_DriveMode
9、VCU_0x150增加发送VCU_GearFlashReq;
Version:V205.1900715,Date:15-7月-2019,Author:李明,Review:,Approval:,Description:()1、VCU_0x9C新增发送VCU_SlowChargeLight和VCU_FastChargeLight
2、更新TBOX_VCU_TimeCharge信号值描述
3、VCU接收GW_IBS_0x334和GW_IBS_0x335报文内信号
4、VCU_0x9D增加发送 VCU_FanSts;
Version:V206.1900724,Date:24-7月-2019,Author:李明,Review:,Approval:,Description:()1、更新VCU接收的HU_DriveMode的起始位为39
2、更新VCU_FMotorOffsetCalCmd信号名称为VCU_MotorOffsetCalCmd
3、更新VCU_FMotorPumpFB_PWM信号名字为VCU_MotorPumpFB_PWM;
Version:V207.190815,Date:15-8月-2019,Author:李明,Review:,Approval:,Description:()1、VCU_0x9D增加发送VCU_12VbatterySOHLow和VCU_LVSmartChrg_Status  2、VCU取消接收GW_IBS_0x334和GW_IBS_0x335报文里不必要的信号
3、BMS_0x590中的BMS_BattManuYear、BMS_BattManuMonth、BMS_BattManuDay信号修改“物理最小值”、“物理最大值”、“总线最小值”“总线最大值”、“初始值”
4、BMS增加接收ACU_0x210报文信号Checksum_0x210和RollingCounter_0x210
5、BMS_0x102中BMS_Insulation_R初始值修改为0x3FE；
6、BMS_0x116中增加BMS_LowVoltageMSD低压MSD状态；
7、BMS_0x116中增加BMS_FuseFault电池熔断器故障
8、BMS_0x100中BMS_ChrFastState=0x2的描述由“充电结束”修改为“充电完成”
9、BMS_0x100中BMS_ChrSlowState=0x2的描述由“充电结束”修改为“充电完成”
10、BMS_0x116调整BMS_CurrSensorFault的起始位，信号长度修改为2个bit。
11、VCU增加接收HU_ChargeDepthSet和TBOX_ChargeDepthSet
12、GW取消接收BMS_0x114报文
13、GW增加接收BMS_0x115、WPTC_0x325、VCU_0x52B、VCU_0x52C、VCU_0x52D、VCU_0x52E、VCU_0x52F、VCU_0x561、VCU_0x563;
 ";

CM_ SG_ 820 IBS_U_BATT "Battery voltage";
CM_ SG_ 820 IBS_I_Range "Battery current range";
CM_ SG_ 820 IBS_I_BATT "Battery current（此信号的Resolution是可变的，信号解析请参考博世提供的IBS功能规范）";
CM_ SG_ 820 IBS_T_BATT "Battery temperature";
CM_ SG_ 820 IBS_IBATT_QUIESCENT "Battery quiescent
current";
CM_ SG_ 820 IBS_Status_Current "current Status";
CM_ SG_ 820 IBS_Status_Voltage "Voltage Status";
CM_ SG_ 820 IBS_Status_Temp "Temperature Status ";
CM_ SG_ 820 IBS_ERROR_Calib "error in calibration data";
CM_ SG_ 820 IBS_ERROR_IDENT "error in ECU indentification";
CM_ SG_ 820 IBS_Resp_Error "LIN Response Error ";
CM_ SG_ 820 IBS_FLAG_INCONSISTENCY "Battery inconsistency flag";
CM_ SG_ 821 IBS_SOC "State of Charge ";
CM_ SG_ 821 IBS_SOH_SUL "max. possible SOC, reduced by sulphation";
CM_ SG_ 821 IBS_SOFV_StopEnable "Battery voltage at cranking peak with pre-discharge";
CM_ SG_ 821 IBS_SOFV_Restart "Battery voltage at cranking peak without pre-discharge";
CM_ SG_ 821 IBS_SOH_LAM "State of health (Loss of active mass)";
CM_ SG_ 821 IBS_SOH_COR "State of health (corrosion)";
CM_ SG_ 821 IBS_SOC_STATE "SOC Status";
CM_ SG_ 821 IBS_SOH_SUL_STATE "SOH_SUL Status ";
CM_ SG_ 821 IBS_SOFV_StopEnable_STATE "SOFV_StopEnable
Status";
CM_ SG_ 821 IBS_SOFV_Restart_STATE "SOFV_Restart Status";
CM_ SG_ 821 IBS_SOH_LAM_STATE "SOH_LAM Status";
CM_ SG_ 821 IBS_SOH_COR_STATE "SOH_COR Status";
CM_ SG_ 404 Checksum_0x194 "Checksum: IDMSB XOR IDLSB XOR Byte1 XOR Byte2 XOR Byte3 XOR Byte4 XOR Byte5 XOR Byte6 XOR Byte7";
CM_ SG_ 404 PA_APA_DistanceValueLR_FL "左前长距离雷达探测障碍物距离值（高配）";
CM_ SG_ 404 PA_APA_DistanceValueLR_FR "右前长距离雷达探测障碍物距离值（高配）";
CM_ SG_ 404 PA_APA_DistanceValueSR_FL "左前短距离雷达探测障碍物距离值（高配）";
CM_ SG_ 404 PA_APA_DistanceValueSR_FML "左中前短距离雷达探测障碍物距离值（高配）";
CM_ SG_ 404 PA_APA_DistanceValueSR_FMR "右中前短距离雷达探测障碍物距离值（高配）";
CM_ SG_ 404 PA_APA_DistanceValueSR_FR "右前短距离雷达探测障碍物距离值（高配）";
CM_ SG_ 404 RollingCounter_0x194 "RollingCounter: used 4bit length signal and the arithmetic is increased from 0 to 15 by every message.";
CM_ SG_ 405 Checksum_0x195 "Checksum: IDMSB XOR IDLSB XOR Byte1 XOR Byte2 XOR Byte3 XOR Byte4 XOR Byte5 XOR Byte6 XOR Byte7";
CM_ SG_ 405 PA_APA_DistanceValueLR_RL "左后长距离雷达探测障碍物距离值（高配）";
CM_ SG_ 405 PA_APA_DistanceValueLR_RR "右后长距离雷达探测障碍物距离值（高配）";
CM_ SG_ 405 PA_APA_DistanceValueSR_RL "左后短距离雷达探测障碍物距离值（高配";
CM_ SG_ 405 PA_APA_DistanceValueSR_RML "左中后短距离雷达探测障碍物距离值（高配）";
CM_ SG_ 405 PA_APA_DistanceValueSR_RMR "右中后短距离雷达探测障碍物距离值（高配）";
CM_ SG_ 405 PA_APA_DistanceValueSR_RR "右后短距离雷达探测障碍物距离值（高配）";
CM_ SG_ 405 RollingCounter_0x195 "RollingCounter: used 4bit length signal and the arithmetic is increased from 0 to 15 by every message.";
CM_ SG_ 401 Checksum_0x191 "Checksum: IDMSB XOR IDLSB XOR Byte1 XOR Byte2 XOR Byte3 XOR Byte4 XOR Byte5 XOR Byte6 XOR Byte7";
CM_ SG_ 401 APS_R_Gear_RequestTips "换入R档请求";
CM_ SG_ 401 APS_VCU_Req_StraightOut "APS请求遥控直出或者直入的握手请求";
CM_ SG_ 401 APS_VCU_Gear_Request "APS请求换挡";
CM_ SG_ 401 APS_VCU_Req_StraightCtrol "APS请求遥控直出、直入或者停止命令";
CM_ SG_ 401 APS_ACU_DrvSeatBeltSWSts "APS请求安全带信号（预留）";
CM_ SG_ 401 RollingCounter_0x191 "RollingCounter: used 4bit length signal and the arithmetic is increased from 0 to 15 by every message.";
CM_ SG_ 599 AC_RemoteAC "空调远程控制请求";
CM_ SG_ 1323 VCU_State0 "VCU状态0";
CM_ SG_ 1323 VCU_State1 "VCU状态1";
CM_ SG_ 1323 VCU_State2 "VCU状态2";
CM_ SG_ 1323 VCU_State3 "VCU状态3";
CM_ SG_ 1323 VCU_State4 "VCU状态4";
CM_ SG_ 1323 VCU_State5 "VCU状态5";
CM_ SG_ 1323 VCU_State6 "VCU状态6";
CM_ SG_ 1323 VCU_State7 "VCU状态7";
CM_ SG_ 1325 VCU_ErrorCode0 "VCU故障码0";
CM_ SG_ 1325 VCU_ErrorCode1 "VCU故障码1";
CM_ SG_ 1325 VCU_ErrorCode2 "VCU故障码2";
CM_ SG_ 1325 VCU_ErrorCode3 "VCU故障码3";
CM_ SG_ 1325 VCU_ErrorCode4 "VCU故障码4";
CM_ SG_ 1325 VCU_ErrorCode5 "VCU故障码5";
CM_ SG_ 1325 VCU_ErrorCode6 "VCU故障码6";
CM_ SG_ 1325 VCU_ErrorCode7 "VCU故障码7";
CM_ SG_ 1326 VCU_ErrorCode8 "VCU故障码8";
CM_ SG_ 1326 VCU_ErrorCode9 "VCU故障码9";
CM_ SG_ 1326 VCU_ErrorCode10 "VCU故障码10";
CM_ SG_ 1326 VCU_ErrorCode11 "VCU故障码11";
CM_ SG_ 1326 VCU_ErrorCode12 "VCU故障码12";
CM_ SG_ 1326 VCU_ErrorCode13 "VCU故障码13";
CM_ SG_ 1326 VCU_ErrorCode14 "VCU故障码14";
CM_ SG_ 1326 VCU_ErrorCode15 "VCU故障码15";
CM_ SG_ 1327 VCU_ErrorCode16 "VCU故障码16";
CM_ SG_ 1327 VCU_ErrorCode17 "VCU故障码17";
CM_ SG_ 1327 VCU_ErrorCode18 "VCU故障码18";
CM_ SG_ 1327 VCU_ErrorCode19 "VCU故障码19";
CM_ SG_ 1327 VCU_ErrorCode20 "VCU故障码20";
CM_ SG_ 1327 VCU_ErrorCode21 "VCU故障码21";
CM_ SG_ 1327 VCU_ErrorCode22 "VCU故障码22";
CM_ SG_ 1327 VCU_ErrorCode23 "VCU故障码23";
CM_ SG_ 1379 VCU_CCOut "交流充电枪信号";
CM_ SG_ 1379 VCU_MotorPumpFB_PWM "前电机水泵反馈占空比";
CM_ SG_ 1379 VCU_FastCharge_A "直流枪A+信号";
CM_ SG_ 1379 VCU_CC2 "直流枪CC2电压";
CM_ SG_ 1379 VCU_BatPumpFB_PWM "电池水泵反馈占空比";
CM_ SG_ 596 AC_WindModeSts "当前吹风模式";
CM_ SG_ 596 AC_OutTemperature "车外温度";
CM_ SG_ 597 AC_VCU_FanPWMReq "冷却风扇PWM请求";
CM_ SG_ 597 AC_VCU_APTCPwrReq "空气PTC请求功率";
CM_ SG_ 597 AC_VCU_EACPwrReq "压缩机请求功率";
CM_ SG_ 800 EAC_power "压缩机工作功率";
CM_ SG_ 800 EAC_Status "Compressor state：压缩机状态位";
CM_ SG_ 806 APTC_WorkSts "APTC工作状态";
CM_ SG_ 806 APTC_WorkPower "APTC实际工作功率";
CM_ SG_ 806 APTC_ErrorLevel "APTC故障等级";
CM_ SG_ 582 MPC_LKS_LeftVisualization "Left line tracking status";
CM_ SG_ 582 MPC_LKS_RightVisualization "Right line tracking status";
CM_ SG_ 144 BCM_ReAuthRequest "请求MCU/EMS重新发起认证(触发一次至少100ms周期发5帧）";
CM_ SG_ 851 Checksum_0x353 "Checksum: IDMSB XOR IDLSB XOR Byte1 XOR Byte2 XOR Byte3 XOR Byte4 XOR Byte5 XOR Byte6 XOR Byte7";
CM_ SG_ 851 TBOX_VCU_12vChargeReq "小电瓶充电请求
(无控制请求时，发送0x0。当激活控制命令时，发送0x1。连续发送5次，之后将控制信号重新置0x0)";
CM_ SG_ 851 TBOX_VCU_TimeCharge "定时充电请求信号";
CM_ SG_ 851 TBOX_ChargeDepthSet "充电深度设置";
CM_ SG_ 851 TBOX_VCU_RemoteChrgLock "远程解锁电子锁";
CM_ SG_ 851 RollingCounter_0x353 "RollingCounter: used 4bit length signal and the arithmetic is increased from 0 to 15 by every message.";
CM_ SG_ 881 VCU_instantaneous_Energy "瞬时能耗";
CM_ SG_ 881 VCU_instantaneous_EnergyUnit "瞬时能耗单位";
CM_ SG_ 881 VCU_TrailerMode "拖车模式";
CM_ SG_ 881 VCU_trip "小计里程";
CM_ SG_ 881 VCU_ChargeIncreaseMileage "充电增加里程";
CM_ SG_ 882 VCU_SubtotalAverageEnergy "小计百公里能耗";
CM_ SG_ 882 VCU_SubtotalEnergy "小计能耗";
CM_ SG_ 882 VCU_Subtotaltime "小计里程时间";
CM_ SG_ 882 VCU_ChargeIncreaseMileageSpeed "充电里程增加速率";
CM_ SG_ 883 VCU_DST "本次里程";
CM_ SG_ 883 VCU_SingleMileageAverageEnergy "本次百公里能耗";
CM_ SG_ 883 VCU_SingleMileageEnergy "本次能耗";
CM_ SG_ 883 VCU_SingleMileagetime "本次里程时间";
CM_ SG_ 883 VCU_SlowChargeGunSt "交流枪状态";
CM_ SG_ 883 VCU_FastChargeGunSt "直流枪状态";
CM_ SG_ 32 MCU_AuthReq_BCM_Code "动力防盗认证随机码";
CM_ SG_ 33 BCM_AuthResp_MCU_Code "BCM动力防盗认证反馈码";
CM_ SG_ 154 Checksum_0x9A "Checksum: IDMSB XOR IDLSB XOR Byte1 XOR Byte2 XOR Byte3 XOR Byte4 XOR Byte5 XOR Byte6 XOR Byte7";
CM_ SG_ 154 VCU_ErrorLevel "VCU故障等级";
CM_ SG_ 154 VCU_MCU_WorkMode "VCU控制MCU工作模式";
CM_ SG_ 154 VCU_MCU_TrqReq "VCU控制电机目标扭矩";
CM_ SG_ 154 VCU_MCU_SpdReq "VCU控制电机目标转速";
CM_ SG_ 154 VCU_MotorOffsetCalCmd "电机角度自学习条件准备状态";
CM_ SG_ 154 Rolling_counter_0x9A "RollingCounter: used 4bit length signal and the arithmetic is increased from 0 to 15 by every message.";
CM_ SG_ 155 Checksum_0x9B "Checksum: IDMSB XOR IDLSB XOR Byte1 XOR Byte2 XOR Byte3 XOR Byte4 XOR Byte5 XOR Byte6 XOR Byte7";
CM_ SG_ 155 VCU_BMS_WorkMode "VCU控制BMS工作模式";
CM_ SG_ 155 VCU_DC_WorkMode "VCU控制DC工作模式";
CM_ SG_ 155 VCU_WPTC_En "WPTC使能";
CM_ SG_ 155 VCU_DC_VoltageReq "VCU控制DC输出电压";
CM_ SG_ 155 VCU_WPTC_Request "WPTC开启模式请求";
CM_ SG_ 155 VCU_OBC_RemoteCharge "远程充电请求";
CM_ SG_ 155 VCU_WPTC_BatHotlPwrSet "水PTC目标功率档位";
CM_ SG_ 155 VCU_OBC_ChrgLock "充电枪电子锁控制命令";
CM_ SG_ 155 VCU_TBOX_ChrgLockSts "VCU 电子锁状态反馈给TBOX";
CM_ SG_ 155 VCU_ACU_DrvSeatBeltSWSts "VCU请求安全带信号";
CM_ SG_ 155 VCU_OBC_ChrgEnable "VCU控制OBC工作模式";
CM_ SG_ 155 Rolling_counter_0x9B "RollingCounter: used 4bit length signal and the arithmetic is increased from 0 to 15 by every message.";
CM_ SG_ 156 Checksum_0x9C "Checksum: IDMSB XOR IDLSB XOR Byte1 XOR Byte2 XOR Byte3 XOR Byte4 XOR Byte5 XOR Byte6XOR Byte7";
CM_ SG_ 156 VCU_Cruise_Sts "巡航状态";
CM_ SG_ 156 VCU_DriveInhibitAlarm "行车禁止提醒";
CM_ SG_ 156 VCU_EPB_FunctionSet "VCU请求EPB控制";
CM_ SG_ 156 VCU_HU_ChrgLockSts "VCU 电子锁状态反馈给HU";
CM_ SG_ 156 VCU_CCS_SpeedArm "定速巡航目标车速";
CM_ SG_ 156 VCU_SpeedLimitSWSts "车速限制功能状态";
CM_ SG_ 156 VCU_DMS_Status "驾驶员疲劳状态";
CM_ SG_ 156 VCU_DMS_SWStatus "驾驶员疲劳开关状态";
CM_ SG_ 156 VCU_LimitSpeed "当前限速值设置范围：0~200KM/H
设置的间隔：1km/h";
CM_ SG_ 156 VCU_LimitSpeedAlarm_L "限速报警光触发";
CM_ SG_ 156 VCU_LimitSpeedAlarm_V "限速报警声音触发";
CM_ SG_ 156 VCU_SlowChargeLight "VCU控制慢充充电指示灯工作模式";
CM_ SG_ 156 VCU_FastChargeLight "VCU控制快充充电指示灯工作模式";
CM_ SG_ 156 Rolling_counter_0x9C "RollingCounter: used 4bit length signal and the arithmetic is increased from 0 to 15 by every message.";
CM_ SG_ 157 VCU_AC_ComfortEAC_En "舒适性压缩机使能";
CM_ SG_ 157 VCU_AC_BatCoolEAC_En "电池冷却压缩机使能";
CM_ SG_ 157 VCU_AC_APTC_En "空气PTC使能";
CM_ SG_ 157 VCU_AC_APTCPwrSet "空气PTC目标功率";
CM_ SG_ 157 VCU_AC_EACPwrSet "压缩机目标功率";
CM_ SG_ 157 VCU_FanPWMSts "冷却风扇PWM占空比";
CM_ SG_ 157 VCU_BattPump_ErrorSts "电池水泵故障状态";
CM_ SG_ 157 VCU_RemoteACFeedback "远程空调反馈";
CM_ SG_ 157 VCU_FanSts "风扇状态";
CM_ SG_ 157 VCU_12VbatterySOHLow "12V Battery SOH Low";
CM_ SG_ 157 VCU_LVSmartChrg_Status "VCU LV Smart Charge Status";
CM_ SG_ 256 BMS_PackU "电池电压";
CM_ SG_ 256 BMS_WaringLevel "电池报警等级";
CM_ SG_ 256 BMS_PackI "电池电流";
CM_ SG_ 256 BMS_RelayChrPos "快充正接触器状态";
CM_ SG_ 256 BMS_RelayNeg "总负接触器状态";
CM_ SG_ 256 BMS_RelayPre "预充电接触器状态";
CM_ SG_ 256 BMS_RelayPos "总正接触器状态";
CM_ SG_ 256 BMS_RelayChrNeg "快充负接触器状态";
CM_ SG_ 256 BMS_State "BMS工作状态";
CM_ SG_ 256 BMS_ChrFastState "直流充电状态";
CM_ SG_ 256 BMS_SPreCharging "预充电状态";
CM_ SG_ 256 BMS_ChrSlowState "交流充电状态";
CM_ SG_ 256 BMS_0x100_RollingCounter "从0到15循环计数，如果通信中断，则重新从0开始计数。";
CM_ SG_ 258 BMS_RealSOC "电池实际SOC
允许跳变";
CM_ SG_ 258 BMS_PackDispSoc "仪表显示SOC";
CM_ SG_ 258 BMS_PackSOE "电池剩余能量";
CM_ SG_ 258 BMS_WakeUpSignal "BMS唤醒信号KL15状态";
CM_ SG_ 258 BMS_Insulation_R "绝缘电阻值
最大值1000KΩ";
CM_ SG_ 258 BMS_LinkU "电池预充电电压";
CM_ SG_ 258 BMS_BalanceSts "电池均衡状态";
CM_ SG_ 258 BMS_HVIL1_State "HVIL1状态";
CM_ SG_ 258 BMS_HVIL2_State "HVIL2状态";
CM_ SG_ 258 BMS_0x102_RollingCounter "从0到15循环计数，如果通信中断，则重新从0开始计数。";
CM_ SG_ 261 BMS_PackSOH "电池生命健康度";
CM_ SG_ 261 BMS_ChrRequestU "充电电压请求";
CM_ SG_ 261 BMS_ChrRequest "充电请求";
CM_ SG_ 261 BMS_ChrRequestI "充电电流请求";
CM_ SG_ 261 BMS_VCU_TotalEnergy "总能耗";
CM_ SG_ 261 BMS_0x105_RollingCounter "从0到15循环计数，如果通信中断，则重新从0开始计数。";
CM_ SG_ 274 BMS_MaxCellNo "电池最高单体电压编号";
CM_ SG_ 274 BMS_MaxCellU "电池最高单体电压";
CM_ SG_ 274 BMS_MinCellNo "电池最低单体电压编号";
CM_ SG_ 274 BMS_MinCellU "电池最低单体电压";
CM_ SG_ 274 BMS_CellVolDev "电池单体压差";
CM_ SG_ 274 BMS_0x112_RollingCounter "从0到15循环计数，如果通信中断，则重新从0开始计数。";
CM_ SG_ 277 BMS_MaxDschPower "电池最大可持续放电功率";
CM_ SG_ 277 BMS_MaxDschPowerPeak "电池最大峰值放电功率";
CM_ SG_ 277 BMS_DschAllowedPower "电池允许放电功率";
CM_ SG_ 277 BMS_MaxChrgPowerPeak "电池最大峰值充电功率";
CM_ SG_ 277 BMS_MaxChrgPower "电池最大可持续充电功率";
CM_ SG_ 277 BMS_ChrgAllowedPower "电池允许充电功率";
CM_ SG_ 277 BMS_0x115_RollingCounter "从0到15循环计数，如果通信中断，则重新从0开始计数。";
CM_ SG_ 278 BMS_CellOverVolWaring "单体过压
GBT 32960.3 T18-5";
CM_ SG_ 278 BMS_CellUnderVolWaring "单体欠压
GBT 32960.3 T18-6";
CM_ SG_ 278 BMS_TempOverWaring "温度过高
GBT 32960.3 T18-1";
CM_ SG_ 278 BMS_TempUnderWaring "温度过低";
CM_ SG_ 278 BMS_CellVolDevWaring "压差过大
GBT 32960.3 T18-10";
CM_ SG_ 278 BMS_TempDveWaring "温差过大
GBT 32960.3 T18-0";
CM_ SG_ 278 BMS_BattOverVolWaring "电池包过压
GBT 32960.3 T18-2";
CM_ SG_ 278 BMS_BattUnderVolWaring "电池包欠压
GBT 32960.3 T18-3";
CM_ SG_ 278 BMS_DCChargePlugTempOverHigh "快充枪过温故障";
CM_ SG_ 278 BMS_DisCharOverCurr "放电过流";
CM_ SG_ 278 BMS_RegenOverCurr "回馈电流过大";
CM_ SG_ 278 BMS_InnerCANTimeout "BMS内网通讯超时";
CM_ SG_ 278 BMS_ISOWaring "绝缘报警";
CM_ SG_ 278 BMS_BCUHWFault "采集板硬件故障
具体故障信息由UDS事件帧报出";
CM_ SG_ 278 BMS_NegRelayFault "负极继电器故障";
CM_ SG_ 278 BMS_PosRelayFault "正极继电器故障";
CM_ SG_ 278 BMS_PreRelayFault "预充电继电器故障";
CM_ SG_ 278 BMS_LowVoltageMSD "低压MSD状态";
CM_ SG_ 278 BMS_CharPosRelayFault "快充正极继电器故障";
CM_ SG_ 278 BMS_CharNegRelayFault "快充负继电器故障";
CM_ SG_ 278 BMS_BMUFault "主控板故障
主板硬件故障
具体故障信息由UDS事件帧报出";
CM_ SG_ 278 BMS_VcuCANTimeout "整车通信超时";
CM_ SG_ 278 BMS_BattHVDisaccord "高压异常
电池采样与累加值不一致";
CM_ SG_ 278 BMS_SOClow "SOC低报警
GBT 32960.3 T18-4";
CM_ SG_ 278 BMS_Mismatch "动力蓄电池包不匹配报警
GBT 32960.3 T18-9";
CM_ SG_ 278 BMS_SOCOverHigh "SOC过高
GBT 32960.3 T18-7";
CM_ SG_ 278 BMS_BattOverCharge "电池过充
GBT 32960.3 T18-17";
CM_ SG_ 278 BMS_SOCSkip "SOC跳变
GBT 32960.3 T18-8";
CM_ SG_ 278 BMS_CGOverCurr "充电过流故障";
CM_ SG_ 278 BMS_LowVoltageFault "低压供电电源故障";
CM_ SG_ 278 BMS_LiquidLeak "电池漏液故障";
CM_ SG_ 278 BMS_CrashFault "电池碰撞故障";
CM_ SG_ 278 BMS_ThermRunAway "电池热失控故障";
CM_ SG_ 278 BMS_Maintenance "电池保养灯";
CM_ SG_ 278 BMS_BusbarTempOverWaring "汇流排过温";
CM_ SG_ 278 BMS_FuseFault "电池熔断器故障";
CM_ SG_ 278 BMS_CurrSensorFault "电流传感器故障
具体故障信息由UDS事件帧报出";
CM_ SG_ 278 BMS_0x116_RollingCounter "从0到15循环计数，如果通信中断，则重新从0开始计数。";
CM_ SG_ 276 BMS_thermalControlReq " 电池热管理控制请求";
CM_ SG_ 276 BMS_ThermalCtrlTargetTemp "电池包热管理目标温度";
CM_ SG_ 276 BMS_InputWaterTemp "电池进水口温度";
CM_ SG_ 276 BMS_OutputWaterTemp "电池出水口温度";
CM_ SG_ 276 BMS_BattThermalReqLvl "电池包热管理需求等级，暂时定义为15个等级";
CM_ SG_ 276 BMS_0x114_RollingCounter "从0到15循环计数，如果通信中断，则重新从0开始计数。";
CM_ SG_ 279 VCU_thermalControlReq " 电池热管理控制请求";
CM_ SG_ 279 VCU_InputWaterTemp "电池进水口温度";
CM_ SG_ 279 VCU_OutputWaterTemp "电池出水口温度";
CM_ SG_ 279 VCU_BattThermalReqLvl "电池包热管理需求等级，暂时定义为15个等级";
CM_ SG_ 279 VCU_RecoTiming "恢复充电倒计时";
CM_ SG_ 288 Checksum_0x120 "Checksum: IDMSB XOR IDLSB XOR Byte1 XOR Byte2 XOR Byte3 XOR Byte4 XOR Byte5 XOR Byte6 XOR Byte7";
CM_ SG_ 288 MCU_MotorActualTorque "电机实时输出扭矩";
CM_ SG_ 288 MCU_MotorSpeed "电机实时输出转速";
CM_ SG_ 288 MCU_AuthSts "MCU动力防盗认证结果";
CM_ SG_ 288 MCU_OverSpdWarning "电机超速报警";
CM_ SG_ 288 MCU_InverterTempWarning "电机控制器过温报警";
CM_ SG_ 288 MCU_MotorTempWarning "电机过温报警";
CM_ SG_ 288 MCU_OverTemp "MCU请求点亮电机过热灯";
CM_ SG_ 288 MCU_WorkSts "MCU实时工作状态";
CM_ SG_ 288 MCU_FaultLevel "故障等级";
CM_ SG_ 288 MCU_FaultLampOn "MCU请求点亮电机故障灯";
CM_ SG_ 288 MCU_HVLock "MCU高压互锁信号(后驱预留）";
CM_ SG_ 288 Rollingcounter_0x120 "从0到15循环计数，如果通信中断，则重新从0开始计数。";
CM_ SG_ 289 Checksum_0x121 "Checksum: IDMSB XOR IDLSB XOR Byte1 XOR Byte2 XOR Byte3 XOR Byte4 XOR Byte5 XOR Byte6XOR Byte7";
CM_ SG_ 289 ESP_VehicleSpeed "Current Vehicle Speed
当前实际车速";
CM_ SG_ 289 ESP_VehicleSpeed_Valid "Vehicle speed value valid
车速有效";
CM_ SG_ 289 ESP_OFF "ESP is diabled by pata（ESP off）";
CM_ SG_ 289 ESP_ABS_Error "ABS_Fault: ESP system has detected a failure which does not allow a reliable ABS regulation and is therefore switched off";
CM_ SG_ 289 ESP_ABS_Intervention "ABS control active - Indication that ESP system (especially ABS module) currently performs a brake intervention";
CM_ SG_ 289 ESP_VDC_TCS_Error "ESP_Fault: VDC/TCS is switched off due to detected failure";
CM_ SG_ 289 ESP_EBD_Error "EBD_Fault: ESP system has detected a heavy fault, which does not even allow a reliable electronic brake distribution and is therefore completely shut down";
CM_ SG_ 289 ESP_VDC_Intervention "VDC controller active: Oversteering brake intervention or Understeering brake intervention";
CM_ SG_ 289 ESP_TCS_Intervention "TCS controller active: Brake intervention or Engine torque reduction intervention";
CM_ SG_ 289 ESP_EBD_Intervention "EBD control active - Indication that ESP system (especially EBD module) currently performs a brake intervention";
CM_ SG_ 289 ESP_HDC_Status "Indicating the status of HDC.";
CM_ SG_ 289 ESP_HDC_Available "HMI Responsible,CAN get degrateHDC statement from DSW and send out";
CM_ SG_ 289 ESP_EPBFailstatus "EPB failure status";
CM_ SG_ 289 ESP_EPBStatus "Indicating the status of EPB";
CM_ SG_ 289 ESP_VehicleStop "Indicates if vehicle is in standstill (if more or equal to two wheels are standstill).
Set to a desired state when standstill is surely reached.
";
CM_ SG_ 289 ESP_VehicleStop_Valid "Check the validity of the signal of VehicleStop.";
CM_ SG_ 289 ESP_MasterCyPressureCmp "Master cylinder pressure
Offset included";
CM_ SG_ 289 ESP_MasterCyPressure_Valid "Indicating MasterCyPressure valid or not";
CM_ SG_ 289 ESP_WheelCyBrakeForce_Exist "No brake pressure applied; Generally it indicates wheel cylinder presure.";
CM_ SG_ 289 ESP_ESPLamp "基于ESP工作状态用于仪表ESP灯量灭控制";
CM_ SG_ 289 ESP_AVHstandbyStatus "Indicates AVH in standby mode or not";
CM_ SG_ 289 ESP_AVHActive "Indicates AVH in active or not ";
CM_ SG_ 289 ESP_AVH_availalbe "HMI Responsible,CAN get degrateAVH statement from DSW and send out";
CM_ SG_ 289 ESP_HHC_Available "HHC  is available or not";
CM_ SG_ 289 ESP_HHCActive "Indicates HHCH in active or not ";
CM_ SG_ 289 RollingCounter_0x121 "RollingCounter: used 4bit length signal and the arithmetic is increased from 0 to 15 by every message.";
CM_ SG_ 290 Checksum_0x122 "Checksum: IDMSB XOR IDLSB XOR Byte1 XOR Byte2 XOR Byte3 XOR Byte4 XOR Byte5 XOR Byte6 XOR Byte7";
CM_ SG_ 290 MCU_MaxAvailableTorque "电机可输出最大电动扭矩";
CM_ SG_ 290 MCU_MinAvailableTorque "电机可输出最大发电扭矩";
CM_ SG_ 290 MCU_DeratingTempCoolant "冷却水过温降功率";
CM_ SG_ 290 MCU_damping_En "扭矩补偿标志位";
CM_ SG_ 290 MCU_DeratingTrqMin "发电超限降功率";
CM_ SG_ 290 MCU_DeratingTrqMax "电动超限降功率";
CM_ SG_ 290 MCU_DeratingOvrUdc "过压降功率";
CM_ SG_ 290 MCU_DeratingUndrUdc "欠压降功率";
CM_ SG_ 290 MCU_DeratingOvrIdc "过流降功率";
CM_ SG_ 290 MCU_DeratingUndrIdc "欠流降功率";
CM_ SG_ 290 MCU_DeratingTempEm "电机过温降功率";
CM_ SG_ 290 MCU_DeratingTempInv "控制器过温降功率";
CM_ SG_ 290 Rollingcounter_0x122 "从0到15循环计数，如果通信中断，则重新从0开始计数。";
CM_ SG_ 290 MCU_MotorTorqueDeratingFlg "电机扭矩derating标志位";
CM_ SG_ 290 MCU_HVReady "高压端预充完成";
CM_ SG_ 290 MCU_DeratingOverSpd "电机超速降功率";
CM_ SG_ 291 MCU_IsCurrent "实际定子电流有效值";
CM_ SG_ 291 MCU_DC_linkVoltage "直流母线电压";
CM_ SG_ 291 MCU_DC_linkCurrent "直流母线电流";
CM_ SG_ 291 MCU_InverterTemp "电机控制器温度";
CM_ SG_ 291 MCU_MotorTemp "电机定子温度";
CM_ SG_ 291 MCU_WaterTemp "控制器冷却水温度";
CM_ SG_ 291 MCU_MotorCount "电机个数";
CM_ SG_ 291 MCU_MotorSeqNum "电机顺序号";
CM_ SG_ 292 MCU_DBCTempU "U相DBC温度";
CM_ SG_ 292 MCU_DBCTempV "V相DBC温度";
CM_ SG_ 292 MCU_DBCTempW "W相DBC温度";
CM_ SG_ 292 MCU_RotorTemp "电机转子温度";
CM_ SG_ 292 MCU_MotoroffsetSts "电机转子偏移角度状态";
CM_ SG_ 292 MCU_stGateDrv "逆变器状态";
CM_ SG_ 292 MCU_Motoroffset "电机转子偏移角度";
CM_ SG_ 293 Checksum_0x125 "Checksum: IDMSB XOR IDLSB XOR Byte1 XOR Byte2 XOR Byte3 XOR Byte4 XOR Byte5 XOR Byte6XOR Byte7";
CM_ SG_ 293 ESP_TorqueIncrease "Target increased engine torque (drag torque control)";
CM_ SG_ 293 ESP_TorqueIncreaseSt "Target increased engine torque active";
CM_ SG_ 293 ESP_TorqueReqFast "Target reduced engine torque (fast)";
CM_ SG_ 293 ESP_TorqueReqFastSt "Engine torque reduction active（Fast）";
CM_ SG_ 293 ESP_TorqueReqSlow "Target reduced engine torque (slow)";
CM_ SG_ 293 ESP_TorqueReqSlowSt "Engine torque reduction active（Slow）";
CM_ SG_ 293 RollingCounter_0x125 "RollingCounter: used 4bit length signal and the arithmetic is increased from 0 to 15 by every message.";
CM_ SG_ 293 ESP_GearHoldRequest "Keeping gear";
CM_ SG_ 293 ESC_Gear_Request "ESC_Gear_Request";
CM_ SG_ 320 Checksum_0x140 "Checksum: IDMSB XOR IDLSB XOR Byte1 XOR Byte2 XOR Byte3 XOR Byte4 XOR Byte5 XOR Byte6 XOR Byte7";
CM_ SG_ 320 VCU_CurrentMotorTorq "当前电机扭矩";
CM_ SG_ 320 VCU_MaxMotorTorque "电机最大电动扭矩";
CM_ SG_ 320 VCU_MinMotorTorque "电机最小电动扭矩";
CM_ SG_ 320 Rollingcounter_0x140 "从0到15循环计数，如果通信中断，则重新从0开始计数。";
CM_ SG_ 321 Checksum_0x141 "Checksum: IDMSB XOR IDLSB XOR Byte1 XOR Byte2 XOR Byte3 XOR Byte4 XOR Byte5 XOR Byte6 XOR Byte7";
CM_ SG_ 321 VCU_DriverDemandTorq "Motor torque requested by driver or cruise control, reduced by motor drag torque and torque consumption of auxiliary devices";
CM_ SG_ 321 VCU_QECACC "VCU响应VLC扭矩控制的状态";
CM_ SG_ 321 VCU_CreepSwitch "蠕行开关";
CM_ SG_ 321 VCU_GearShiftInProgress "Gear shifting Progress";
CM_ SG_ 321 VCU_ShiftInProgress_Status "Gear shift in progress status";
CM_ SG_ 321 VCU_AccelerationModePer "加速模式百分比，范围：0-100%
精度：1%";
CM_ SG_ 321 VCU_OverRide "Indicating the torque demanded by the driver is higher than the torque demanded by ACC.
指示驾驶员要求的扭矩高于ACC所要求的扭矩";
CM_ SG_ 321 VCU_DriveMode "整车驾驶模式";
CM_ SG_ 321 Rollingcounter_0x141 "从0到15循环计数，如果通信中断，则重新从0开始计数。";
CM_ SG_ 336 Checksum_0x150 "Checksum: IDMSB XOR IDLSB XOR Byte1 XOR Byte2 XOR Byte3 XOR Byte4 XOR Byte5 XOR Byte6 XOR Byte7";
CM_ SG_ 336 VCU_GearLeverPos "实际档位";
CM_ SG_ 336 VCU_TortoiseLamp "龟灯信号";
CM_ SG_ 336 VCU_Charge_Connect "充电枪连接";
CM_ SG_ 336 VCU_12VbatteryError "12V蓄电池故障";
CM_ SG_ 336 VCU_ReadySts "Ready信号";
CM_ SG_ 336 VCU_MotorPumpError "电机水泵故障";
CM_ SG_ 336 VCU_VacuumSysFaultLamp "真空系统故障灯";
CM_ SG_ 336 VCU_GearP_EnterWarning "P档无法进入提醒";
CM_ SG_ 336 VCU_VehicleSysFaultLamp "整车系统故障";
CM_ SG_ 336 VCU_BattPumpError "电池水泵故障";
CM_ SG_ 336 VCU_DriveableAlarm "可行驶状态报警信号";
CM_ SG_ 336 VCU_GearFlashReq "换挡提示";
CM_ SG_ 336 VCU_EnergyRecoveryPer "能量回收强度百分比";
CM_ SG_ 336 VCU_Mileage "续航里程";
CM_ SG_ 336 VCU_PowerConsumption "百公里电耗";
CM_ SG_ 336 VCU_MotorLoopCoolantLow "电机回路冷却液过低报警";
CM_ SG_ 336 VCU_BatLoopCoolantLow "电池回路冷却液过低报警";
CM_ SG_ 336 VCU_ChargeDepthSts "充电深度设置状态";
CM_ SG_ 336 VCU_CloolantHighAlarm "冷却液温度过高报警";
CM_ SG_ 336 VCU_TBOX_SlowChargeSt "交流充电反馈";
CM_ SG_ 336 Rollingcounter_0x150 "从0到15循环计数，如果通信中断，则重新从0开始计数。";
CM_ SG_ 337 Checksum_0x151 "Checksum: IDMSB XOR IDLSB XOR Byte1 XOR Byte2 XOR Byte3 XOR Byte4 XOR Byte5 XOR Byte6XOR Byte7";
CM_ SG_ 337 VCU_HVLock_ALL "VCU高压互锁信号(综合）";
CM_ SG_ 337 VCU_BrakeLampReq "点亮制动灯请求";
CM_ SG_ 337 VCU_Intelligent_Charge_Sts "智能充电状态";
CM_ SG_ 337 VCU_HVLock_self "VCU高压互锁信号（VCU检测）";
CM_ SG_ 337 VCU_MotorPump_ErrorSts "电机水泵故障状态";
CM_ SG_ 337 VCU_BrkSw_Sts "制动踏板开关状态
Brake pedal switch Status";
CM_ SG_ 337 VCU_BrkPed_Pos "制动踏板位置度信号";
CM_ SG_ 337 VCU_AccSW_Sts "油门踏板开关状态";
CM_ SG_ 337 VCU_AccPedPos "油门踏板位置度
Accelerator pedal position";
CM_ SG_ 337 VCU_TargetGear "VCUtarget gear";
CM_ SG_ 337 VCU_APS_WorkStatus "VCU反馈给APS的工作状态";
CM_ SG_ 337 Rolling_counter_0x151 "RollingCounter: used 4bit length signal and the arithmetic is increased from 0 to 15 by every message.";
CM_ SG_ 373 Checksum_0x175 "Checksum: IDMSB XOR IDLSB XOR Byte1 XOR Byte2 XOR Byte3 XOR Byte4 XOR Byte5 XOR Byte6XOR Byte7";
CM_ SG_ 373 SAS_SteerWheelAngle "The current angle of the steering wheel（Positive, to left; Negative, to right）
转向角度，左正右负";
CM_ SG_ 373 SAS_SteerWheelRotSpd "The current rotation speed of the steering wheel.
转向角速度";
CM_ SG_ 373 SAS_SteerWheelRotSpdStatus "The status of SteerWheelRotSpd
转向角速度有效性";
CM_ SG_ 373 SAS_SASStsSnsr "the flag of  SAS status
Punch:Steering angle status
SAS硬件故障状态";
CM_ SG_ 373 EPS_SteeringTorque "施加在方向盘上的驾驶员手力矩，左正右负
Driver steering torque，left+/right-";
CM_ SG_ 373 EPS_SteeringTorqueValid "Validation bit of torsion bar torque";
CM_ SG_ 373 SAS_SASStsCal "The calibration status of SAS
传感器标定状态";
CM_ SG_ 373 Rolling_counter_0x175 "RollingCounter: used 4bit length signal and the arithmetic is increased from 0 to 15 by every message.";
CM_ SG_ 392 Checksum_0x188 "Checksum: IDMSB XOR IDLSB XOR Byte1 XOR Byte2 XOR Byte3 XOR Byte4 XOR Byte5 XOR Byte6XOR Byte7";
CM_ SG_ 392 DCDC_ErrorLevel "DCDC故障等级";
CM_ SG_ 392 DCDC_stMode "stMode of DCDC
DCDC工作模式";
CM_ SG_ 392 DCDC_DischargeMode "DischargeMode of DCDC
DCDC主动泄放状态";
CM_ SG_ 392 DCDC_IdcLvCurr "Low side current of DCDC
DCDC低压输出电流";
CM_ SG_ 392 DCDC_IdcHvCurr "High side  current of DCDC
DCDC高压输入电流";
CM_ SG_ 392 DCDC_UdcLvVolt "Low side voltage of DCDC
DCDC低压输出电压";
CM_ SG_ 392 DCDC_UdcHvVolt "High side  voltage of DCDC
DCDC高压输入电压";
CM_ SG_ 528 Checksum_0x210 "Checksum: IDMSB XOR IDLSB XOR Byte1 XOR Byte2 XOR Byte3 XOR Byte4 XOR Byte5 XOR Byte6XOR Byte7";
CM_ SG_ 528 ACU_CrashStatus "ACU output crash status
";
CM_ SG_ 528 ACU_AirBagFailSts "Airbag fail Warning Lamp status
安全气囊故障报警灯";
CM_ SG_ 528 ACU_SBR_Driver "Drive Buckle stauts/ SBR status
主驾安全带未系提醒";
CM_ SG_ 528 ACU_SBR_Passenger "Passenger Buckle stauts/ SBR status
前排副驾驶安全带未系提醒";
CM_ SG_ 528 ACU_SBR_RLPassenger "RL Passenger Buckle stauts/ SBR status
后排左侧安全带未系提醒";
CM_ SG_ 528 ACU_SBR_MidPassenger "Mid Passenger Buckle stauts/ SBR status
后排中间安全带未系提醒";
CM_ SG_ 528 ACU_SBR_RRPassenger "RR Passenger Buckle stauts/ SBR status
后排右侧安全带未系提醒";
CM_ SG_ 528 ACU_DrvSeatBeltSWSts "Driver Buckle Switch status
主驾安全带未开关状态";
CM_ SG_ 528 ACU_PsSeatBeltSWSts "Passenger Buckle Switch status
前排副驾驶安全带开关状态";
CM_ SG_ 528 ACU_RLPsSeatBeltSWSts "RL Passenger Buckle Switch status
后排左侧安全带开关状态";
CM_ SG_ 528 ACU_MidPsSeatBeltSWSts "Mid Passenger  Buckle Switch status
后排中间安全带开关状态";
CM_ SG_ 528 ACU_RRPsSeatBeltSWSts "RR Passenger Buckle Switch status
后排右侧安全带开关状态";
CM_ SG_ 528 RollingCounter_0x210 "从0到15循环计数，如果通信中断，则重新从0开始计数。";
CM_ SG_ 529 Checksum_0x211 "Checksum: IDMSB XOR IDLSB XOR Byte1 XOR Byte2 XOR Byte3 XOR Byte4 XOR Byte5 XOR Byte6XOR Byte7";
CM_ SG_ 529 ABS_WheelSpeed_FL "Current wheel speed information of front left wheel.
左前轮轮速";
CM_ SG_ 529 ABS_WheelSpeed_FR "Current wheel speed information of front right wheel.
右前轮轮速";
CM_ SG_ 529 ABS_WheelSpeed_RL "Current wheel speed information of rear left wheel.
左后轮轮速";
CM_ SG_ 529 ABS_WheelSpeed_RR "Current wheel speed information of rear right wheel.
右后轮轮速";
CM_ SG_ 529 RollingCounter_0x211 "RollingCounter: used 4bit length signal and the arithmetic is increased from 0 to 15 by every message.";
CM_ SG_ 529 ABS_WheelSpeed_FL_Valid "Front left wheel speed valid
左前轮速有效";
CM_ SG_ 529 ABS_WheelSpeed_FR_Valid "Front right wheel speed valid
右前轮速有效";
CM_ SG_ 529 ABS_WheelSpeed_RL_Valid "Rear left wheel speed valid
左后轮速有效";
CM_ SG_ 529 ABS_WheelSpeed_RR_Valid "Rear right wheel speed valid
右后轮速有效";
CM_ SG_ 532 Checksum_0x214 "Checksum: IDMSB XOR IDLSB XOR Byte1 XOR Byte2 XOR Byte3 XOR Byte4 XOR Byte5 XOR Byte6XOR Byte7";
CM_ SG_ 532 ESP_WheelDirection_FL "Front left wheel Moving direction";
CM_ SG_ 532 ESP_WheelDirection_FL_Valid "Indicating front left wheel direction signal valid or not.";
CM_ SG_ 532 ESP_WheelDirection_FR "Front right wheel  Moving direction";
CM_ SG_ 532 ESP_WheelDirection_FR_Valid "Indicating front right wheel direction signal valid or not.";
CM_ SG_ 532 ESP_WheelDirection_RL "Rear left wheel  Moving direction";
CM_ SG_ 532 ESP_WheelDirection_RL_Valid "Indicating rear left wheel direction signal valid or not.";
CM_ SG_ 532 ESP_WheelDirection_RR "Rear right wheel Moving direction";
CM_ SG_ 532 ESP_WheelDirection_RR_Valid "Indicating rear right wheel direction signal valid or not.";
CM_ SG_ 532 ESP_CDD_Intervention "Indicates CDD is active or not";
CM_ SG_ 532 ESP_CDD_Available "Indicates CDD is available or not";
CM_ SG_ 532 ESP_CDD_Error "Indicate whether or not CDD is off and the function degrades due to errors.
Note: CDD error does not apply to ESP error.";
CM_ SG_ 532 ESP_CDDTempOff "Indicating brake temperature too high or not.";
CM_ SG_ 532 ESP_WheelBrakeForce "Estimated sum of vehicle brake force acting on each wheel.";
CM_ SG_ 532 ESP_VLC_EngTrqReq "VLC engine Torque Request";
CM_ SG_ 532 ESP_VLC_EngTrqReqActive "VLC engine Torque Request Active";
CM_ SG_ 532 RollingCounter_0x214 "RollingCounter: used 4bit length signal and the arithmetic is increased from 0 to 15 by every message.";
CM_ SG_ 532 ESP_VLC_Intervention "Indicates VLC is active or not
";
CM_ SG_ 532 ESP_VLC_Error "It means VLC is failed";
CM_ SG_ 532 ESP_VLC_Available "It means VLC is available";
CM_ SG_ 532 ESP_APA_CDD_active "ESC_APA_CDD_active";
CM_ SG_ 579 Checksum_0x243 "Checksum: IDMSB XOR IDLSB XOR Byte1 XOR Byte2 XOR Byte3 XOR Byte4 XOR Byte5 XOR Byte6XOR Byte7";
CM_ SG_ 579 ESP_YawRateValue "yaw rate signal
横摆角速度";
CM_ SG_ 579 ESP_YawrateValue_valid "yaw rate signal value valid or not.横摆角速度信号是否有效";
CM_ SG_ 579 ESP_BrakelightRequest "Indicate the request to light up brake light during emergent brake via EPB.
The request to illuminater brake light is needed by HHC,AVH,HDC,VLC,CDD also. This signal will be used not only for EPB emergency braking but also for all the above mentioned functions.
ESP请求点亮制动灯";
CM_ SG_ 579 ESP_Intervention "Indication that ESP system currently performs a intervention. Set also when TCS active.
ESP和TCS激活";
CM_ SG_ 579 ESP_LongAccSensor "vehicle longitudinal acceleration
车辆纵向加速度";
CM_ SG_ 579 ESP_LongAccSensorValid "vehicle longitudinal acceleration  value valid or not.
车辆纵向加速度信号是否有效";
CM_ SG_ 579 ESP_LaterAccSensor "vehicle lateral acceleration
车辆横向加速度";
CM_ SG_ 579 ESP_LaterAccSensorValid "vehicle lateral acceleration value valid or not.
车辆横向加速度信号是否有效";
CM_ SG_ 579 ESP_AEB_Intervention "Indicates AEB is active or not";
CM_ SG_ 579 ESC_APA_LC_Status "ESC_APA_LC_Status";
CM_ SG_ 579 RollingCounter_0x243 "RollingCounter: used 4bit length signal and the arithmetic is increased from 0 to 15 by every message.";
CM_ SG_ 642 Checksum_0x282 "Checksum: IDMSB XOR IDLSB XOR Byte1 XOR Byte2 XOR Byte3 XOR Byte4 XOR Byte5 XOR Byte6XOR Byte7";
CM_ SG_ 642 SCM_CC_Switch "
定速巡航开启/关闭开关信号（低配）";
CM_ SG_ 642 SCM_Res_Set_Switch "巡航Res+/Set-开关信号";
CM_ SG_ 642 SCM_PRND_req "PRND档位请求";
CM_ SG_ 642 Counter_0x282 "RollingCounter: used 4bit length signal and the arithmetic is increased from 0 to 15 by every message.";
CM_ SG_ 734 HU_VCU_RemoteChrgLock "大屏解锁电子锁";
CM_ SG_ 734 HU_ChargeDepthSet "充电深度设置";
CM_ SG_ 734 HU_EnergyRecoveryPer "能量回收强度百分比";
CM_ SG_ 734 HU_SpeedLimitSW "车速限制开关，默认关";
CM_ SG_ 734 HU_LimitSpeedSet "开启功能时：
设置范围：0~200KM/H
设置的间隔：1km/h";
CM_ SG_ 734 HU_DriveMode "驾驶模式";
CM_ SG_ 734 HU_AccelerationModePer "加速模式百分比,范围：0-100%
精度：1%
";
CM_ SG_ 734 HU_CreepSwitch "蠕行开关";
CM_ SG_ 734 HU_SubMileage_Reset "小计里程重置";
CM_ SG_ 734 HU_DMS_SW "疲劳驾驶提醒开关";
CM_ SG_ 774 BMS_RemainChargingTime "剩余充电时间";
CM_ SG_ 774 BMS_Charing_Time "本次充电时长";
CM_ SG_ 774 BMS_Charging_Ah "本次充入容量";
CM_ SG_ 774 BMS_TotalCharging_Ah "累计充电容量";
CM_ SG_ 774 BMS_Charging_Energy "本次充入能量";
CM_ SG_ 784 BCM_SystemPowerMode "整车电源状态
vehicle Power Status";
CM_ SG_ 784 BCM_AntiThelf_Sts "车辆设防状态";
CM_ SG_ 784 BCM_DriverLock_Sts "驾驶侧门锁状态";
CM_ SG_ 784 BCM_StartRequest "strart请求信号";
CM_ SG_ 784 BCM_Hood_Sts "前舱盖状态";
CM_ SG_ 784 BCM_FL_Door_Sts "左前门开关状态";
CM_ SG_ 784 BCM_FR_Door_Sts "右前门开关状态";
CM_ SG_ 784 BCM_RL_Door_Sts "左后门开关状态";
CM_ SG_ 784 BCM_RR_Door_Sts "右后门开关状态";
CM_ SG_ 804 MCU_FailCode1 "故障码1";
CM_ SG_ 804 MCU_FailCode2 "故障码2";
CM_ SG_ 804 MCU_FailCode3 "故障码3";
CM_ SG_ 804 MCU_FailCode4 "故障码4";
CM_ SG_ 805 WPTC_RunSts "WPTC运行状态";
CM_ SG_ 805 WPTC_HVSts "WPTC高压供电状态";
CM_ SG_ 805 WPTC_Power "WPTC实际工作功率";
CM_ SG_ 805 WPTC_OutletTemp "WPTC出口水温";
CM_ SG_ 805 WPTC_InputTemp "WPTC进口水温";
CM_ SG_ 805 WPTC_CUR "WPTC当前运行电流";
CM_ SG_ 805 WPTC_COM_VCU_Lost "WPTC与VCU通讯丢失故障";
CM_ SG_ 805 WPTC_CUR_Over "WPTC过流故障";
CM_ SG_ 805 WPTC_Temp_PCB_High "WPTC的PCB板过温故障";
CM_ SG_ 805 WPTC_OutletTemp_High "WPTC出水口过温故障";
CM_ SG_ 805 WPTC_InputTemp_High "WPTC进水口过温故障";
CM_ SG_ 805 WPTC_PowerMaxLim "WPTC最大允许功率";
CM_ SG_ 853 TBOX_TimeSyncSts "TBOX发送的仪表时间同步有效位";
CM_ SG_ 853 TBOX_TimeSyncData_Year "TBOX发送的同步时间数据----年
0x0-0x63: Year
0x64-0x7F: Invalid
";
CM_ SG_ 853 TBOX_TimeSyncData_Month "TBOX发送的同步时间数据----月
0x0: Invalid
0x1-0xC: Month";
CM_ SG_ 853 TBOX_TimeSyncData_Day "TBOX发送的同步时间数据----日
0x0: Invalid
0x01-0x1F: Day";
CM_ SG_ 853 TBOX_TimeSyncData_Hour "ACM发送的同步时间数据----时
0x0-0x17: Hour
0x18-0x1F: Invalid";
CM_ SG_ 853 TBOX_TimeSyncData_Minute "TBOX发送的同步时间数据----分
0x0-0x3B: Minute
0x3C-0x3F: Invalid
";
CM_ SG_ 853 TBOX_TimeSyncData_Second "TBOX发送的同步时间数据----秒
0x00-0x3B: Second
0x3C-0x3F: Invalid
";
CM_ SG_ 905 Checksum_0x389 "Checksum: IDMSB XOR IDLSB XOR Byte1 XOR Byte2 XOR Byte3 XOR Byte4 XOR Byte5 XOR Byte6XOR Byte7";
CM_ SG_ 905 DCDC_DeratingSts "DCDC derating status
DCDC降额状态";
CM_ SG_ 905 DCDC_rUtilRateDFM "utilization of DCDC, corresponds to I_act / I_max
实际电流与最大电流的比值";
CM_ SG_ 905 DCDC_TempAct "actual temperature of DCDC(for VCU pump control)
DCDC实际温度（VCU水泵控制）";
CM_ SG_ 905 Counter_0x389 "Message rolling counter.";
CM_ SG_ 928 ICM_ODOTotal "ODO 总里程 ";
CM_ SG_ 928 ICM_DisPlayVehicleSpeed "Current Display Vehicle Speed
仪表当前显示车速";
CM_ SG_ 928 ICM_Error_Sts "ICM故障状态";
CM_ SG_ 928 ICM_SubMileage_Reset "小计里程重置";
CM_ SG_ 1027 VCU_NM_DA "目标地址";
CM_ SG_ 1027 VCU_NM_ALIVE "Alive报文";
CM_ SG_ 1027 VCU_NM_RING "Ring报文";
CM_ SG_ 1027 VCU_NM_LIMPHOME "Limphome报文";
CM_ SG_ 1027 VCU_NM_SLEEP_Ind "睡眠标志位";
CM_ SG_ 1027 VCU_NM_SLEEP_ACK "睡眠确认位";
CM_ SG_ 1032 GW_PT_NM_DA "目标地址";
CM_ SG_ 1032 GW_PT_NM_ALIVE "Alive报文";
CM_ SG_ 1032 GW_PT_NM_RING "Ring报文";
CM_ SG_ 1032 GW_PT_NM_LIMPHOME "Limphome报文";
CM_ SG_ 1032 GW_PT_NM_SLEEP_Ind "睡眠标志位";
CM_ SG_ 1032 GW_PT_NM_SLEEP_ACK "睡眠确认位";
CM_ SG_ 1299 BMS_MaxTempNo "电池最高温度编号";
CM_ SG_ 1299 BMS_MaxTemp "电池最高温度";
CM_ SG_ 1299 BMS_MinTempNo "电池最低温度编号";
CM_ SG_ 1299 BMS_MinTemp "电池最低温度";
CM_ SG_ 1299 BMS_BattTempDev "电池温度差";
CM_ SG_ 1299 BMS_CCTemp1 "快充接口1温度";
CM_ SG_ 1299 BMS_CCTemp2 "快充接口2温度";
CM_ SG_ 1299 BMS_0x513_RollingCounter "从0到15循环计数，如果通信中断，则重新从0开始计数。";
CM_ SG_ 1300 BMS_ModuleBusbarMaxTempNo "模组busbar最高温度编号";
CM_ SG_ 1300 BMS_ModuleBusbarMaxTemp "模组busbar最高温度";
CM_ SG_ 1300 BMS_ModuleBusbarMinTempNo "模组busbar最低温度编号";
CM_ SG_ 1300 BMS_ModuleBusbarMinTemp "模组busbar最低温度";
CM_ SG_ 1300 BMS_0x514_RollingCounter "从0到15循环计数，如果通信中断，则重新从0开始计数。";
CM_ SG_ 1324 VCU_accelerator1 "油门信号电压1";
CM_ SG_ 1324 VCU_accelerator2 "油门信号电压2";
CM_ SG_ 1324 VCU_brakesensor1 "制动角度传感器电压1";
CM_ SG_ 1324 VCU_brakesensor2 "制动角度传感器电压2";
CM_ SG_ 1324 VCU_vacuumpumpsensor "真空泵压力传感器电压";
CM_ SG_ 1324 VCU_AtmosphePressure "大气压力传感器电压";
CM_ SG_ 1324 VCU_KL87inputVol "KL87输入电压";
CM_ SG_ 1328 BMS_BattCellNum1Vol "1号单体电压值";
CM_ SG_ 1328 BMS_BattCellNum2Vol "2号单体电压值";
CM_ SG_ 1328 BMS_BattCellNum3Vol "3号单体电压值";
CM_ SG_ 1328 BMS_BattCellNum4Vol "4号单体电压值";
CM_ SG_ 1329 BMS_BattCellNum5Vol "5号单体电压值";
CM_ SG_ 1329 BMS_BattCellNum6Vol "6号单体电压值";
CM_ SG_ 1329 BMS_BattCellNum7Vol "7号单体电压值";
CM_ SG_ 1329 BMS_BattCellNum8Vol "8号单体电压值";
CM_ SG_ 1330 BMS_BattCellNum9Vol "9号单体电压值";
CM_ SG_ 1330 BMS_BattCellNum10Vol "10号单体电压值";
CM_ SG_ 1330 BMS_BattCellNum11Vol "11号单体电压值";
CM_ SG_ 1330 BMS_BattCellNum12Vol "12号单体电压值";
CM_ SG_ 1331 BMS_BattCellNum13Vol "13号单体电压值";
CM_ SG_ 1331 BMS_BattCellNum14Vol "14号单体电压值";
CM_ SG_ 1331 BMS_BattCellNum15Vol "15号单体电压值";
CM_ SG_ 1331 BMS_BattCellNum16Vol "16号单体电压值";
CM_ SG_ 1332 BMS_BattCellNum17Vol "17号单体电压值";
CM_ SG_ 1332 BMS_BattCellNum18Vol "18号单体电压值";
CM_ SG_ 1332 BMS_BattCellNum19Vol "19号单体电压值";
CM_ SG_ 1332 BMS_BattCellNum20Vol "20号单体电压值";
CM_ SG_ 1333 BMS_BattCellNum21Vol "21号单体电压值";
CM_ SG_ 1333 BMS_BattCellNum22Vol "22号单体电压值";
CM_ SG_ 1333 BMS_BattCellNum23Vol "23号单体电压值";
CM_ SG_ 1333 BMS_BattCellNum24Vol "24号单体电压值";
CM_ SG_ 1334 BMS_BattCellNum25Vol "25号单体电压值";
CM_ SG_ 1334 BMS_BattCellNum26Vol "26号单体电压值";
CM_ SG_ 1334 BMS_BattCellNum27Vol "27号单体电压值";
CM_ SG_ 1334 BMS_BattCellNum28Vol "28号单体电压值";
CM_ SG_ 1335 BMS_BattCellNum29Vol "29号单体电压值";
CM_ SG_ 1335 BMS_BattCellNum30Vol "30号单体电压值";
CM_ SG_ 1335 BMS_BattCellNum31Vol "31号单体电压值";
CM_ SG_ 1335 BMS_BattCellNum32Vol "32号单体电压值";
CM_ SG_ 1336 BMS_BattCellNum33Vol "33号单体电压值";
CM_ SG_ 1336 BMS_BattCellNum34Vol "34号单体电压值";
CM_ SG_ 1336 BMS_BattCellNum35Vol "35号单体电压值";
CM_ SG_ 1336 BMS_BattCellNum36Vol "36号单体电压值";
CM_ SG_ 1337 BMS_BattCellNum37Vol "37号单体电压值";
CM_ SG_ 1337 BMS_BattCellNum38Vol "38号单体电压值";
CM_ SG_ 1337 BMS_BattCellNum39Vol "39号单体电压值";
CM_ SG_ 1337 BMS_BattCellNum40Vol "40号单体电压值";
CM_ SG_ 1338 BMS_BattCellNum41Vol "41号单体电压值";
CM_ SG_ 1338 BMS_BattCellNum42Vol "42号单体电压值";
CM_ SG_ 1338 BMS_BattCellNum43Vol "43号单体电压值";
CM_ SG_ 1338 BMS_BattCellNum44Vol "44号单体电压值";
CM_ SG_ 1339 BMS_BattCellNum45Vol "45号单体电压值";
CM_ SG_ 1339 BMS_BattCellNum46Vol "46号单体电压值";
CM_ SG_ 1339 BMS_BattCellNum47Vol "47号单体电压值";
CM_ SG_ 1339 BMS_BattCellNum48Vol "48号单体电压值";
CM_ SG_ 1340 BMS_BattCellNum49Vol "49号单体电压值";
CM_ SG_ 1340 BMS_BattCellNum50Vol "50号单体电压值";
CM_ SG_ 1340 BMS_BattCellNum51Vol "51号单体电压值";
CM_ SG_ 1340 BMS_BattCellNum52Vol "52号单体电压值";
CM_ SG_ 1341 BMS_BattCellNum53Vol "53号单体电压值";
CM_ SG_ 1341 BMS_BattCellNum54Vol "54号单体电压值";
CM_ SG_ 1341 BMS_BattCellNum55Vol "55号单体电压值";
CM_ SG_ 1341 BMS_BattCellNum56Vol "56号单体电压值";
CM_ SG_ 1342 BMS_BattCellNum57Vol "57号单体电压值";
CM_ SG_ 1342 BMS_BattCellNum58Vol "58号单体电压值";
CM_ SG_ 1342 BMS_BattCellNum59Vol "59号单体电压值";
CM_ SG_ 1342 BMS_BattCellNum60Vol "60号单体电压值";
CM_ SG_ 1343 BMS_BattCellNum61Vol "61号单体电压值";
CM_ SG_ 1343 BMS_BattCellNum62Vol "62号单体电压值";
CM_ SG_ 1343 BMS_BattCellNum63Vol "63号单体电压值";
CM_ SG_ 1343 BMS_BattCellNum64Vol "64号单体电压值";
CM_ SG_ 1344 BMS_BattCellNum65Vol "65号单体电压值";
CM_ SG_ 1344 BMS_BattCellNum66Vol "66号单体电压值";
CM_ SG_ 1344 BMS_BattCellNum67Vol "67号单体电压值";
CM_ SG_ 1344 BMS_BattCellNum68Vol "68号单体电压值";
CM_ SG_ 1345 BMS_BattCellNum69Vol "69号单体电压值";
CM_ SG_ 1345 BMS_BattCellNum70Vol "70号单体电压值";
CM_ SG_ 1345 BMS_BattCellNum71Vol "71号单体电压值";
CM_ SG_ 1345 BMS_BattCellNum72Vol "72号单体电压值";
CM_ SG_ 1346 BMS_BattCellNum73Vol "73号单体电压值";
CM_ SG_ 1346 BMS_BattCellNum74Vol "74号单体电压值";
CM_ SG_ 1346 BMS_BattCellNum75Vol "75号单体电压值";
CM_ SG_ 1346 BMS_BattCellNum76Vol "76号单体电压值";
CM_ SG_ 1347 BMS_BattCellNum77Vol "77号单体电压值";
CM_ SG_ 1347 BMS_BattCellNum78Vol "78号单体电压值";
CM_ SG_ 1347 BMS_BattCellNum79Vol "79号单体电压值";
CM_ SG_ 1347 BMS_BattCellNum80Vol "80号单体电压值";
CM_ SG_ 1348 BMS_BattCellNum81Vol "81号单体电压值";
CM_ SG_ 1348 BMS_BattCellNum82Vol "82号单体电压值";
CM_ SG_ 1348 BMS_BattCellNum83Vol "83号单体电压值";
CM_ SG_ 1348 BMS_BattCellNum84Vol "84号单体电压值";
CM_ SG_ 1349 BMS_BattCellNum85Vol "85号单体电压值";
CM_ SG_ 1349 BMS_BattCellNum86Vol "86号单体电压值";
CM_ SG_ 1349 BMS_BattCellNum87Vol "87号单体电压值";
CM_ SG_ 1349 BMS_BattCellNum88Vol "88号单体电压值";
CM_ SG_ 1350 BMS_BattCellNum89Vol "89号单体电压值";
CM_ SG_ 1350 BMS_BattCellNum90Vol "90号单体电压值";
CM_ SG_ 1350 BMS_BattCellNum91Vol "91号单体电压值";
CM_ SG_ 1350 BMS_BattCellNum92Vol "92号单体电压值";
CM_ SG_ 1351 BMS_BattCellNum93Vol "93号单体电压值";
CM_ SG_ 1351 BMS_BattCellNum94Vol "94号单体电压值";
CM_ SG_ 1351 BMS_BattCellNum95Vol "95号单体电压值";
CM_ SG_ 1351 BMS_BattCellNum96Vol "96号单体电压值";
CM_ SG_ 1352 BMS_BattCellNum97Vol "97号单体电压值";
CM_ SG_ 1352 BMS_BattCellNum98Vol "98号单体电压值";
CM_ SG_ 1352 BMS_BattCellNum99Vol "99号单体电压值";
CM_ SG_ 1352 BMS_BattCellNum100Vol "100号单体电压值";
CM_ SG_ 1353 BMS_BattCellNum101Vol "101号单体电压值";
CM_ SG_ 1353 BMS_BattCellNum102Vol "102号单体电压值";
CM_ SG_ 1353 BMS_BattCellNum103Vol "103号单体电压值";
CM_ SG_ 1353 BMS_BattCellNum104Vol "104号单体电压值";
CM_ SG_ 1354 BMS_BattCellNum105Vol "105号单体电压值";
CM_ SG_ 1354 BMS_BattCellNum106Vol "106号单体电压值";
CM_ SG_ 1354 BMS_BattCellNum107Vol "107号单体电压值";
CM_ SG_ 1354 BMS_BattCellNum108Vol "108号单体电压值";
CM_ SG_ 1360 Checksum_0x550 "Checksum: IDMSB XOR IDLSB XOR Byte1 XOR Byte2 XOR Byte3 XOR Byte4 XOR Byte5 XOR Byte6XOR Byte7";
CM_ SG_ 1360 OBC_ChrgOutputVolt "OBC output votage reported
OBC输出电压";
CM_ SG_ 1360 OBC_ChrgFailLevel "OBC fault class
OBC故障等级";
CM_ SG_ 1360 OBC_CCLineSts "CC signal connect status
CC信号连接状态";
CM_ SG_ 1360 OBC_DeratingSts "OBC derating status
OBC降额状态
";
CM_ SG_ 1360 OBC_ChrgSts "OBC state machine mode
OBC 状态机";
CM_ SG_ 1360 OBC_ChrgEffciency "OBC real-time efficiency
OBC真实效率";
CM_ SG_ 1360 OBC_ChrgOutputCurr "OBC output current reported
OBC输出电流";
CM_ SG_ 1360 OBC_OBCStsCPLine "CP signal connect status
CP信号连接状态";
CM_ SG_ 1360 Rolling_counter_0x550 "RollingCounter: used 4bit length signal and the arithmetic is increased from 0 to 15 by every message.";
CM_ SG_ 1360 OBC_S2Sts "S2 switch status
S2开关状态";
CM_ SG_ 1360 OBC_ChrgAllowedSts "OBC允许充电";
CM_ SG_ 1377 VCU_MotorcoV "电机冷却液位电压差";
CM_ SG_ 1377 VCU_BattcolV "电池冷却液位电压差";
CM_ SG_ 1377 VCU_MotorLoopInputTemp "电机回路入口水温";
CM_ SG_ 1377 VCU_MotorLoopOutputTemp "电机回路出口水温";
CM_ SG_ 1377 VCU_IG1input "ON硬线输入";
CM_ SG_ 1377 VCU_startinput "Start硬线输入";
CM_ SG_ 1377 VCU_OBCwakeupVCU "OBC硬线唤醒VCU";
CM_ SG_ 1377 VCU_VCUwakeupOBC "VCU硬线唤醒OBC";
CM_ SG_ 1377 VCU_VCUwakeupBMS "VCU硬线唤醒BMS";
CM_ SG_ 1377 VCU_VCUwakeupMCU "VCU硬线唤醒MCU";
CM_ SG_ 1377 VCU_VacuumPumpRelay "真空泵继电器控制";
CM_ SG_ 1377 VCU_WPTCRelay "WPTC继电器控制";
CM_ SG_ 1377 VCU_MotorPumpPWM "电机水泵输出占空比";
CM_ SG_ 1377 VCU_BattPumpPWM "电池水泵输出占空比";
CM_ SG_ 1378 MCU_MotorSts_GBT "驱动电机工作状态_GBT32960";
CM_ SG_ 1378 MCU_MotoroffsetCalReq "电机角度自学习请求";
CM_ SG_ 1424 BMS_BattSerialNumber "序列号
GBT 34014-4.3.7";
CM_ SG_ 1424 BMS_BattManuYear "电池生产年
GBT 34014-4.3.6";
CM_ SG_ 1424 BMS_BattManuMonth "电池生产月
GBT 34014-4.3.6";
CM_ SG_ 1424 BMS_BattManuDay "电池生产日
GBT 34014-4.3.6";
CM_ SG_ 1425 BMS_BattSupplierCode "电池厂商代码
GBT 34014 附录A.1 ASCII码解析";
CM_ SG_ 1425 BMS_ProductTypeCode "产品类型代码
,GBT 34014 附录A.1ASCII码解析";
CM_ SG_ 1425 BMS_BattTypeCode "电池类型代码
GBT 34014 附录A.1ASCII码解析";
CM_ SG_ 1425 BMS_BattSpecCode "电池规格代码
GBT 34014 附录A.1ASCII码解析";
CM_ SG_ 1426 BMS_BattRetrospectCode "电池追溯码
GBT 34014-4.3.5";
CM_ SG_ 1427 BMS_BattProductionDate "电池生产日期";
CM_ SG_ 1427 BMS_BattS_Num "电池序列号";
CM_ SG_ 1427 BMS_BattRecycleCode "电池梯级利用代码";
CM_ SG_ 1428 BMS_BattCodeLenth "可充电储能系统编码长度
GBT 32960.3 T-6";
CM_ SG_ 1428 BMS_Temp_ProbeNum "动力蓄电池温度探针总数
GBT 32960.3 T-B.8";
CM_ SG_ 1428 BMS_PackageTotalNum "电池包总数
GBT 32960.3 T-B.6";
CM_ SG_ 1428 BMS_CellTotalNum "单体蓄电池总数
GBT 32960.3 T-B.6";
CM_ SG_ 1504 BMS_SWVersion_Supplier "BMS软件供应商代码（有电咖定义，如A/B/C分别代表A点/B点/C点供应商）";
CM_ SG_ 1504 BMS_SWVersion_Main "BMS软件版本-大版本（A/B/C代表A样/B样/C样件）";
CM_ SG_ 1504 BMS_SWVersion_Sub1 "BMS软件版本-小版本第一位";
CM_ SG_ 1504 BMS_SWVersion_Sub2 "BMS软件版本-小版本第二位";
CM_ SG_ 1504 BMS_HWVersion_Supplier "BMS硬件供应商代码（有电咖定义，如A/B/C分别代表A点/B点/C点供应商）";
CM_ SG_ 1504 BMS_HWVersion_Main "BMS硬件版本-大版本（A/B/C代表A样/B样/C样件）";
CM_ SG_ 1504 BMS_HWVersion_Sub1 "BMS硬件版本-小版本第一位";
CM_ SG_ 1504 BMS_HWVersion_Sub2 "BMS硬件版本-小版本第二位";
CM_ SG_ 1504 BMS_PackEnergy "电池包可用能量";
CM_ SG_ 1504 BMS_CellSupplier "电池包电芯供应商
见信号值描述";
CM_ SG_ 1505 VCU_SWVersion_Supplier "VCU软件供应商代码（有电咖定义，如A/B/C分别代表A点/B点/C点供应商）";
CM_ SG_ 1505 VCU_SWVersion_Main "VCU软件版本-大版本";
CM_ SG_ 1505 VCU_SWVersion_Sub1 "VCU软件版本-小版本第一位";
CM_ SG_ 1505 VCU_SWVersion_Sub2 "VCU软件版本-小版本第二位";
CM_ SG_ 1505 VCU_HWVersion_Supplier "VCU硬件供应商代码（有电咖定义，如A/B/C分别代表A点/B点/C点供应商）";
CM_ SG_ 1505 VCU_HWVersion_Main "VCU硬件版本-大版本";
CM_ SG_ 1505 VCU_HWVersion_Sub1 "VCU硬件版本-小版本第一位";
CM_ SG_ 1505 VCU_HWVersion_Sub2 "VCU硬件版本-小版本第二位";
CM_ SG_ 1505 VCU_SoftMainVersion_in "VCU软件主版本号（内部使用）";
CM_ SG_ 1505 VCU_SoftSubVersion_in "VCU软件子版本号（内部使用）";
CM_ SG_ 1505 VCU_SoftPhase_in "VCU软件阶段（内部使用）";
CM_ SG_ 1505 VCU_SoftPhaseDescription_in "VCU软件阶段说明（内部使用）";
CM_ SG_ 1506 MCU_SWVersion_Supplier "MCU软件供应商代码（有电咖定义，如A/B/C分别代A点/B点/C点供应商）";
CM_ SG_ 1506 MCU_SWVersion_Main "MCU软件版本-大版本";
CM_ SG_ 1506 MCU_SWVersion_Sub1 "MCU软件版本-小版本第一位";
CM_ SG_ 1506 MCU_SWVersion_Sub2 "MCU软件版本-小版本第二位";
CM_ SG_ 1506 MCU_HWVersion_Supplier "MCU硬件供应商代码（有电咖定义，如A/B/C分别代表A点/B点/C点供应商）";
CM_ SG_ 1506 MCU_HWVersion_Main "MCU硬件版本-大版本";
CM_ SG_ 1506 MCU_HWVersion_Sub1 "MCU硬件版本-小版本第一位";
CM_ SG_ 1506 MCU_HWVersion_Sub2 "MCU硬件版本-小版本第二位";
CM_ SG_ 1507 DCDC_SWVersion_Supplier "DCDC软件供应商代码（有电咖定义，如A/B/C分别代表A点/B点/C点供应商，定义参考诊断规范版本号定义）";
CM_ SG_ 1507 DCDC_SWVersion_Main "DCDC软件版本-大版本";
CM_ SG_ 1507 DCDC_SWVersion_Sub1 "DCDC软件版本-小版本第一位";
CM_ SG_ 1507 DCDC_SWVersion_Sub2 "DCDC软件版本-小版本第二位";
CM_ SG_ 1507 DCDC_HWVersion_Supplier "DCDC硬件件供应商代码";
CM_ SG_ 1507 DCDC_HWVersion_Main "DCDC硬件版本-大版本";
CM_ SG_ 1507 DCDC_HWVersion_Sub1 "DCDC硬件版本-小版本第一位";
CM_ SG_ 1507 DCDC_HWVersion_Sub2 "DCDC硬件版本-小版本第二位";
CM_ SG_ 1508 OBC_SWVersion_Supplier "OBC软件供应商代码（有电咖定义，如A/B/C分别代表A点/B点/C点供应商）";
CM_ SG_ 1508 OBC_SWVersion_Main "OBC软件版本-大版本";
CM_ SG_ 1508 OBC_SWVersion_Sub1 "OBC软件版本-小版本第一位";
CM_ SG_ 1508 OBC_SWVersion_Sub2 "OBC软件版本-小版本第二位";
CM_ SG_ 1508 OBC_HWVersion_Supplier "OBC硬件供应商代码（有电咖定义，如A/B/C分别代表A点/B点/C点供应商）";
CM_ SG_ 1508 OBC_HWVersion_Main "OBC硬件版本-大版本";
CM_ SG_ 1508 OBC_HWVersion_Sub1 "OBC硬件版本-小版本第一位";
CM_ SG_ 1508 OBC_HWVersion_Sub2 "OBC硬件版本-小版本第二位";
CM_ SG_ 1510 ACU_SWVersion_Supplier "ACU软件供应商代码（有电咖定义，如A/B/C分别代表A点/B点/C点供应商，定义参考诊断规范版本号定义）";
CM_ SG_ 1510 ACU_SWVersion_Main "ACU软件版本-大版本";
CM_ SG_ 1510 ACU_SWVersion_Sub1 "ACU软件版本-小版本第一位";
CM_ SG_ 1510 ACU_SWVersion_Sub2 "ACU软件版本-小版本第二位";
CM_ SG_ 1510 ACU_HWVersion_Supplier "ACU硬件件供应商代码";
CM_ SG_ 1510 ACU_HWVersion_Main "ACU硬件版本-大版本";
CM_ SG_ 1510 ACU_HWVersion_Sub1 "ACU硬件版本-小版本第一位";
CM_ SG_ 1510 ACU_HWVersion_Sub2 "ACU硬件版本-小版本第二位";
CM_ SG_ 1511 WPTC_SWVersion_Supplier "WPTC软件供应商代码（有电咖定义，如A/B/C分别代表A点/B点/C点供应商，定义参考诊断规范版本号定义）";
CM_ SG_ 1511 WPTC_SWVersion_Main "WPTC软件版本-大版本";
CM_ SG_ 1511 WPTC_SWVersion_Sub1 "WPTC软件版本-小版本第一位";
CM_ SG_ 1511 WPTC_SWVersion_Sub2 "WPTC软件版本-小版本第二位";
CM_ SG_ 1511 WPTC_HWVersion_Supplier "WPTC硬件件供应商代码";
CM_ SG_ 1511 WPTC_HWVersion_Main "WPTC硬件版本-大版本";
CM_ SG_ 1511 WPTC_HWVersion_Sub1 "WPTC硬件版本-小版本第一位";
CM_ SG_ 1511 WPTC_HWVersion_Sub2 "WPTC硬件版本-小版本第二位";
CM_ SG_ 1473 GW_SWVersion_Supplier "GW软件供应商代码（有电咖定义，如A/B/C分别代表A点/B点/C点供应商，定义参考诊断规范版本号定义）";
CM_ SG_ 1473 GW_SWVersion_Main "GW软件版本-大版本";
CM_ SG_ 1473 GW_SWVersion_Sub1 "GW软件版本-小版本第一位";
CM_ SG_ 1473 GW_SWVersion_Sub2 "GW软件版本-小版本第二位";
CM_ SG_ 1473 GW_HWVersion_Supplier "GW硬件件供应商代码";
CM_ SG_ 1473 GW_HWVersion_Main "GW硬件版本-大版本";
CM_ SG_ 1473 GW_HWVersion_Sub1 "GW硬件版本-小版本第一位";
CM_ SG_ 1473 GW_HWVersion_Sub2 "GW硬件版本-小版本第二位";
CM_ SG_ 1520 BMS_BattTempSensorNum1 "1号温度探针温度值";
CM_ SG_ 1520 BMS_BattTempSensorNum2 "2号温度探针温度值";
CM_ SG_ 1520 BMS_BattTempSensorNum3 "3号温度探针温度值";
CM_ SG_ 1520 BMS_BattTempSensorNum4 "4号温度探针温度值";
CM_ SG_ 1520 BMS_BattTempSensorNum5 "5号温度探针温度值";
CM_ SG_ 1520 BMS_BattTempSensorNum6 "6号温度探针温度值";
CM_ SG_ 1520 BMS_BattTempSensorNum7 "7号温度探针温度值";
CM_ SG_ 1520 BMS_BattTempSensorNum8 "8号温度探针温度值";
CM_ SG_ 1521 BMS_BattTempSensorNum9 "9号温度探针温度值";
CM_ SG_ 1521 BMS_BattTempSensorNum10 "10号温度探针温度值";
CM_ SG_ 1521 BMS_BattTempSensorNum11 "11号温度探针温度值";
CM_ SG_ 1521 BMS_BattTempSensorNum12 "12号温度探针温度值";
CM_ SG_ 1521 BMS_BattTempSensorNum13 "13号温度探针温度值";
CM_ SG_ 1521 BMS_BattTempSensorNum14 "14号温度探针温度值";
CM_ SG_ 1521 BMS_BattTempSensorNum15 "15号温度探针温度值";
CM_ SG_ 1521 BMS_BattTempSensorNum16 "16号温度探针温度值";
CM_ SG_ 1522 BMS_BattTempSensorNum17 "17号温度探针温度值";
CM_ SG_ 1522 BMS_BattTempSensorNum18 "18号温度探针温度值";
CM_ SG_ 1522 BMS_BattTempSensorNum19 "19号温度探针温度值";
CM_ SG_ 1522 BMS_BattTempSensorNum20 "20号温度探针温度值";
CM_ SG_ 1522 BMS_BattTempSensorNum21 "21号温度探针温度值";
CM_ SG_ 1522 BMS_BattTempSensorNum22 "22号温度探针温度值";
CM_ SG_ 1522 BMS_BattTempSensorNum23 "23号温度探针温度值";
CM_ SG_ 1522 BMS_BattTempSensorNum24 "24号温度探针温度值";
CM_ SG_ 1523 BMS_BattTempSensorNum25 "25号温度探针温度值";
CM_ SG_ 1523 BMS_BattTempSensorNum26 "26号温度探针温度值";
CM_ SG_ 1523 BMS_BattTempSensorNum27 "27号温度探针温度值";
CM_ SG_ 1523 BMS_BattTempSensorNum28 "28号温度探针温度值";
CM_ SG_ 1523 BMS_BattTempSensorNum29 "29号温度探针温度值";
CM_ SG_ 1523 BMS_BattTempSensorNum30 "30号温度探针温度值";
CM_ SG_ 1523 BMS_BattTempSensorNum31 "31号温度探针温度值";
CM_ SG_ 1523 BMS_BattTempSensorNum32 "32号温度探针温度值";
CM_ SG_ 1524 BMS_BattTempSensorNum33 "33号温度探针温度值";
CM_ SG_ 1524 BMS_BattTempSensorNum34 "34号温度探针温度值";
CM_ SG_ 1524 BMS_BattTempSensorNum35 "35号温度探针温度值";
CM_ SG_ 1524 BMS_BattTempSensorNum36 "36号温度探针温度值";
CM_ SG_ 1524 BMS_BattTempSensorNum37 "37号温度探针温度值";
CM_ SG_ 1524 BMS_BattTempSensorNum38 "38号温度探针温度值";
CM_ SG_ 1524 BMS_BattTempSensorNum39 "39号温度探针温度值";
CM_ SG_ 1524 BMS_BattTempSensorNum40 "40号温度探针温度值";
CM_ SG_ 1552 Checksum_0x610 "Checksum: IDMSB XOR IDLSB XOR Byte1 XOR Byte2 XOR Byte3 XOR Byte4 XOR Byte5 XOR Byte6XOR Byte7";
CM_ SG_ 1552 OBC_InputCurrAbility "Input current availibility
输入电流能力";
CM_ SG_ 1552 OBC_ChgInputCurrent "Input current report
输入电流";
CM_ SG_ 1552 OBC_ChgInputVoltage "Input voltage report
输入电压";
CM_ SG_ 1552 OBC_CP_Duty "CP占空比";
CM_ SG_ 1552 Rolling_counter_0x610 "RollingCounter: used 4bit length signal and the arithmetic is increased from 0 to 15 by every message.";
CM_ SG_ 1552 OBC_CC_Status "CC电阻值";
CM_ SG_ 1553 OBC_SocketTempHig "充电插座过温保护";
CM_ SG_ 1553 OBC_InputVolLow "输入欠压";
CM_ SG_ 1553 OBC_HardTempHig "过温保护";
CM_ SG_ 1553 OBC_OutputShorCir "输出短路";
CM_ SG_ 1553 OBC_OutputVolHig "输出电压过高";
CM_ SG_ 1553 OBC_OutputVolLow "输出电压过低";
CM_ SG_ 1553 OBC_PFCOutputVolHig "PFC输出电压过高";
CM_ SG_ 1553 OBC_PFCOutputVolLow "PFC输出电压过低";
CM_ SG_ 1553 OBC_CommTimeOut "CAN通讯超时";
CM_ SG_ 1553 OBC_InputCurHig "输入电流过大";
CM_ SG_ 1553 OBC_InputVolHig "输入电压过高";
CM_ SG_ 1553 OBC_BMSVolLow "BMS电压过低";
CM_ SG_ 1553 OBC_BMSVolHig "BMS电压过高";
CM_ SG_ 1553 OBC_ContraryConnect "反接保护";
CM_ SG_ 1553 OBC_InsideComTimeOut "内部通讯超时";
CM_ SG_ 1553 OBC_ElockFail "电子锁故障";
CM_ SG_ 1553 OBC_HardFail "硬件故障";
CM_ SG_ 1553 OBC_OutputCurHig "输出电流过大";
CM_ SG_ 1553 OBC_SoketTemp_N "Soceket temperature reported
充电插座负极温度";
CM_ SG_ 1553 OBC_CoolantPlateTemp "Coolant temperature reported
冷却水温";
CM_ SG_ 1553 OBC_SoketTemp_L "Soceket temperature reported
充电插座正极温度";
CM_ SG_ 1555 Checksum_0x613 "Checksum: IDMSB XOR IDLSB XOR Byte1 XOR Byte2 XOR Byte3 XOR Byte4 XOR Byte5 XOR Byte6XOR Byte7";
CM_ SG_ 1555 OBC_MaxChrgOutpVolt "OBC maximum charging voltage
OBC最大充电电压";
CM_ SG_ 1555 OBC_MaxChrgOutpCur "OBC maximum charging current
OBC最大充电电流";
CM_ SG_ 1555 OBC_MaxChrgOutpPwr "OBC maximum charging power
OBC最大充电功率";
CM_ SG_ 1555 Rolling_counter_0x613 "RollingCounter: used 4bit length signal and the arithmetic is increased from 0 to 15 by every message.";
CM_ SG_ 1556 OBC_ChrgInsOutputVolt "OBC inside output votage reported
OBC内侧输出电压";
CM_ SG_ 1556 OBC_TempAct "actual temperature of OBC
OBC实际温度";
CM_ SG_ 1556 OBC_ElockSts "E-lock status
电子锁状态";
CM_ SG_ 1556 OBC_ChrgLockSts "E-lock status
电子锁状态";
CM_ SG_ 1556 OBC_RecoTimingSts "电子锁故障显示计时状态";
CM_ SG_ 1632 DCDC_OverTemp "温度保护";
CM_ SG_ 1632 DCDC_DischargeFail "主动放电失败";
CM_ SG_ 1632 DCDC_TBOX_WorkSts "DCDC状态报警";
CM_ SG_ 1632 DCDC_TBOX_TempFault "DCDC温度报警";
CM_ SG_ 1632 DCDC_InsideVolHig "母线过压";
CM_ SG_ 1632 DCDC_InsideVolLow "母线欠压";
CM_ SG_ 1632 DCDC_OutputCurHig "输出过流";
CM_ SG_ 1632 DCDC_OutputVolHig "输出过压";
CM_ SG_ 1632 DCDC_OutputVolLow "输出欠压";
CM_ SG_ 1632 DCDC_InputCurHig "输入过流";
CM_ SG_ 1632 DCDC_InputVolHig "输入过压";
CM_ SG_ 1632 DCDC_InputVolLow "输入欠压";
CM_ SG_ 1632 DCDC_OutputOpen "输出断路";
CM_ SG_ 1632 DCDC_HardFail "硬件故障";
CM_ SG_ 1632 DCDC_InsideShotCirc "内部母线短路";
CM_ SG_ 1632 DCDC_OutputShotCirc "输出短路";
CM_ SG_ 1632 DCDC_CommunTimeOut "通信超时";
CM_ SG_ 1632 DCDC_InsideCurHig "谐振腔电流过大";
CM_ SG_ 1793 VCU_WakeUpOBC "VCU唤醒OBC的信号，
注意：此报文为事件性报文，需要时按照100ms周期发送，不需要时停止发送。";
CM_ SG_ 1794 OBC_UDSDiag_ReqPhsy_0x702 "OBC UDS诊断物理寻址ID，数据位根据需求供应商可自定义";
CM_ SG_ 1795 DCDC_UDSDiag_ReqPhsy_0x703 "DCDC UDS诊断物理寻址ID，数据位根据需求供应商可自定义";
CM_ SG_ 1802 OBC_UDSDiag_Resp_0x70A "OBC UDS诊断响应ID，数据位根据需求供应商可自定义";
CM_ SG_ 1803 DCDC_UDSDiag_Resp_0x70B "DCDC  UDS诊断响应ID，数据位根据需求供应商可自定义";
CM_ SG_ 1810 BMS_UDSDiag_ReqPhsy_0x712 "BMS UDS诊断物理寻址ID，数据位根据需求供应商可自定义";
CM_ SG_ 1811 WPTC_UDSDiag_ReqPhsy_0x713 "WPTC UDS诊断物理寻址ID，数据位根据需求供应商可自定义";
CM_ SG_ 1812 MCU_UDSDiag_ReqPhsy_0x714 "MCU UDS诊断物理寻址ID，数据位根据需求供应商可自定义";
CM_ SG_ 1818 BMS_UDSDiag_Resp_0x71A "BMS UDS诊断响应ID，数据位根据需求供应商可自定义";
CM_ SG_ 1819 WPTC_UDSDiag_Resp_0x71B "WPTC UDS诊断响应ID，数据位根据需求供应商可自定义";
CM_ SG_ 1820 MCU_UDSDiag_Resp_0x71C "MCU UDS诊断响应ID，数据位根据需求供应商可自定义";
CM_ SG_ 1844 ACU_UDSDiag_ReqPhsy_0x734 "ACU UDS诊断物理寻址ID，数据位根据需求供应商可自定义";
CM_ SG_ 1852 ACU_UDSDiag_Resp_0x73C "ACU UDS诊断响应ID，数据位根据需求供应商可自定义";
CM_ SG_ 1856 VCU_UDSDiag_ReqPhsy_0x740 "VCU UDS诊断物理寻址ID，数据位根据需求供应商可自定义";
CM_ SG_ 1864 VCU_UDSDiag_Resp_0x748 "VCU UDS诊断响应ID，数据位根据需求供应商可自定义";
CM_ SG_ 2015 UDSDiag_ReqFunc_0x7DF "整车UDS诊断功能寻址ID，数据位根据需求供应商可自定义";


BA_DEF_ BO_  "NmMessage" ENUM "No","Yes";
BA_DEF_ BO_  "DiagState" ENUM  "No","Yes";
BA_DEF_ BO_  "DiagRequest" ENUM  "No","Yes";
BA_DEF_ BO_  "DiagResponse" ENUM  "No","Yes";
BA_DEF_ BO_  "GenMsgSendType" ENUM  "cyclic","IfActive","Event","CA","CE","NoMsgSendType";
BA_DEF_ BO_  "GenMsgCycleTime" INT 0 0;
BA_DEF_ SG_  "GenSigSendType" ENUM  "cyclic","OnChange","OnWrite","IfActive","OnChangeWithRepetition","OnWriteWithRepetition","IfActiveWithRepetition","NoSigSendType","OnChangeAndIfActive", "OnChangeAndIfActiveWithRepetition","CA","CE","Event";
BA_DEF_ SG_  "GenSigStartValue" INT 0 0;
BA_DEF_ SG_  "GenSigInactiveValue" INT 0 0;
BA_DEF_ BO_  "GenMsgCycleTimeFast" INT 0 0;
BA_DEF_ BO_  "GenMsgNrOfRepetition" INT 0 0;
BA_DEF_ BO_  "GenMsgDelayTime" INT 0 0;
BA_DEF_  "DBName" STRING ;
BA_DEF_ BU_  "NodeLayerModules" STRING ;
BA_DEF_ SG_  "GenSigTimeoutValue" INT 0 1000000000;
BA_DEF_ BO_  "GenMsgCycleTimeActive" INT 0 0;
BA_DEF_ BU_  "ILUsed" ENUM  "No","Yes";
BA_DEF_ BU_  "DiagStationAddress" HEX 0 255;
BA_DEF_ BU_  "NmNode" ENUM  "Not","Yes";
BA_DEF_ BU_  "NmStationAddress" HEX 0 65535;
BA_DEF_ BU_  "NmCAN" INT 0 2;
BA_DEF_  "Manufacturer" STRING ;
BA_DEF_  "NmType" STRING ;
BA_DEF_  "NmBaseAddress" HEX 0 2047;
BA_DEF_  "NmMessageCount" INT 0 255;
BA_DEF_ BO_  "_Cdb_Sc_CTm_FAW_v3_0" INT 0 0;
BA_DEF_ BO_  "_Cdb_Sc_CTm_FAW_v2_3" INT 0 0;
BA_DEF_ BO_  "_Cdb_Sc_CTm_FAW_v3_1" INT 0 0;
BA_DEF_ BO_  "_Cdb_Sc_CTm_FAW_v2_2" INT 0 0;
BA_DEF_ BO_  "_Cdb_Sc_CTm_FAW_v2_1" INT 0 0;
BA_DEF_ BO_  "GenMsgILSupport" ENUM  "No","Yes";
BA_DEF_ BO_  "GenMsgStartDelayTime" INT 0 65535;
BA_DEF_  "BusType" STRING ;


BA_DEF_DEF_  "NmMessage" "No";
BA_DEF_DEF_  "DiagState" "No";
BA_DEF_DEF_  "DiagRequest" "No";
BA_DEF_DEF_  "DiagResponse" "No";
BA_DEF_DEF_  "GenMsgSendType" "cyclic";
BA_DEF_DEF_  "GenMsgCycleTime" 0;
BA_DEF_DEF_  "GenSigSendType" "cyclic";
BA_DEF_DEF_  "GenSigStartValue" 0;
BA_DEF_DEF_  "GenSigInactiveValue" 0;
BA_DEF_DEF_  "GenMsgCycleTimeFast" 0;
BA_DEF_DEF_  "GenMsgNrOfRepetition" 0;
BA_DEF_DEF_  "GenMsgDelayTime" 0;
BA_DEF_DEF_  "DBName" "";
BA_DEF_DEF_  "NodeLayerModules" "CANoeILNLVector.dll";
BA_DEF_DEF_  "GenSigTimeoutValue" 0;
BA_DEF_DEF_  "GenMsgCycleTimeActive" 0;
BA_DEF_DEF_  "ILUsed" "No";
BA_DEF_DEF_  "DiagStationAddress" 0;
BA_DEF_DEF_  "NmNode" "Not";
BA_DEF_DEF_  "NmStationAddress" 0;
BA_DEF_DEF_  "NmCAN" 0;
BA_DEF_DEF_  "Manufacturer" "";
BA_DEF_DEF_  "NmType" "";
BA_DEF_DEF_  "NmBaseAddress" 1024;
BA_DEF_DEF_  "NmMessageCount" 128;
BA_DEF_DEF_  "_Cdb_Sc_CTm_FAW_v3_0" 0;
BA_DEF_DEF_  "_Cdb_Sc_CTm_FAW_v2_3" 0;
BA_DEF_DEF_  "_Cdb_Sc_CTm_FAW_v3_1" 0;
BA_DEF_DEF_  "_Cdb_Sc_CTm_FAW_v2_2" 0;
BA_DEF_DEF_  "_Cdb_Sc_CTm_FAW_v2_1" 0;
BA_DEF_DEF_  "GenMsgILSupport" "No";
BA_DEF_DEF_  "GenMsgStartDelayTime" 0;
BA_DEF_DEF_  "BusType" "CAN";
BA_ "DBName" "ME7_PTCAN_CMatrix_V208.190815_PVS";
BA_ "GenMsgCycleTime" BO_ 820 100;
BA_ "GenSigStartValue" SG_ 820 IBS_U_BATT 16383;
BA_ "GenSigStartValue" SG_ 820 IBS_I_Range 3;
BA_ "GenSigStartValue" SG_ 820 IBS_I_BATT 65535;
BA_ "GenSigStartValue" SG_ 820 IBS_T_BATT 255;
BA_ "GenSigStartValue" SG_ 820 IBS_IBATT_QUIESCENT 255;
BA_ "GenMsgCycleTime" BO_ 821 100;
BA_ "GenSigStartValue" SG_ 821 IBS_SOC 255;
BA_ "GenSigStartValue" SG_ 821 IBS_SOH_SUL 255;
BA_ "GenSigStartValue" SG_ 821 IBS_SOFV_StopEnable 255;
BA_ "GenSigStartValue" SG_ 821 IBS_SOFV_Restart 255;
BA_ "GenSigStartValue" SG_ 821 IBS_SOH_LAM 255;
BA_ "GenSigStartValue" SG_ 821 IBS_SOH_COR 255;
BA_ "GenSigStartValue" SG_ 821 IBS_SOC_STATE 3;
BA_ "GenSigStartValue" SG_ 821 IBS_SOH_SUL_STATE 3;
BA_ "GenSigStartValue" SG_ 821 IBS_SOFV_StopEnable_STATE 3;
BA_ "GenSigStartValue" SG_ 821 IBS_SOFV_Restart_STATE 3;
BA_ "GenSigStartValue" SG_ 821 IBS_SOH_LAM_STATE 3;
BA_ "GenSigStartValue" SG_ 821 IBS_SOH_COR_STATE 3;
BA_ "GenMsgCycleTime" BO_ 404 100;
BA_ "GenMsgCycleTime" BO_ 405 100;
BA_ "GenMsgCycleTime" BO_ 401 50;
BA_ "GenMsgCycleTime" BO_ 599 100;
BA_ "GenMsgCycleTime" BO_ 1323 100;
BA_ "GenMsgCycleTime" BO_ 1325 100;
BA_ "GenMsgCycleTime" BO_ 1326 100;
BA_ "GenMsgCycleTime" BO_ 1327 100;
BA_ "GenMsgCycleTime" BO_ 1379 100;
BA_ "GenMsgCycleTime" BO_ 596 100;
BA_ "GenMsgCycleTime" BO_ 597 100;
BA_ "GenMsgCycleTime" BO_ 800 100;
BA_ "GenMsgCycleTime" BO_ 806 100;
BA_ "GenMsgCycleTime" BO_ 582 20;
BA_ "GenMsgSendType" BO_ 144 2;
BA_ "GenSigSendType" SG_ 144 BCM_ReAuthRequest 1;
BA_ "GenMsgCycleTime" BO_ 851 100;
BA_ "GenSigSendType" SG_ 851 TBOX_VCU_12vChargeReq 1;
BA_ "GenSigSendType" SG_ 851 TBOX_ChargeDepthSet 1;
BA_ "GenMsgCycleTime" BO_ 881 100;
BA_ "GenMsgCycleTime" BO_ 882 100;
BA_ "GenMsgCycleTime" BO_ 883 100;
BA_ "GenMsgSendType" BO_ 32 2;
BA_ "GenSigSendType" SG_ 32 MCU_AuthReq_BCM_Code 1;
BA_ "GenMsgSendType" BO_ 33 2;
BA_ "GenSigSendType" SG_ 33 BCM_AuthResp_MCU_Code 1;
BA_ "GenMsgCycleTime" BO_ 154 100;
BA_ "GenSigStartValue" SG_ 154 VCU_MCU_TrqReq 10000;
BA_ "GenMsgCycleTime" BO_ 155 20;
BA_ "GenSigStartValue" SG_ 155 VCU_DC_VoltageReq 120;
BA_ "GenMsgCycleTime" BO_ 156 100;
BA_ "GenMsgCycleTime" BO_ 157 100;
BA_ "GenMsgCycleTime" BO_ 256 20;
BA_ "GenMsgCycleTime" BO_ 258 20;
BA_ "GenSigStartValue" SG_ 258 BMS_Insulation_R 1022;
BA_ "GenMsgCycleTime" BO_ 261 100;
BA_ "GenMsgCycleTime" BO_ 274 100;
BA_ "GenMsgCycleTime" BO_ 277 100;
BA_ "GenMsgCycleTime" BO_ 278 100;
BA_ "GenMsgCycleTime" BO_ 276 100;
BA_ "GenSigStartValue" SG_ 276 BMS_InputWaterTemp 255;
BA_ "GenSigStartValue" SG_ 276 BMS_OutputWaterTemp 255;
BA_ "GenMsgCycleTime" BO_ 279 100;
BA_ "GenSigStartValue" SG_ 279 VCU_InputWaterTemp 65;
BA_ "GenSigStartValue" SG_ 279 VCU_OutputWaterTemp 65;
BA_ "GenMsgCycleTime" BO_ 288 20;
BA_ "GenSigStartValue" SG_ 288 MCU_MotorActualTorque 32766;
BA_ "GenSigStartValue" SG_ 288 MCU_MotorSpeed 65534;
BA_ "GenMsgCycleTime" BO_ 289 20;
BA_ "GenMsgCycleTime" BO_ 290 100;
BA_ "GenSigStartValue" SG_ 290 MCU_MaxAvailableTorque 2046;
BA_ "GenSigStartValue" SG_ 290 MCU_MinAvailableTorque 2046;
BA_ "GenMsgCycleTime" BO_ 291 100;
BA_ "GenSigStartValue" SG_ 291 MCU_DC_linkVoltage 1022;
BA_ "GenSigStartValue" SG_ 291 MCU_DC_linkCurrent 2046;
BA_ "GenSigStartValue" SG_ 291 MCU_InverterTemp 254;
BA_ "GenSigStartValue" SG_ 291 MCU_MotorTemp 254;
BA_ "GenSigStartValue" SG_ 291 MCU_WaterTemp 254;
BA_ "GenSigStartValue" SG_ 291 MCU_MotorCount 1;
BA_ "GenSigStartValue" SG_ 291 MCU_MotorSeqNum 1;
BA_ "GenMsgCycleTime" BO_ 292 100;
BA_ "GenSigStartValue" SG_ 292 MCU_RotorTemp 254;
BA_ "GenSigStartValue" SG_ 292 MCU_Motoroffset 1022;
BA_ "GenMsgCycleTime" BO_ 293 20;
BA_ "GenSigStartValue" SG_ 293 ESP_TorqueIncrease 10000;
BA_ "GenSigStartValue" SG_ 293 ESP_TorqueReqFast 10000;
BA_ "GenSigStartValue" SG_ 293 ESP_TorqueReqSlow 10000;
BA_ "GenMsgCycleTime" BO_ 320 20;
BA_ "GenSigStartValue" SG_ 320 VCU_CurrentMotorTorq 10000;
BA_ "GenSigStartValue" SG_ 320 VCU_MaxMotorTorque 10000;
BA_ "GenSigStartValue" SG_ 320 VCU_MinMotorTorque 10000;
BA_ "GenMsgCycleTime" BO_ 321 20;
BA_ "GenSigStartValue" SG_ 321 VCU_DriverDemandTorq 10000;
BA_ "GenMsgCycleTime" BO_ 336 20;
BA_ "GenMsgCycleTime" BO_ 337 20;
BA_ "GenMsgCycleTime" BO_ 373 10;
BA_ "GenMsgCycleTime" BO_ 392 100;
BA_ "GenMsgCycleTime" BO_ 528 10;
BA_ "GenMsgCycleTime" BO_ 529 20;
BA_ "GenMsgCycleTime" BO_ 532 20;
BA_ "GenSigStartValue" SG_ 532 ESP_VLC_EngTrqReq 10000;
BA_ "GenMsgCycleTime" BO_ 579 20;
BA_ "GenMsgCycleTime" BO_ 642 20;
BA_ "GenSigSendType" SG_ 642 SCM_CC_Switch 1;
BA_ "GenSigSendType" SG_ 642 SCM_Res_Set_Switch 1;
BA_ "GenSigSendType" SG_ 642 SCM_PRND_req 1;
BA_ "GenMsgCycleTime" BO_ 734 100;
BA_ "GenSigSendType" SG_ 734 HU_VCU_RemoteChrgLock 1;
BA_ "GenSigSendType" SG_ 734 HU_ChargeDepthSet 1;
BA_ "GenSigSendType" SG_ 734 HU_EnergyRecoveryPer 1;
BA_ "GenSigStartValue" SG_ 734 HU_EnergyRecoveryPer 127;
BA_ "GenSigSendType" SG_ 734 HU_SpeedLimitSW 1;
BA_ "GenSigSendType" SG_ 734 HU_LimitSpeedSet 1;
BA_ "GenSigStartValue" SG_ 734 HU_LimitSpeedSet 255;
BA_ "GenSigSendType" SG_ 734 HU_DriveMode 1;
BA_ "GenSigSendType" SG_ 734 HU_AccelerationModePer 1;
BA_ "GenSigStartValue" SG_ 734 HU_AccelerationModePer 127;
BA_ "GenSigSendType" SG_ 734 HU_CreepSwitch 1;
BA_ "GenSigSendType" SG_ 734 HU_SubMileage_Reset 1;
BA_ "GenSigSendType" SG_ 734 HU_DMS_SW 1;
BA_ "GenMsgCycleTime" BO_ 774 1000;
BA_ "GenMsgCycleTime" BO_ 784 50;
BA_ "GenMsgCycleTime" BO_ 804 100;
BA_ "GenMsgCycleTime" BO_ 805 100;
BA_ "GenMsgCycleTime" BO_ 853 1000;
BA_ "GenSigStartValue" SG_ 853 TBOX_TimeSyncData_Month 1;
BA_ "GenSigStartValue" SG_ 853 TBOX_TimeSyncData_Day 1;
BA_ "GenMsgCycleTime" BO_ 905 100;
BA_ "GenSigStartValue" SG_ 905 DCDC_TempAct 40;
BA_ "GenMsgCycleTime" BO_ 928 100;
BA_ "GenSigSendType" SG_ 928 ICM_SubMileage_Reset 1;
BA_ "NmMessage" BO_ 1027 1;
BA_ "GenMsgSendType" BO_ 1027 2;
BA_ "GenSigSendType" SG_ 1027 VCU_NM_DA 1;
BA_ "GenSigSendType" SG_ 1027 VCU_NM_ALIVE 1;
BA_ "GenSigSendType" SG_ 1027 VCU_NM_RING 1;
BA_ "GenSigSendType" SG_ 1027 VCU_NM_LIMPHOME 1;
BA_ "GenSigSendType" SG_ 1027 VCU_NM_SLEEP_Ind 1;
BA_ "GenSigSendType" SG_ 1027 VCU_NM_SLEEP_ACK 1;
BA_ "NmMessage" BO_ 1032 1;
BA_ "GenMsgSendType" BO_ 1032 2;
BA_ "GenSigSendType" SG_ 1032 GW_PT_NM_DA 1;
BA_ "GenSigSendType" SG_ 1032 GW_PT_NM_ALIVE 1;
BA_ "GenSigSendType" SG_ 1032 GW_PT_NM_RING 1;
BA_ "GenSigSendType" SG_ 1032 GW_PT_NM_LIMPHOME 1;
BA_ "GenSigSendType" SG_ 1032 GW_PT_NM_SLEEP_Ind 1;
BA_ "GenSigSendType" SG_ 1032 GW_PT_NM_SLEEP_ACK 1;
BA_ "GenMsgCycleTime" BO_ 1299 500;
BA_ "GenSigStartValue" SG_ 1299 BMS_MaxTemp 255;
BA_ "GenSigStartValue" SG_ 1299 BMS_MinTemp 255;
BA_ "GenSigStartValue" SG_ 1299 BMS_BattTempDev 255;
BA_ "GenSigStartValue" SG_ 1299 BMS_CCTemp1 255;
BA_ "GenSigStartValue" SG_ 1299 BMS_CCTemp2 255;
BA_ "GenMsgCycleTime" BO_ 1300 500;
BA_ "GenMsgCycleTime" BO_ 1324 200;
BA_ "GenMsgCycleTime" BO_ 1328 1000;
BA_ "GenMsgCycleTime" BO_ 1329 1000;
BA_ "GenMsgCycleTime" BO_ 1330 1000;
BA_ "GenMsgCycleTime" BO_ 1331 1000;
BA_ "GenMsgCycleTime" BO_ 1332 1000;
BA_ "GenMsgCycleTime" BO_ 1333 1000;
BA_ "GenMsgCycleTime" BO_ 1334 1000;
BA_ "GenMsgCycleTime" BO_ 1335 1000;
BA_ "GenMsgCycleTime" BO_ 1336 1000;
BA_ "GenMsgCycleTime" BO_ 1337 1000;
BA_ "GenMsgCycleTime" BO_ 1338 1000;
BA_ "GenMsgCycleTime" BO_ 1339 1000;
BA_ "GenMsgCycleTime" BO_ 1340 1000;
BA_ "GenMsgCycleTime" BO_ 1341 1000;
BA_ "GenMsgCycleTime" BO_ 1342 1000;
BA_ "GenMsgCycleTime" BO_ 1343 1000;
BA_ "GenMsgCycleTime" BO_ 1344 1000;
BA_ "GenMsgCycleTime" BO_ 1345 1000;
BA_ "GenMsgCycleTime" BO_ 1346 1000;
BA_ "GenMsgCycleTime" BO_ 1347 1000;
BA_ "GenMsgCycleTime" BO_ 1348 1000;
BA_ "GenMsgCycleTime" BO_ 1349 1000;
BA_ "GenMsgCycleTime" BO_ 1350 1000;
BA_ "GenMsgCycleTime" BO_ 1351 1000;
BA_ "GenMsgCycleTime" BO_ 1352 1000;
BA_ "GenMsgCycleTime" BO_ 1353 1000;
BA_ "GenMsgCycleTime" BO_ 1354 1000;
BA_ "GenMsgCycleTime" BO_ 1360 200;
BA_ "GenMsgCycleTime" BO_ 1377 100;
BA_ "GenMsgCycleTime" BO_ 1378 100;
BA_ "GenSigStartValue" SG_ 1378 MCU_MotorSts_GBT 3;
BA_ "GenMsgCycleTime" BO_ 1424 5000;
BA_ "GenMsgCycleTime" BO_ 1425 5000;
BA_ "GenMsgCycleTime" BO_ 1426 5000;
BA_ "GenSigStartValue" SG_ 1426 BMS_BattRetrospectCode 1;
BA_ "GenMsgCycleTime" BO_ 1427 5000;
BA_ "GenSigStartValue" SG_ 1427 BMS_BattProductionDate 1;
BA_ "GenSigStartValue" SG_ 1427 BMS_BattS_Num 1;
BA_ "GenSigStartValue" SG_ 1427 BMS_BattRecycleCode 1;
BA_ "GenMsgCycleTime" BO_ 1428 5000;
BA_ "GenSigStartValue" SG_ 1428 BMS_BattCodeLenth 1;
BA_ "GenMsgCycleTime" BO_ 1504 5000;
BA_ "GenMsgCycleTime" BO_ 1505 5000;
BA_ "GenMsgCycleTime" BO_ 1506 5000;
BA_ "GenMsgCycleTime" BO_ 1507 5000;
BA_ "GenMsgCycleTime" BO_ 1508 5000;
BA_ "GenMsgCycleTime" BO_ 1510 10000;
BA_ "GenMsgCycleTime" BO_ 1511 10000;
BA_ "GenMsgCycleTime" BO_ 1473 10000;
BA_ "GenMsgCycleTime" BO_ 1520 1000;
BA_ "GenMsgCycleTime" BO_ 1521 1000;
BA_ "GenMsgCycleTime" BO_ 1522 1000;
BA_ "GenMsgCycleTime" BO_ 1523 1000;
BA_ "GenMsgCycleTime" BO_ 1524 1000;
BA_ "GenMsgCycleTime" BO_ 1552 100;
BA_ "GenMsgCycleTime" BO_ 1553 100;
BA_ "GenSigStartValue" SG_ 1553 OBC_SoketTemp_N 40;
BA_ "GenSigStartValue" SG_ 1553 OBC_CoolantPlateTemp 55;
BA_ "GenSigStartValue" SG_ 1553 OBC_SoketTemp_L 40;
BA_ "GenMsgCycleTime" BO_ 1555 100;
BA_ "GenMsgCycleTime" BO_ 1556 100;
BA_ "GenSigStartValue" SG_ 1556 OBC_TempAct 40;
BA_ "GenMsgCycleTime" BO_ 1632 100;
BA_ "GenMsgCycleTime" BO_ 1793 100;
BA_ "DiagState" BO_ 1794 1;
BA_ "DiagResponse" BO_ 1794 1;
BA_ "GenMsgSendType" BO_ 1794 2;
BA_ "GenSigSendType" SG_ 1794 OBC_UDSDiag_ReqPhsy_0x702 1;
BA_ "DiagState" BO_ 1795 1;
BA_ "DiagResponse" BO_ 1795 1;
BA_ "GenMsgSendType" BO_ 1795 2;
BA_ "GenSigSendType" SG_ 1795 DCDC_UDSDiag_ReqPhsy_0x703 1;
BA_ "DiagState" BO_ 1802 1;
BA_ "DiagResponse" BO_ 1802 1;
BA_ "GenMsgSendType" BO_ 1802 2;
BA_ "GenSigSendType" SG_ 1802 OBC_UDSDiag_Resp_0x70A 1;
BA_ "DiagState" BO_ 1803 1;
BA_ "DiagResponse" BO_ 1803 1;
BA_ "GenMsgSendType" BO_ 1803 2;
BA_ "GenSigSendType" SG_ 1803 DCDC_UDSDiag_Resp_0x70B 1;
BA_ "DiagState" BO_ 1810 1;
BA_ "DiagResponse" BO_ 1810 1;
BA_ "GenMsgSendType" BO_ 1810 2;
BA_ "GenSigSendType" SG_ 1810 BMS_UDSDiag_ReqPhsy_0x712 1;
BA_ "DiagState" BO_ 1811 1;
BA_ "DiagResponse" BO_ 1811 1;
BA_ "GenMsgSendType" BO_ 1811 2;
BA_ "GenSigSendType" SG_ 1811 WPTC_UDSDiag_ReqPhsy_0x713 1;
BA_ "DiagState" BO_ 1812 1;
BA_ "DiagResponse" BO_ 1812 1;
BA_ "GenMsgSendType" BO_ 1812 2;
BA_ "GenSigSendType" SG_ 1812 MCU_UDSDiag_ReqPhsy_0x714 1;
BA_ "DiagState" BO_ 1818 1;
BA_ "DiagResponse" BO_ 1818 1;
BA_ "GenMsgSendType" BO_ 1818 2;
BA_ "GenSigSendType" SG_ 1818 BMS_UDSDiag_Resp_0x71A 1;
BA_ "DiagState" BO_ 1819 1;
BA_ "DiagResponse" BO_ 1819 1;
BA_ "GenMsgSendType" BO_ 1819 2;
BA_ "GenSigSendType" SG_ 1819 WPTC_UDSDiag_Resp_0x71B 1;
BA_ "DiagState" BO_ 1820 1;
BA_ "DiagResponse" BO_ 1820 1;
BA_ "GenMsgSendType" BO_ 1820 2;
BA_ "GenSigSendType" SG_ 1820 MCU_UDSDiag_Resp_0x71C 1;
BA_ "DiagState" BO_ 1844 1;
BA_ "DiagResponse" BO_ 1844 1;
BA_ "GenMsgSendType" BO_ 1844 2;
BA_ "GenSigSendType" SG_ 1844 ACU_UDSDiag_ReqPhsy_0x734 1;
BA_ "DiagState" BO_ 1852 1;
BA_ "DiagResponse" BO_ 1852 1;
BA_ "GenMsgSendType" BO_ 1852 2;
BA_ "GenSigSendType" SG_ 1852 ACU_UDSDiag_Resp_0x73C 1;
BA_ "DiagState" BO_ 1856 1;
BA_ "DiagResponse" BO_ 1856 1;
BA_ "GenMsgSendType" BO_ 1856 2;
BA_ "GenSigSendType" SG_ 1856 VCU_UDSDiag_ReqPhsy_0x740 1;
BA_ "DiagState" BO_ 1864 1;
BA_ "DiagResponse" BO_ 1864 1;
BA_ "GenMsgSendType" BO_ 1864 2;
BA_ "GenSigSendType" SG_ 1864 VCU_UDSDiag_Resp_0x748 1;
BA_ "DiagState" BO_ 2015 1;
BA_ "DiagResponse" BO_ 2015 1;
BA_ "GenMsgSendType" BO_ 2015 2;
BA_ "GenSigSendType" SG_ 2015 UDSDiag_ReqFunc_0x7DF 1;
VAL_ 820 IBS_U_BATT 16383 "invalid" ;
VAL_ 820 IBS_I_Range 3 "invalid" 2 "current Range [-1500, 1500A]" 1 "current Range [-200, 200A]" 0 "current Range [-1, 1A]" ;
VAL_ 820 IBS_I_BATT 65535 "invalid" ;
VAL_ 820 IBS_T_BATT 255 "invalid" ;
VAL_ 820 IBS_IBATT_QUIESCENT 255 "invalid" 254 "Out of bounds" 253 "Overflow" ;
VAL_ 820 IBS_Status_Current 3 "LIN saturation (no HW defect)" 2 "HW defect (out of range or ADC defect)" 1 "Error Open circuit" 0 "No error" ;
VAL_ 820 IBS_Status_Voltage 3 "LIN saturation (no HW defect)" 2 "HW defect (ADC defect)" 1 "Error Open circuit" 0 "No error" ;
VAL_ 820 IBS_Status_Temp 3 "LIN saturation (no HW defect)" 2 "HW defect (ADC defect)" 1 "not used" 0 "No error" ;
VAL_ 820 IBS_ERROR_Calib 1 "Error" 0 "No error" ;
VAL_ 820 IBS_ERROR_IDENT 1 "Error" 0 "No error" ;
VAL_ 820 IBS_Resp_Error 1 "Error" 0 "No error" ;
VAL_ 820 IBS_FLAG_INCONSISTENCY 1 "battery inconsistency" 0 "no battery inconsistency" ;
VAL_ 821 IBS_SOC 255 "invalid" ;
VAL_ 821 IBS_SOH_SUL 255 "invalid" ;
VAL_ 821 IBS_SOFV_StopEnable 255 "invalid" ;
VAL_ 821 IBS_SOFV_Restart 255 "invalid" ;
VAL_ 821 IBS_SOH_LAM 255 "invalid" ;
VAL_ 821 IBS_SOH_COR 255 "invalid" ;
VAL_ 821 IBS_SOC_STATE 3 "invalid" 2 "deviation < 10%" 1 "deviation < 15%" 0 "deviation > 15%" ;
VAL_ 821 IBS_SOH_SUL_STATE 3 "invalid" 2 "not used" 1 "learned" 0 "not learned" ;
VAL_ 821 IBS_SOFV_StopEnable_STATE 3 "invalid" 2 "not used" 1 "accurate (deviation < 400mV)" 0 "inaccurate" ;
VAL_ 821 IBS_SOFV_Restart_STATE 3 "invalid" 2 "undefined" 1 "accurate (deviation < 400mV)" 0 "inaccurate" ;
VAL_ 821 IBS_SOH_LAM_STATE 3 "invalid" 2 "undefined" 1 "learned" 0 "not learned" ;
VAL_ 821 IBS_SOH_COR_STATE 3 "invalid" 2 "accurate (deviation < 400mV)" 1 "inaccurate" 0 "not learned" ;
VAL_ 404 PA_APA_DistanceValueLR_FL 255 "Invalid" 254 "no object was detected" 253 "Reserved" 252 "Reserved" 251 "Reserved" ;
VAL_ 404 PA_APA_DistanceValueLR_FR 255 "Invalid" 254 "no object was detected" 253 "Reserved" 252 "Reserved" 251 "Reserved" ;
VAL_ 404 PA_APA_DistanceValueSR_FL 127 "Invalid" 126 "no object was detected" ;
VAL_ 404 PA_APA_DistanceValueSR_FML 127 "Invalid" 126 "no object was detected" ;
VAL_ 404 PA_APA_DistanceValueSR_FMR 127 "Invalid" 126 "no object was detected" ;
VAL_ 404 PA_APA_DistanceValueSR_FR 127 "Invalid" 126 "no object was detected" ;
VAL_ 405 PA_APA_DistanceValueLR_RL 255 "Invalid" 254 "no object was detected" 253 "Reserved" 252 "Reserved" 251 "Reserved" ;
VAL_ 405 PA_APA_DistanceValueLR_RR 255 "Invalid" 254 "no object was detected" 253 "Reserved" 252 "Reserved" 251 "Reserved" ;
VAL_ 405 PA_APA_DistanceValueSR_RL 127 "Invalid" 126 "no object was detected" ;
VAL_ 405 PA_APA_DistanceValueSR_RML 127 "Invalid" 126 "no object was detected" ;
VAL_ 405 PA_APA_DistanceValueSR_RMR 127 "Invalid" 126 "no object was detected" ;
VAL_ 405 PA_APA_DistanceValueSR_RR 127 "Invalid" 126 "no object was detected" ;
VAL_ 401 APS_R_Gear_RequestTips 3 "Reserved" 2 "RequestTips" 1 "NoRequestTips" 0 "Default" ;
VAL_ 401 APS_VCU_Req_StraightOut 0 "NoRequest                                            0x1:RequestStraightOut" ;
VAL_ 401 APS_VCU_Gear_Request 7 "reserved" 6 "reserved" 5 "reserved" 4 "APADrvDirRqVCU_Drive" 3 "APADrvDirRqVCU_Neutral" 2 "APADrvDirRqVCU_Reverse" 1 "APADrvDirRqVCU_Park" 0 "APADrvDirRqVCU_Idle" ;
VAL_ 401 APS_VCU_Req_StraightCtrol 2 "Straight In 后退                               0x3:Reserved" 0 "STOP  停止                                        0x1:Straight Out  前进" ;
VAL_ 401 APS_ACU_DrvSeatBeltSWSts 1 "APS request ACU send Buckle on" 0 "default" ;
VAL_ 599 AC_RemoteAC 7 "reserved" 6 "reserved" 5 "reserved" 4 "RemotDefrost" 3 "RemoteHot" 2 "RemoteCool:" 1 "RemoteVentilation" 0 "NoRequest:" ;
VAL_ 1379 VCU_CCOut 1 "active" 0 "inactive" ;
VAL_ 1379 VCU_FastCharge_A 1 "active" 0 "inactive" ;
VAL_ 596 AC_WindModeSts 7 "reserved" 6 "reserved" 5 "Blow defrost" 4 "Blow face" 3 "Blow foot&defrost1" 2 "Blow foot" 1 "Blow face&foot" 0 "default" ;
VAL_ 800 EAC_Status 3 "System fault" 2 "Active" 1 "Not active" 0 "initi" ;
VAL_ 806 APTC_WorkSts 3 "Reserved" 2 "System fault" 1 "运行" 0 "关闭" ;
VAL_ 806 APTC_ErrorLevel 3 "Level_3" 2 "Level_2" 1 "Level_1" 0 "No Error" ;
VAL_ 582 MPC_LKS_LeftVisualization 7 "Reserved" 6 "Reserved" 5 "Reserved" 4 "intervention&warning" 3 "warning.警告" 2 "intervention；干预" 1 "line tracking；车道线跟踪" 0 "no display；" ;
VAL_ 582 MPC_LKS_RightVisualization 7 "reserved" 6 "reserved" 5 "reserved" 4 "intervention&warning" 3 "warning.警告" 2 "intervention；干预" 1 "line tracking；车道线跟踪" 0 "no display；" ;
VAL_ 144 BCM_ReAuthRequest 1 "ReAuthentication Triger active" 0 "no ReAuthRequest" ;
VAL_ 851 TBOX_VCU_12vChargeReq 1 "Active" 0 "Not active" ;
VAL_ 851 TBOX_VCU_TimeCharge 3 "充电预约已到结束" 2 "充电预约未到结束" 1 "start" 0 "No request" ;
VAL_ 851 TBOX_ChargeDepthSet 3 "预留" 2 "长途旅行" 1 "日常行驶" 0 "default" ;
VAL_ 851 TBOX_VCU_RemoteChrgLock 1 "unlock" 0 "no request" ;
VAL_ 881 VCU_instantaneous_Energy 4095 "Invalid" ;
VAL_ 881 VCU_instantaneous_EnergyUnit 1 "kwh/100km" 0 "KW" ;
VAL_ 881 VCU_TrailerMode 1 "Active" 0 "NoActive" ;
VAL_ 881 VCU_trip 4095 "Invalid" ;
VAL_ 881 VCU_ChargeIncreaseMileage 2047 "Invalid" ;
VAL_ 882 VCU_SubtotalAverageEnergy 511 "Invalid" ;
VAL_ 882 VCU_SubtotalEnergy 32767 "Invalid" ;
VAL_ 882 VCU_Subtotaltime 32767 "Invalid" ;
VAL_ 882 VCU_ChargeIncreaseMileageSpeed 2047 "Invalid" ;
VAL_ 883 VCU_DST 4095 "Invalid" ;
VAL_ 883 VCU_SingleMileageAverageEnergy 511 "Invalid" ;
VAL_ 883 VCU_SingleMileageEnergy 32767 "Invalid" ;
VAL_ 883 VCU_SingleMileagetime 32767 "Invalid" ;
VAL_ 883 VCU_SlowChargeGunSt 3 "无效" 2 "插枪" 1 "未插枪" 0 "正在检测" ;
VAL_ 883 VCU_FastChargeGunSt 3 "无效" 2 "插枪" 1 "未插枪" 0 "正在检测" ;
VAL_ 154 VCU_ErrorLevel 7 "预留" 6 "预留" 5 "五级故障" 4 "四级故障" 3 "三级故障" 2 "二级故障" 1 "一级故障" 0 "无故障" ;
VAL_ 154 VCU_MCU_WorkMode 7 "预留" 6 "预留" 5 "预留" 4 "Discharge" 3 "Calibration mode" 2 "Speed mode" 1 "Torque mode" 0 "Disable" ;
VAL_ 154 VCU_MCU_TrqReq 32767 "Invalid" ;
VAL_ 154 VCU_MCU_SpdReq 65535 "Invalid" ;
VAL_ 154 VCU_MotorOffsetCalCmd 255 "条件准备完成" 254 "其他" 9 "与ESP通信故障" 8 "与MCU通信故障" 7 "模式不正确" 6 "BMS discharge power out of range" 5 "ESP not disabled；" 4 "Vehicle Speed is not 0kph；（此处 车速 不能用电机 转速 计算 ）" 3 "Shift Position Not in Park or Neutral；" 2 "PT Not Ready；" 1 "VCU正在判断条件" 0 "无条件准备请求" ;
VAL_ 155 VCU_BMS_WorkMode 7 "预留" 6 "预留" 5 "紧急下电指令" 4 "下电指令" 3 "放电指令" 2 "慢充指令" 1 "快充指令" 0 "standby" ;
VAL_ 155 VCU_DC_WorkMode 7 "预留" 6 "预留" 5 "预留" 4 "预留" 3 "预留" 2 "Discharge" 1 "Enable" 0 "Disable" ;
VAL_ 155 VCU_WPTC_En 1 "Enable" 0 "Disable" ;
VAL_ 155 VCU_WPTC_Request 3 "Reserved" 2 "Stop" 1 "Start" 0 "Default" ;
VAL_ 155 VCU_OBC_RemoteCharge 1 "Active" 0 "Inactive" ;
VAL_ 155 VCU_OBC_ChrgLock 3 "预留" 2 "lock" 1 "unlock" 0 "no request" ;
VAL_ 155 VCU_TBOX_ChrgLockSts 7 "预留" 6 "预留" 5 "预留" 4 "解锁超时" 3 "解锁失败" 2 "正在解锁" 1 "unlock" 0 "Default" ;
VAL_ 155 VCU_ACU_DrvSeatBeltSWSts 1 "VCU request ACU send Buckle on" 0 "default" ;
VAL_ 155 VCU_OBC_ChrgEnable 7 "预留" 6 "预留" 5 "预留" 4 "预留" 3 "预留" 2 "预留" 1 "Enable" 0 "Disable" ;
VAL_ 156 VCU_Cruise_Sts 3 "fault" 2 "active" 1 "ON" 0 "off" ;
VAL_ 156 VCU_DriveInhibitAlarm 1 "Active" 0 "Inactive" ;
VAL_ 156 VCU_EPB_FunctionSet 3 "Reserved" 2 "拉起" 1 "释放" 0 "Default" ;
VAL_ 156 VCU_HU_ChrgLockSts 7 "预留" 6 "预留" 5 "预留" 4 "解锁超时" 3 "解锁失败" 2 "正在解锁" 1 "unlock" 0 "Default" ;
VAL_ 156 VCU_SpeedLimitSWSts 1 "Limit" 0 "No Limit" ;
VAL_ 156 VCU_DMS_Status 3 "非常疲劳" 2 "疲劳" 1 "清醒" 0 "OFF" ;
VAL_ 156 VCU_DMS_SWStatus 1 "ON" 0 "OFF" ;
VAL_ 156 VCU_LimitSpeedAlarm_L 1 "Active" 0 "No Active" ;
VAL_ 156 VCU_LimitSpeedAlarm_V 1 "Active" 0 "No Active" ;
VAL_ 156 VCU_SlowChargeLight 7 "充电故障" 6 "预约充电" 5 "充电未完成可拔枪" 4 "充电完成可拔枪" 3 "充电完成" 2 "充电中" 1 "正在启动交流充电" 0 "默认" ;
VAL_ 156 VCU_FastChargeLight 7 "预留3" 6 "预留2" 5 "预留1" 4 "充电故障" 3 "充电完成" 2 "充电中" 1 "正在启动直流充电" 0 "默认" ;
VAL_ 157 VCU_AC_ComfortEAC_En 1 "Enable" 0 "Disable" ;
VAL_ 157 VCU_AC_BatCoolEAC_En 1 "Enable" 0 "Disable" ;
VAL_ 157 VCU_AC_APTC_En 1 "Enable" 0 "Disable" ;
VAL_ 157 VCU_BattPump_ErrorSts 7 "Reserved" 6 "空转" 5 "过压" 4 "过温" 3 "低压" 2 "过流" 1 "堵转" 0 "正常" ;
VAL_ 157 VCU_RemoteACFeedback 15 "预留" 14 "预留" 13 "预留" 12 "预留" 11 "预留" 10 "预留" 9 "启动中" 8 "其他故障" 7 "启动太频繁" 6 "空调开启最大时间到" 5 "功率低" 4 "SOC过低" 3 "高压系统故障" 2 "本地状态" 1 "正在远程空调:" 0 "未开启" ;
VAL_ 157 VCU_FanSts 1 "故障" 0 "无故障" ;
VAL_ 157 VCU_12VbatterySOHLow 1 "SOH Low" 0 "SOH Normal" ;
VAL_ 157 VCU_LVSmartChrg_Status 3 "Reserved" 2 "LVSmartChargeFalut" 1 "LVSmartCharging" 0 "NoLVSmartCharge" ;
VAL_ 256 BMS_WaringLevel 7 "预留" 6 "预留" 5 "预留" 4 "预留" 3 "三级告警" 2 "二级告警" 1 "一级告警" 0 "无告警" ;
VAL_ 256 BMS_RelayChrPos 3 "Debounce（预留）" 2 "Fault （故障)" 1 "Close（闭合）" 0 "Open （断开）" ;
VAL_ 256 BMS_RelayNeg 3 "Debounce（预留）" 2 "Fault （故障)" 1 "Close（闭合）" 0 "Open （断开）" ;
VAL_ 256 BMS_RelayPre 3 "Debounce（预留）" 2 "Fault （故障)" 1 "Close（闭合）" 0 "Open （断开）" ;
VAL_ 256 BMS_RelayPos 3 "Debounce（预留）" 2 "Fault （故障)" 1 "Close（闭合）" 0 "Open （断开）" ;
VAL_ 256 BMS_RelayChrNeg 3 "Debounce（预留）" 2 "Fault （故障)" 1 "Close（闭合）" 0 "Open （断开）" ;
VAL_ 256 BMS_State 15 "Error" 14 "预留" 13 "预留" 12 "预留" 11 "预留" 10 "预留" 9 "预留" 8 "预留" 7 "预留" 6 "AfterRun" 5 "Fast_Charging" 4 "Slow_Charging" 3 "DisCharging" 2 "Precharging" 1 "Standby" 0 "Initialazation" ;
VAL_ 256 BMS_ChrFastState 3 "充电故障" 2 "充电完成" 1 "充电中" 0 "未充电" ;
VAL_ 256 BMS_SPreCharging 3 "预充失败" 2 "预充完成" 1 "预充中" 0 "未预充" ;
VAL_ 256 BMS_ChrSlowState 3 "充电故障" 2 "充电完成" 1 "充电中" 0 "未充电" ;
VAL_ 258 BMS_WakeUpSignal 1 "KL15_ON" 0 "KL15_OFF" ;
VAL_ 258 BMS_BalanceSts 1 "电池开启" 0 "电池关闭" ;
VAL_ 258 BMS_HVIL1_State 3 "预留" 2 "断开" 1 "闭合" 0 "未检测" ;
VAL_ 258 BMS_HVIL2_State 3 "预留" 2 "断开" 1 "闭合" 0 "未检测" ;
VAL_ 261 BMS_ChrRequest 7 "预留" 6 "预留" 5 "预留" 4 "预留" 3 "预留" 2 "预留" 1 "Request" 0 "No Request" ;
VAL_ 261 BMS_VCU_TotalEnergy 524287 "Invalid" ;
VAL_ 278 BMS_CellOverVolWaring 3 "三级故障" 2 "二级故障" 1 "一级故障" 0 "Not fault" ;
VAL_ 278 BMS_CellUnderVolWaring 3 "三级故障" 2 "二级故障" 1 "一级故障" 0 "Not fault" ;
VAL_ 278 BMS_TempOverWaring 3 "三级故障" 2 "二级故障" 1 "一级故障" 0 "Not fault" ;
VAL_ 278 BMS_TempUnderWaring 3 "三级故障" 2 "二级故障" 1 "一级故障" 0 "Not fault" ;
VAL_ 278 BMS_CellVolDevWaring 3 "三级故障" 2 "二级故障" 1 "一级故障" 0 "Not fault" ;
VAL_ 278 BMS_TempDveWaring 3 "三级故障" 2 "二级故障" 1 "一级故障" 0 "Not fault" ;
VAL_ 278 BMS_BattOverVolWaring 3 "三级故障" 2 "二级故障" 1 "一级故障" 0 "Not fault" ;
VAL_ 278 BMS_BattUnderVolWaring 3 "三级故障" 2 "二级故障" 1 "一级故障" 0 "Not fault" ;
VAL_ 278 BMS_DCChargePlugTempOverHigh 1 "故障" 0 "正常" ;
VAL_ 278 BMS_DisCharOverCurr 3 "三级故障" 2 "二级故障" 1 "一级故障" 0 "Not fault" ;
VAL_ 278 BMS_RegenOverCurr 3 "三级故障" 2 "二级故障" 1 "一级故障" 0 "Not fault" ;
VAL_ 278 BMS_InnerCANTimeout 1 "故障" 0 "正常" ;
VAL_ 278 BMS_ISOWaring 3 "三级故障" 2 "二级故障" 1 "一级故障" 0 "Not fault" ;
VAL_ 278 BMS_BCUHWFault 1 "故障" 0 "正常" ;
VAL_ 278 BMS_NegRelayFault 3 "预留" 2 "断开" 1 "黏连" 0 "正常" ;
VAL_ 278 BMS_PosRelayFault 3 "预留" 2 "断开" 1 "黏连" 0 "正常" ;
VAL_ 278 BMS_PreRelayFault 3 "预留" 2 "断开" 1 "黏连" 0 "正常" ;
VAL_ 278 BMS_LowVoltageMSD 1 "断开" 0 "正常" ;
VAL_ 278 BMS_CharPosRelayFault 3 "预留" 2 "断开" 1 "黏连" 0 "正常" ;
VAL_ 278 BMS_CharNegRelayFault 3 "预留" 2 "断开" 1 "黏连" 0 "正常" ;
VAL_ 278 BMS_BMUFault 1 "故障" 0 "正常" ;
VAL_ 278 BMS_VcuCANTimeout 1 "故障" 0 "正常" ;
VAL_ 278 BMS_BattHVDisaccord 1 "故障" 0 "正常" ;
VAL_ 278 BMS_SOClow 3 "三级故障" 2 "二级故障" 1 "一级故障" 0 "Not fault" ;
VAL_ 278 BMS_Mismatch 1 "Mismatch" 0 "Match" ;
VAL_ 278 BMS_SOCOverHigh 1 "SOC过高" 0 "SOC正常" ;
VAL_ 278 BMS_BattOverCharge 1 "动力电池过充" 0 "正常" ;
VAL_ 278 BMS_SOCSkip 1 "SOC跳变报警" 0 "正常" ;
VAL_ 278 BMS_CGOverCurr 1 "过流" 0 "正常" ;
VAL_ 278 BMS_LowVoltageFault 1 "异常" 0 "正常" ;
VAL_ 278 BMS_LiquidLeak 1 "漏液" 0 "正常" ;
VAL_ 278 BMS_CrashFault 1 "碰撞" 0 "正常" ;
VAL_ 278 BMS_ThermRunAway 1 "热失控" 0 "正常" ;
VAL_ 278 BMS_Maintenance 3 "预留" 2 "预留" 1 "电池保养" 0 "正常" ;
VAL_ 278 BMS_BusbarTempOverWaring 1 "过温" 0 "正常" ;
VAL_ 278 BMS_FuseFault 1 "故障" 0 "正常" ;
VAL_ 278 BMS_CurrSensorFault 3 "三级故障" 2 "二级故障" 1 "一级故障" 0 "Not fault" ;
VAL_ 276 BMS_thermalControlReq 7 "预留" 6 "预留" 5 "预留" 4 "预留" 3 "请求均温" 2 "请求冷却" 1 "请求加热" 0 "无请求" ;
VAL_ 276 BMS_InputWaterTemp 254 "无效" ;
VAL_ 276 BMS_OutputWaterTemp 254 "无效" ;
VAL_ 279 VCU_thermalControlReq 7 "Reserved" 6 "Reserved" 5 "Reserved" 4 "Reserved" 3 "请求均温" 2 "请求冷却" 1 "请求加热" 0 "无请求" ;
VAL_ 279 VCU_InputWaterTemp 255 "invalid" ;
VAL_ 279 VCU_OutputWaterTemp 255 "invalid" ;
VAL_ 288 MCU_MotorActualTorque 32767 "Failure" 32766 "Init" ;
VAL_ 288 MCU_MotorSpeed 65535 "Failure" 65534 "Init" ;
VAL_ 288 MCU_AuthSts 3 "Reserved" 2 "Auth Pass" 1 "Auth Not Pass" 0 "Init(认证正在进行）" ;
VAL_ 288 MCU_OverSpdWarning 1 "Warning" 0 "Not Warning" ;
VAL_ 288 MCU_InverterTempWarning 1 "Warning" 0 "Not Warning" ;
VAL_ 288 MCU_MotorTempWarning 1 "Warning" 0 "Not Warning" ;
VAL_ 288 MCU_OverTemp 1 "MCU请求点亮电机过热灯" 0 "MCU无点亮电机过热灯请求" ;
VAL_ 288 MCU_WorkSts 15 "Invalid" 10 "DisCharge" 7 "Failure" 6 "Afterrun" 5 "TrqCtl" 4 "nCtlInt" 3 "alOffsetCal" 2 "Standby" 1 "PreCharge" 0 "DrvInit" ;
VAL_ 288 MCU_FaultLevel 7 "Reserved" 6 "Reserved" 5 "Reserved" 4 "Level-4 error" 3 "Level-3 error(High)" 2 "Level-2 error(Limited Drive)" 1 "Level-1 error(Low)" 0 "No Error" ;
VAL_ 288 MCU_FaultLampOn 1 "MCU请求点亮电机故障灯" 0 "MCU无点亮电机故障灯请求" ;
VAL_ 288 MCU_HVLock 3 "预留" 2 "高压断开" 1 "高压闭合" 0 "未检测" ;
VAL_ 289 ESP_VehicleSpeed_Valid 1 "Invalid" 0 "Valid" ;
VAL_ 289 ESP_OFF 1 "On" 0 "Off" ;
VAL_ 289 ESP_ABS_Error 1 "Failure" 0 "No failure" ;
VAL_ 289 ESP_ABS_Intervention 1 "Active" 0 "Not active" ;
VAL_ 289 ESP_VDC_TCS_Error 1 "On" 0 "Off" ;
VAL_ 289 ESP_EBD_Error 1 "On" 0 "Off" ;
VAL_ 289 ESP_VDC_Intervention 1 "Active" 0 "Not active" ;
VAL_ 289 ESP_TCS_Intervention 1 "Active" 0 "Not active" ;
VAL_ 289 ESP_EBD_Intervention 1 "Active" 0 "Not active" ;
VAL_ 289 ESP_HDC_Status 3 "Reserved" 2 "On active braking" 1 "On not active braking" 0 "OFF" ;
VAL_ 289 ESP_HDC_Available 1 "Available" 0 "Not available" ;
VAL_ 289 ESP_EPBFailstatus 1 "error in EPB" 0 "No error" ;
VAL_ 289 ESP_EPBStatus 7 ":Reserved" 6 ":Reserved" 5 ":Reserved" 4 "Locking（卡钳正处于夹紧过程中" 3 "Releasing（卡钳正处于释放过程中）" 2 "Closed（卡钳处于夹紧状态）" 1 "Released（卡钳处于释放状态）" 0 "Undefined（未定义）" ;
VAL_ 289 ESP_VehicleStop 1 "2 or more wheels are standstill" 0 "Vehicle is not standstill" ;
VAL_ 289 ESP_VehicleStop_Valid 1 "Valid" 0 "Invalid" ;
VAL_ 289 ESP_MasterCyPressure_Valid 1 "Valid" 0 "Invalid" ;
VAL_ 289 ESP_WheelCyBrakeForce_Exist 1 "brake force exists" 0 "No brake force" ;
VAL_ 289 ESP_ESPLamp 1 "On（ESP Active）" 0 "Off（ESP Inactive）" ;
VAL_ 289 ESP_AVHstandbyStatus 1 "Standby" 0 "Not standby" ;
VAL_ 289 ESP_AVHActive 1 "Active" 0 "Not active" ;
VAL_ 289 ESP_AVH_availalbe 1 "Available" 0 "Not available" ;
VAL_ 289 ESP_HHC_Available 1 "Available" 0 "Not available" ;
VAL_ 289 ESP_HHCActive 1 "Active" 0 "Not active" ;
VAL_ 290 MCU_MaxAvailableTorque 2047 "Failure" 2046 "Init" ;
VAL_ 290 MCU_MinAvailableTorque 2047 "Failure" 2046 "Init" ;
VAL_ 290 MCU_DeratingTempCoolant 1 "Derating" 0 "Not Derating" ;
VAL_ 290 MCU_damping_En 1 "active" 0 "Not active" ;
VAL_ 290 MCU_DeratingTrqMin 1 "Derating" 0 "Not Derating" ;
VAL_ 290 MCU_DeratingTrqMax 1 "Derating" 0 "Not Derating" ;
VAL_ 290 MCU_DeratingOvrUdc 1 "Derating" 0 "Not Derating" ;
VAL_ 290 MCU_DeratingUndrUdc 1 "Derating" 0 "Not Derating" ;
VAL_ 290 MCU_DeratingOvrIdc 1 "Derating" 0 "Not Derating" ;
VAL_ 290 MCU_DeratingUndrIdc 1 "Derating" 0 "Not Derating" ;
VAL_ 290 MCU_DeratingTempEm 1 "Derating" 0 "Not Derating" ;
VAL_ 290 MCU_DeratingTempInv 1 "Derating" 0 "Not Derating" ;
VAL_ 290 MCU_MotorTorqueDeratingFlg 1 "derating" 0 "Not derating" ;
VAL_ 290 MCU_HVReady 1 "HV Ready" 0 "HV not Ready" ;
VAL_ 290 MCU_DeratingOverSpd 1 "Derating" 0 "Not Derating" ;
VAL_ 291 MCU_DC_linkVoltage 1023 "Failure" 1022 "Init" ;
VAL_ 291 MCU_DC_linkCurrent 2047 "Failure" 2046 "Init" ;
VAL_ 291 MCU_InverterTemp 255 "Failure" 254 "Init" ;
VAL_ 291 MCU_MotorTemp 255 "Failure" 254 "Init" ;
VAL_ 291 MCU_WaterTemp 255 "Failure" 254 "Init" ;
VAL_ 292 MCU_DBCTempU 255 "Failure" 0 "Init" ;
VAL_ 292 MCU_DBCTempV 255 "Failure" 0 "Init" ;
VAL_ 292 MCU_DBCTempW 255 "Failure" 0 "Init" ;
VAL_ 292 MCU_RotorTemp 255 "Failure" 254 "Init" ;
VAL_ 292 MCU_MotoroffsetSts 3 "reserved" 2 "Offset_Not_Accurate" 1 "Offset_Accurate" 0 "Init" ;
VAL_ 292 MCU_stGateDrv 3 "DisCharge" 2 "PWMrun" 1 "FreeWheel" 0 "ShortCircuit" ;
VAL_ 292 MCU_Motoroffset 1023 "Failure" 1022 "Init" ;
VAL_ 293 ESP_TorqueIncrease 32767 "Invalid" ;
VAL_ 293 ESP_TorqueIncreaseSt 1 "Active" 0 "Not active" ;
VAL_ 293 ESP_TorqueReqFast 32767 "Invalid" ;
VAL_ 293 ESP_TorqueReqFastSt 1 "Active" 0 "Not active" ;
VAL_ 293 ESP_TorqueReqSlow 32767 "Invalid" ;
VAL_ 293 ESP_TorqueReqSlowSt 1 "Active" 0 "Not active" ;
VAL_ 293 ESP_GearHoldRequest 1 "Shifting suppressed" 0 "Shifting not suppressed" ;
VAL_ 293 ESC_Gear_Request 4 "APADrvDirRqESP_Drive" 3 "APADrvDirRqESP_Neutral" 2 "APADrvDirRqESP_Reverse" 1 "APADrvDirRqESP_Park" 0 "APADrvDirRqESP_Idle" ;
VAL_ 320 VCU_CurrentMotorTorq 32767 "Invalid" ;
VAL_ 320 VCU_MaxMotorTorque 32767 "Invalid" ;
VAL_ 320 VCU_MinMotorTorque 32767 "Invalid" ;
VAL_ 321 VCU_DriverDemandTorq 32767 "Invalid" ;
VAL_ 321 VCU_QECACC 7 "Reserved5" 6 "Reserved4" 5 "Reserved3" 4 "Reserved2" 3 "Reserved1" 2 "Power system failure" 1 "communication failure" 0 "no error" ;
VAL_ 321 VCU_CreepSwitch 1 "开启" 0 "关闭" ;
VAL_ 321 VCU_GearShiftInProgress 1 "Gear is shifting" 0 "Gear not shifting" ;
VAL_ 321 VCU_ShiftInProgress_Status 1 "Invalid" 0 "Valid" ;
VAL_ 321 VCU_AccelerationModePer 127 "Invalid" ;
VAL_ 321 VCU_OverRide 1 "driver override" 0 "no override." ;
VAL_ 321 VCU_DriveMode 7 "Reserved" 6 "Reserved" 5 "Reserved" 4 "E_Pedal" 3 "Advanced Mode" 2 "Sport" 1 "ECO" 0 "Normal" ;
VAL_ 336 VCU_GearLeverPos 7 "Invalid" 6 "Reserved" 5 "Reserved" 4 "Reserved" 3 "D" 2 "N" 1 "R" 0 "P" ;
VAL_ 336 VCU_TortoiseLamp 1 "on" 0 "off" ;
VAL_ 336 VCU_Charge_Connect 3 "异常插枪" 2 "直流枪插入" 1 "交流枪插入" 0 "未插枪" ;
VAL_ 336 VCU_12VbatteryError 1 "Fault" 0 "No Fault" ;
VAL_ 336 VCU_ReadySts 1 "Ready" 0 "Not Ready" ;
VAL_ 336 VCU_MotorPumpError 1 "水泵故障" 0 "水泵无故障" ;
VAL_ 336 VCU_VacuumSysFaultLamp 1 "on" 0 "off" ;
VAL_ 336 VCU_GearP_EnterWarning 1 "on" 0 "off" ;
VAL_ 336 VCU_VehicleSysFaultLamp 1 "Fault" 0 "No Fault" ;
VAL_ 336 VCU_BattPumpError 1 "水泵故障" 0 "水泵无故障" ;
VAL_ 336 VCU_DriveableAlarm 1 "Active" 0 "NotActive" ;
VAL_ 336 VCU_GearFlashReq 3 "Reserved" 2 "request from EPB" 1 "request from SCM" 0 "No request" ;
VAL_ 336 VCU_Mileage 1023 "Invalid" ;
VAL_ 336 VCU_PowerConsumption 511 "Invalid" ;
VAL_ 336 VCU_MotorLoopCoolantLow 1 "Fault" 0 "No Fault" ;
VAL_ 336 VCU_BatLoopCoolantLow 1 "Fault" 0 "No Fault" ;
VAL_ 336 VCU_ChargeDepthSts 3 "预留" 2 "预留" 1 "长途旅行" 0 "日常行驶" ;
VAL_ 336 VCU_CloolantHighAlarm 1 "Alarm" 0 "Not Alarm" ;
VAL_ 336 VCU_TBOX_SlowChargeSt 15 "预留" 14 "预留" 13 "预留" 12 "预留" 11 "预留" 10 "预留" 9 "启动中" 8 "电源档位不正确" 7 "未插枪" 6 "其他故障" 5 "启动太频繁" 4 "充电设备不满足充电条件" 3 "已充满" 2 "高压系统故障" 1 "正在充电" 0 "未充电" ;
VAL_ 337 VCU_HVLock_ALL 3 "预留" 2 "高压断开" 1 "高压闭合" 0 "未检测" ;
VAL_ 337 VCU_BrakeLampReq 1 "on" 0 "off" ;
VAL_ 337 VCU_Intelligent_Charge_Sts 1 "开启" 0 "关闭" ;
VAL_ 337 VCU_HVLock_self 3 "预留" 2 "高压断开" 1 "高压闭合" 0 "未检测" ;
VAL_ 337 VCU_MotorPump_ErrorSts 7 "Reserved" 6 "空转" 5 "过压" 4 "过温" 3 "低压" 2 "过流" 1 "堵转" 0 "正常" ;
VAL_ 337 VCU_BrkSw_Sts 3 "Invalid" 2 "Reserved" 1 "Pressed" 0 "NotPressed" ;
VAL_ 337 VCU_BrkPed_Pos 255 "Invalid" ;
VAL_ 337 VCU_AccSW_Sts 3 "Invalid" 2 "reserved" 1 "pressed" 0 "not pressed" ;
VAL_ 337 VCU_AccPedPos 255 "Invalid" ;
VAL_ 337 VCU_TargetGear 7 "Invalid" 6 "Reserved" 5 "Reserved" 4 "Reserved" 3 "D" 2 "N" 1 "R" 0 "P" ;
VAL_ 337 VCU_APS_WorkStatus 22 "预留故障1" 21 "APS通讯故障" 20 "动力系统故障" 19 "人为介入停止" 18 "EPB释放超时" 17 "EPB故障" 16 "MCU反馈转速模式超时" 15 "分配给电机的功率不满足" 14 "车速不满足" 13 "MCU工作状态不满足" 12 "整车电源档位不满足" 11 "不在P档" 10 "VCU检测坡度不满足" 7 "正在脱手（由APS发起）" 6 "已激活状态:暂停" 5 "已激活状态:后退" 4 "已激活状态:前进" 3 "已激活状态:停止" 2 "正在握手" 1 "Standby待机状态" 0 "Init" ;
VAL_ 373 SAS_SteerWheelAngle 65535 "Invalid" ;
VAL_ 373 SAS_SteerWheelRotSpdStatus 1 "Invalid" 0 "Valid" ;
VAL_ 373 SAS_SASStsSnsr 1 "sensor value  valid" 0 "sensor value  Invalid" ;
VAL_ 373 EPS_SteeringTorqueValid 1 "Invalid" 0 "Vaild" ;
VAL_ 373 SAS_SASStsCal 1 "sensor calibrated" 0 "sensor not calibrated" ;
VAL_ 392 DCDC_ErrorLevel 7 "Reserved" 6 "Reserved" 5 "Reserved" 4 "Reserved" 3 "三级故障" 2 "二级故障" 1 "一级故障" 0 "无故障" ;
VAL_ 392 DCDC_stMode 7 "Reserved" 6 "Reserved" 5 "Reserved" 4 "Failure" 3 "Discharge" 2 "Buck" 1 "Standby" 0 "Init" ;
VAL_ 392 DCDC_DischargeMode 3 "泄放失败" 2 "泄放完成" 1 "泄放中" 0 "未泄放" ;
VAL_ 528 ACU_CrashStatus 1 "crash" 0 "no crash" ;
VAL_ 528 ACU_AirBagFailSts 3 "Not Used" 2 "lamp flashing（ACU自检）" 1 "lamp on" 0 "lamp off" ;
VAL_ 528 ACU_SBR_Driver 3 "Reserved" 2 "flash and buzzing" 1 "lamp on" 0 "lamp off" ;
VAL_ 528 ACU_SBR_Passenger 3 "Reserved" 2 "flash and buzzing" 1 "lamp on" 0 "lamp off" ;
VAL_ 528 ACU_SBR_RLPassenger 3 "Reserved" 2 "Reserved" 1 "lamp on" 0 "lamp off" ;
VAL_ 528 ACU_SBR_MidPassenger 3 "Reserved" 2 "Reserved" 1 "lamp on" 0 "lamp off" ;
VAL_ 528 ACU_SBR_RRPassenger 3 "Reserved" 2 "Reserved" 1 "lamp on" 0 "lamp off" ;
VAL_ 528 ACU_DrvSeatBeltSWSts 1 "Buckle on" 0 "Buckle off" ;
VAL_ 528 ACU_PsSeatBeltSWSts 1 "Buckle on" 0 "Buckle off" ;
VAL_ 528 ACU_RLPsSeatBeltSWSts 1 "Buckle on" 0 "Buckle off" ;
VAL_ 528 ACU_MidPsSeatBeltSWSts 1 "Buckle on" 0 "Buckle off" ;
VAL_ 528 ACU_RRPsSeatBeltSWSts 1 "Buckle on" 0 "Buckle off" ;
VAL_ 529 ABS_WheelSpeed_FL_Valid 1 "Invalid" 0 "Valid" ;
VAL_ 529 ABS_WheelSpeed_FR_Valid 1 "Invalid" 0 "Valid" ;
VAL_ 529 ABS_WheelSpeed_RL_Valid 1 "Invalid" 0 "Valid" ;
VAL_ 529 ABS_WheelSpeed_RR_Valid 1 "Invalid" 0 "Valid" ;
VAL_ 532 ESP_WheelDirection_FL 3 "Backward" 2 "Forward" 1 "Standstill" 0 "Undefined" ;
VAL_ 532 ESP_WheelDirection_FL_Valid 1 "Valid" 0 "Invalid" ;
VAL_ 532 ESP_WheelDirection_FR 3 "Backward" 2 "Forward" 1 "Standstill" 0 "Undefined" ;
VAL_ 532 ESP_WheelDirection_FR_Valid 1 "Valid" 0 "Invalid" ;
VAL_ 532 ESP_WheelDirection_RL 3 "Backward" 2 "Forward" 1 "Standstill" 0 "Undefined" ;
VAL_ 532 ESP_WheelDirection_RL_Valid 1 "Valid" 0 "Invalid" ;
VAL_ 532 ESP_WheelDirection_RR 3 "Backward" 2 "Forward" 1 "Standstill" 0 "Undefined" ;
VAL_ 532 ESP_WheelDirection_RR_Valid 1 "Valid" 0 "Invalid" ;
VAL_ 532 ESP_CDD_Intervention 1 "Active" 0 "Not active" ;
VAL_ 532 ESP_CDD_Available 1 "Available" 0 "Not available" ;
VAL_ 532 ESP_CDD_Error 1 "Error" 0 "No error" ;
VAL_ 532 ESP_CDDTempOff 1 "temp too high" 0 "not high" ;
VAL_ 532 ESP_WheelBrakeForce 65535 "Invalid" ;
VAL_ 532 ESP_VLC_EngTrqReq 32767 "Invalid" ;
VAL_ 532 ESP_VLC_EngTrqReqActive 1 "Active" 0 "Inactive" ;
VAL_ 532 ESP_VLC_Intervention 1 "Active" 0 "Not active" ;
VAL_ 532 ESP_VLC_Error 1 "Failure" 0 "No failure" ;
VAL_ 532 ESP_VLC_Available 1 "Available" 0 "Not available" ;
VAL_ 532 ESP_APA_CDD_active 1 "Active" 0 "Not Active" ;
VAL_ 579 ESP_YawrateValue_valid 1 "invalid" 0 "valid" ;
VAL_ 579 ESP_BrakelightRequest 1 "illuminate" 0 "not illuminate" ;
VAL_ 579 ESP_Intervention 1 "Active" 0 "Not active" ;
VAL_ 579 ESP_LongAccSensorValid 1 "invalid" 0 "valid" ;
VAL_ 579 ESP_LaterAccSensorValid 1 "invalid" 0 "valid" ;
VAL_ 579 ESP_AEB_Intervention 1 "Active" 0 "Not active" ;
VAL_ 579 ESC_APA_LC_Status 10 "LongCtrl_Error" 9 "LongCtrl_Active_ManeuverAccelerationAvoidance" 8 "LongCtrl_Active_ManeuverComfortBrake" 7 "LongCtrl_Active_ManeuverEmergencyBrake" 6 "LongCtrl_Active_RemoteParkOut" 5 "LongCtrl_Active_RemoteParkIn" 4 "LongCtrl_Active_AutomaticPark" 3 "LongCtrl_Active_ParkEmergencyBrake" 2 "LongCtrl_Active_ParkComfortBrake" 1 "LongCtrl_Standby" 0 "LongCtrl_Off" ;
VAL_ 642 SCM_CC_Switch 3 "Invalid" 2 "CC on/off" 1 "CC Cancel" 0 "Neutral" ;
VAL_ 642 SCM_Res_Set_Switch 3 "Invalid" 2 "SET/-" 1 "RES/+" 0 "Neutral" ;
VAL_ 642 SCM_PRND_req 7 "Invalid" 6 "Reserved" 5 "Reserved" 4 "D" 3 "N" 2 "R" 1 "P" 0 "Default" ;
VAL_ 734 HU_VCU_RemoteChrgLock 1 "unlock" 0 "no request" ;
VAL_ 734 HU_ChargeDepthSet 3 "预留" 2 "长途旅行" 1 "日常行驶" 0 "default" ;
VAL_ 734 HU_EnergyRecoveryPer 127 "default" ;
VAL_ 734 HU_SpeedLimitSW 3 "reserved" 2 "Limit" 1 "No Limit" 0 "default" ;
VAL_ 734 HU_LimitSpeedSet 255 "default" ;
VAL_ 734 HU_DriveMode 7 "预留" 6 "预留" 5 "E_Pedal" 4 "Advanced Mode" 3 "Sport" 2 "ECO" 1 "Normal" 0 "default" ;
VAL_ 734 HU_AccelerationModePer 127 "default" ;
VAL_ 734 HU_CreepSwitch 3 "reserved" 2 "开启" 1 "关闭" 0 "default" ;
VAL_ 734 HU_SubMileage_Reset 1 "Reset" 0 "default" ;
VAL_ 734 HU_DMS_SW 3 "reserved" 2 "开启" 1 "关闭" 0 "default" ;
VAL_ 784 BCM_SystemPowerMode 3 "START" 2 "ON" 1 "ACC" 0 "OFF" ;
VAL_ 784 BCM_AntiThelf_Sts 3 "Warning" 2 "Prearm" 1 "Arm" 0 "Disarm" ;
VAL_ 784 BCM_DriverLock_Sts 3 "Invalid" 2 "Lock" 1 "Unlock" 0 "Default" ;
VAL_ 784 BCM_StartRequest 1 "Request" 0 "No Request" ;
VAL_ 784 BCM_Hood_Sts 3 "Invalid" 2 "Close" 1 "Open" 0 "Default" ;
VAL_ 784 BCM_FL_Door_Sts 3 "Invalid" 2 "Close" 1 "Open" 0 "Default" ;
VAL_ 784 BCM_FR_Door_Sts 3 "Invalid" 2 "Close" 1 "Open" 0 "Default" ;
VAL_ 784 BCM_RL_Door_Sts 3 "Invalid" 2 "Close" 1 "Open" 0 "Default" ;
VAL_ 784 BCM_RR_Door_Sts 3 "Invalid" 2 "Close" 1 "Open" 0 "Default" ;
VAL_ 805 WPTC_RunSts 3 "预留" 2 "故障" 1 "运行" 0 "关闭" ;
VAL_ 805 WPTC_HVSts 3 "高压欠压故障" 2 "高压过压故障" 1 "已供电" 0 "未供电" ;
VAL_ 805 WPTC_COM_VCU_Lost 1 "异常" 0 "正常" ;
VAL_ 805 WPTC_CUR_Over 1 "异常" 0 "正常" ;
VAL_ 805 WPTC_Temp_PCB_High 1 "异常" 0 "正常" ;
VAL_ 805 WPTC_OutletTemp_High 1 "异常" 0 "正常" ;
VAL_ 805 WPTC_InputTemp_High 1 "异常" 0 "正常" ;
VAL_ 853 TBOX_TimeSyncSts 1 "start  sync" 0 "Default" ;
VAL_ 905 DCDC_DeratingSts 1 "derating" 0 "normal" ;
VAL_ 928 ICM_ODOTotal 16777215 "Invalid" ;
VAL_ 928 ICM_DisPlayVehicleSpeed 4095 "Invalid" ;
VAL_ 928 ICM_Error_Sts 3 "Invalid" 2 "Error" 1 "No Error" 0 "Default" ;
VAL_ 928 ICM_SubMileage_Reset 1 "Reset" 0 "default" ;
VAL_ 1027 VCU_NM_ALIVE 1 "Active" 0 "Not active" ;
VAL_ 1027 VCU_NM_RING 1 "Active" 0 "Not active" ;
VAL_ 1027 VCU_NM_LIMPHOME 1 "Active" 0 "Not active" ;
VAL_ 1027 VCU_NM_SLEEP_Ind 1 "Active" 0 "Not active" ;
VAL_ 1027 VCU_NM_SLEEP_ACK 1 "Active" 0 "Not active" ;
VAL_ 1032 GW_PT_NM_ALIVE 1 "Active" 0 "Not active" ;
VAL_ 1032 GW_PT_NM_RING 1 "Active" 0 "Not active" ;
VAL_ 1032 GW_PT_NM_LIMPHOME 1 "Active" 0 "Not active" ;
VAL_ 1032 GW_PT_NM_SLEEP_Ind 1 "Active" 0 "Not active" ;
VAL_ 1032 GW_PT_NM_SLEEP_ACK 1 "Active" 0 "Not active" ;
VAL_ 1299 BMS_MaxTemp 254 "invalid" ;
VAL_ 1299 BMS_MinTemp 254 "invalid" ;
VAL_ 1299 BMS_BattTempDev 254 "invalid" ;
VAL_ 1299 BMS_CCTemp1 254 "invalid" ;
VAL_ 1299 BMS_CCTemp2 254 "invalid" ;
VAL_ 1360 OBC_ChrgFailLevel 7 "预留" 6 "预留" 5 "预留" 4 "预留" 3 "三级故障" 2 "二级故障" 1 "一级故障" 0 "无故障" ;
VAL_ 1360 OBC_CCLineSts 1 "Connected" 0 "Not connected" ;
VAL_ 1360 OBC_DeratingSts 1 "Derating" 0 "No derating" ;
VAL_ 1360 OBC_ChrgSts 7 "Reserved" 6 "Aftercharge" 5 "Shutdown" 4 "Failure" 3 "PowerActive" 2 "Standby" 1 "PreStart" 0 "Initialization" ;
VAL_ 1360 OBC_OBCStsCPLine 1 "Connected" 0 "Not connected" ;
VAL_ 1360 OBC_S2Sts 1 "Closed" 0 "Opened" ;
VAL_ 1360 OBC_ChrgAllowedSts 1 "Allowed" 0 "NotAllowed" ;
VAL_ 1377 VCU_IG1input 1 "active" 0 "inactive" ;
VAL_ 1377 VCU_startinput 1 "active" 0 "inactive" ;
VAL_ 1377 VCU_OBCwakeupVCU 1 "active" 0 "inactive" ;
VAL_ 1377 VCU_VCUwakeupOBC 1 "active" 0 "inactive" ;
VAL_ 1377 VCU_VCUwakeupBMS 1 "active" 0 "inactive" ;
VAL_ 1377 VCU_VCUwakeupMCU 1 "active" 0 "inactive" ;
VAL_ 1377 VCU_VacuumPumpRelay 1 "active" 0 "inactive" ;
VAL_ 1377 VCU_WPTCRelay 1 "active" 0 "inactive" ;
VAL_ 1378 MCU_MotorSts_GBT 255 "无效" 254 "异常；" 253 "Reserved；" 252 "Reserved；" 251 "Reserved；" 250 "Reserved；" 249 "Reserved；" 248 "Reserved；" 247 "Reserved；" 246 "Reserved；" 245 "Reserved；" 244 "Reserved；" 243 "Reserved；" 242 "Reserved；" 241 "Reserved；" 240 "Reserved；" 239 "Reserved；" 238 "Reserved；" 237 "Reserved；" 236 "Reserved；" 235 "Reserved；" 234 "Reserved；" 233 "Reserved；" 232 "Reserved；" 231 "Reserved；" 230 "Reserved；" 229 "Reserved；" 228 "Reserved；" 227 "Reserved；" 226 "Reserved；" 225 "Reserved；" 224 "Reserved；" 223 "Reserved；" 222 "Reserved；" 221 "Reserved；" 220 "Reserved；" 219 "Reserved；" 218 "Reserved；" 217 "Reserved；" 216 "Reserved；" 215 "Reserved；" 214 "Reserved；" 213 "Reserved；" 212 "Reserved；" 211 "Reserved；" 210 "Reserved；" 209 "Reserved；" 208 "Reserved；" 207 "Reserved；" 206 "Reserved；" 205 "Reserved；" 204 "Reserved；" 203 "Reserved；" 202 "Reserved；" 201 "Reserved；" 200 "Reserved；" 199 "Reserved；" 198 "Reserved；" 197 "Reserved；" 196 "Reserved；" 195 "Reserved；" 194 "Reserved；" 193 "Reserved；" 192 "Reserved；" 191 "Reserved；" 190 "Reserved；" 189 "Reserved；" 188 "Reserved；" 187 "Reserved；" 186 "Reserved；" 185 "Reserved；" 184 "Reserved；" 183 "Reserved；" 182 "Reserved；" 181 "Reserved；" 180 "Reserved；" 179 "Reserved；" 178 "Reserved；" 177 "Reserved；" 176 "Reserved；" 175 "Reserved；" 174 "Reserved；" 173 "Reserved；" 172 "Reserved；" 171 "Reserved；" 170 "Reserved；" 169 "Reserved；" 168 "Reserved；" 167 "Reserved；" 166 "Reserved；" 165 "Reserved；" 164 "Reserved；" 163 "Reserved；" 162 "Reserved；" 161 "Reserved；" 160 "Reserved；" 159 "Reserved；" 158 "Reserved；" 157 "Reserved；" 156 "Reserved；" 155 "Reserved；" 154 "Reserved；" 153 "Reserved；" 152 "Reserved；" 151 "Reserved；" 150 "Reserved；" 149 "Reserved；" 148 "Reserved；" 147 "Reserved；" 146 "Reserved；" 145 "Reserved；" 144 "Reserved；" 143 "Reserved；" 142 "Reserved；" 141 "Reserved；" 140 "Reserved；" 139 "Reserved；" 138 "Reserved；" 137 "Reserved；" 136 "Reserved；" 135 "Reserved；" 134 "Reserved；" 133 "Reserved；" 132 "Reserved；" 131 "Reserved；" 130 "Reserved；" 129 "Reserved；" 128 "Reserved；" 127 "Reserved；" 126 "Reserved；" 125 "Reserved；" 124 "Reserved；" 123 "Reserved；" 122 "Reserved；" 121 "Reserved；" 120 "Reserved；" 119 "Reserved；" 118 "Reserved；" 117 "Reserved；" 116 "Reserved；" 115 "Reserved；" 114 "Reserved；" 113 "Reserved；" 112 "Reserved；" 111 "Reserved；" 110 "Reserved；" 109 "Reserved；" 108 "Reserved；" 107 "Reserved；" 106 "Reserved；" 105 "Reserved；" 104 "Reserved；" 103 "Reserved；" 102 "Reserved；" 101 "Reserved；" 100 "Reserved；" 99 "Reserved；" 98 "Reserved；" 97 "Reserved；" 96 "Reserved；" 95 "Reserved；" 94 "Reserved；" 93 "Reserved；" 92 "Reserved；" 91 "Reserved；" 90 "Reserved；" 89 "Reserved；" 88 "Reserved；" 87 "Reserved；" 86 "Reserved；" 85 "Reserved；" 84 "Reserved；" 83 "Reserved；" 82 "Reserved；" 81 "Reserved；" 80 "Reserved；" 79 "Reserved；" 78 "Reserved；" 77 "Reserved；" 76 "Reserved；" 75 "Reserved；" 74 "Reserved；" 73 "Reserved；" 72 "Reserved；" 71 "Reserved；" 70 "Reserved；" 69 "Reserved；" 68 "Reserved；" 67 "Reserved；" 66 "Reserved；" 65 "Reserved；" 64 "Reserved；" 63 "Reserved；" 62 "Reserved；" 61 "Reserved；" 60 "Reserved；" 59 "Reserved；" 58 "Reserved；" 57 "Reserved；" 56 "Reserved；" 55 "Reserved；" 54 "Reserved；" 53 "Reserved；" 52 "Reserved；" 51 "Reserved；" 50 "Reserved；" 49 "Reserved；" 48 "Reserved；" 47 "Reserved；" 46 "Reserved；" 45 "Reserved；" 44 "Reserved；" 43 "Reserved；" 42 "Reserved；" 41 "Reserved；" 40 "Reserved；" 39 "Reserved；" 38 "Reserved；" 37 "Reserved；" 36 "Reserved；" 35 "Reserved；" 34 "Reserved；" 33 "Reserved；" 32 "Reserved；" 31 "Reserved；" 30 "Reserved；" 29 "Reserved；" 28 "Reserved；" 27 "Reserved；" 26 "Reserved；" 25 "Reserved；" 24 "Reserved；" 23 "Reserved；" 22 "Reserved；" 21 "Reserved；" 20 "Reserved；" 19 "Reserved；" 18 "Reserved；" 17 "Reserved；" 16 "Reserved；" 15 "Reserved；" 14 "Reserved；" 13 "Reserved；" 12 "Reserved；" 11 "Reserved；" 10 "Reserved；" 9 "Reserved；" 8 "Reserved；" 7 "Reserved；" 6 "Reserved；" 5 "Reserved；" 4 "准备；" 3 "关闭；" 2 "发电；" 1 "耗电；" 0 "Reserved；" ;
VAL_ 1378 MCU_MotoroffsetCalReq 1 "True" 0 "False" ;
VAL_ 1504 BMS_SWVersion_Supplier 10 "捷新/捷能" ;
VAL_ 1504 BMS_SWVersion_Main 3 "SOP" 2 "PVS-C样" 1 "PT-A/B样" ;
VAL_ 1504 BMS_HWVersion_Supplier 10 "捷新/捷能" ;
VAL_ 1504 BMS_HWVersion_Main 3 "SOP" 2 "PVS-C样" 1 "PT-A/B样" ;
VAL_ 1504 BMS_PackEnergy 77 "77kWh" 54 "54kWh" ;
VAL_ 1504 BMS_CellSupplier 17 "捷威" 16 "万向" ;
VAL_ 1552 OBC_CC_Status 7 "预留" 6 "CC接地" 5 "100Ohm" 4 "220Ohm" 3 "680Ohm" 2 "1500Ohm" 1 "半连接" 0 "无连接" ;
VAL_ 1553 OBC_SocketTempHig 1 "Fault" 0 "Not Fault" ;
VAL_ 1553 OBC_InputVolLow 1 "Fault" 0 "Not Fault" ;
VAL_ 1553 OBC_HardTempHig 1 "Fault" 0 "Not Fault" ;
VAL_ 1553 OBC_OutputShorCir 1 "Fault" 0 "Not Fault" ;
VAL_ 1553 OBC_OutputVolHig 1 "Fault" 0 "Not Fault" ;
VAL_ 1553 OBC_OutputVolLow 1 "Fault" 0 "Not Fault" ;
VAL_ 1553 OBC_PFCOutputVolHig 1 "Fault" 0 "Not Fault" ;
VAL_ 1553 OBC_PFCOutputVolLow 1 "Fault" 0 "Not Fault" ;
VAL_ 1553 OBC_CommTimeOut 1 "Fault" 0 "Not Fault" ;
VAL_ 1553 OBC_InputCurHig 1 "Fault" 0 "Not Fault" ;
VAL_ 1553 OBC_InputVolHig 1 "Fault" 0 "Not Fault" ;
VAL_ 1553 OBC_BMSVolLow 1 "Fault" 0 "Not Fault" ;
VAL_ 1553 OBC_BMSVolHig 1 "Fault" 0 "Not Fault" ;
VAL_ 1553 OBC_ContraryConnect 1 "Fault" 0 "Not Fault" ;
VAL_ 1553 OBC_InsideComTimeOut 1 "Fault" 0 "Not Fault" ;
VAL_ 1553 OBC_ElockFail 1 "Fault" 0 "Not Fault" ;
VAL_ 1553 OBC_HardFail 1 "Fault" 0 "Not Fault" ;
VAL_ 1553 OBC_OutputCurHig 1 "Fault" 0 "Not Fault" ;
VAL_ 1556 OBC_ElockSts 3 "Locked Fail" 2 "Unlocked  Fail" 1 "Locked" 0 "Unlocked" ;
VAL_ 1556 OBC_ChrgLockSts 7 "预留" 6 "解锁失败" 5 "上锁失败" 4 "正在上锁" 3 "正在解锁" 2 "上锁" 1 "解锁" 0 "默认" ;
VAL_ 1556 OBC_RecoTimingSts 1 "Active" 0 "Inactive" ;
VAL_ 1632 DCDC_OverTemp 1 "Fault" 0 "Not Fault" ;
VAL_ 1632 DCDC_DischargeFail 1 "Fault" 0 "Not Fault" ;
VAL_ 1632 DCDC_TBOX_WorkSts 3 "无效" 2 "异常" 1 "工作" 0 "断开" ;
VAL_ 1632 DCDC_TBOX_TempFault 1 "Fault" 0 "Not Fault" ;
VAL_ 1632 DCDC_InsideVolHig 1 "Fault" 0 "Not Fault" ;
VAL_ 1632 DCDC_InsideVolLow 1 "Fault" 0 "Not Fault" ;
VAL_ 1632 DCDC_OutputCurHig 1 "Fault" 0 "Not Fault" ;
VAL_ 1632 DCDC_OutputVolHig 1 "Fault" 0 "Not Fault" ;
VAL_ 1632 DCDC_OutputVolLow 1 "Fault" 0 "Not Fault" ;
VAL_ 1632 DCDC_InputCurHig 1 "Fault" 0 "Not Fault" ;
VAL_ 1632 DCDC_InputVolHig 1 "Fault" 0 "Not Fault" ;
VAL_ 1632 DCDC_InputVolLow 1 "Fault" 0 "Not Fault" ;
VAL_ 1632 DCDC_OutputOpen 1 "Fault" 0 "Not Fault" ;
VAL_ 1632 DCDC_HardFail 1 "Fault" 0 "Not Fault" ;
VAL_ 1632 DCDC_InsideShotCirc 1 "Fault" 0 "Not Fault" ;
VAL_ 1632 DCDC_OutputShotCirc 1 "Fault" 0 "Not Fault" ;
VAL_ 1632 DCDC_CommunTimeOut 1 "Fault" 0 "Not Fault" ;
VAL_ 1632 DCDC_InsideCurHig 1 "Fault" 0 "Not Fault" ;
